VERSION ""

NS_ :

BS_:

BU_: CH DIPF DIPR ETH FC HVI HVS PARTY SDCV VEH VIRT

BO_ 938 HVP_alertMatrix1: 8 VEH
 SG_ HVP_w051_shuntThermistorMia : 50|1@1+ (1,0) [0|1] ""  gtw
 SG_ HVP_w050_fcCtrCloseFailed : 49|1@1+ (1,0) [0|1] ""  gtw
 SG_ HVP_w049_packCtrCloseFailed : 48|1@1+ (1,0) [0|1] ""  gtw
 SG_ HVP_w048_logUploadRequest : 47|1@1+ (1,0) [0|1] ""  gtw
 SG_ HVP_w047_passivePyroDeploy : 46|1@1+ (1,0) [0|1] ""  gtw
 SG_ HVP_w046_shuntOverTemperature : 45|1@1+ (1,0) [0|1] ""  gtw
 SG_ HVP_w045_dcLinkOverVoltage : 44|1@1+ (1,0) [0|1] ""  gtw
 SG_ HVP_w044_fcContactorForceOpen : 43|1@1+ (1,0) [0|1] ""  gtw
 SG_ HVP_w043_packContactorForceOpen : 42|1@1+ (1,0) [0|1] ""  gtw
 SG_ HVP_w042_fcCtrCloseBlocked : 41|1@1+ (1,0) [0|1] ""  gtw
 SG_ HVP_w041_packCtrCloseBlocked : 40|1@1+ (1,0) [0|1] ""  gtw
 SG_ HVP_w040_FcContactorFellOpen : 39|1@1+ (1,0) [0|1] ""  gtw
 SG_ HVP_w039_PackContactorFellOpen : 38|1@1+ (1,0) [0|1] ""  gtw
 SG_ HVP_w038_CpilFault : 37|1@1+ (1,0) [0|1] ""  gtw
 SG_ HVP_w037_pyroFuseFailedToBlow : 36|1@1+ (1,0) [0|1] ""  gtw
 SG_ HVP_w036_pyroFuseBlown : 35|1@1+ (1,0) [0|1] ""  gtw
 SG_ HVP_w035_packContHwFault : 34|1@1+ (1,0) [0|1] ""  gtw
 SG_ HVP_w034_robinOverVoltageFault : 33|1@1+ (1,0) [0|1] ""  gtw
 SG_ HVP_w033_fcContHwFault : 32|1@1+ (1,0) [0|1] ""  gtw
 SG_ HVP_w032_ShuntHwAndBmsMiaFault : 31|1@1+ (1,0) [0|1] ""  gtw
 SG_ HVP_w031_packNegCtrArcFault : 30|1@1+ (1,0) [0|1] ""  gtw
 SG_ HVP_w030_PackPosCtrArcFault : 29|1@1+ (1,0) [0|1] ""  gtw
 SG_ HVP_w029_EnsMiaFault : 28|1@1+ (1,0) [0|1] ""  gtw
 SG_ HVP_w028_PackVoltMismatchFault : 27|1@1+ (1,0) [0|1] ""  gtw
 SG_ HVP_w027_BmsHvsMiaFault : 26|1@1+ (1,0) [0|1] ""  gtw
 SG_ HVP_w026_HvilFault : 25|1@1+ (1,0) [0|1] ""  gtw
 SG_ HVP_w025_VerSupplyFault : 24|1@1+ (1,0) [0|1] ""  gtw
 SG_ HVP_w024_Supply12vFault : 23|1@1+ (1,0) [0|1] ""  gtw
 SG_ HVP_w022_hvsMiaFault : 21|1@1+ (1,0) [0|1] ""  gtw
 SG_ HVP_w021_PyroMiaFault : 20|1@1+ (1,0) [0|1] ""  gtw
 SG_ HVP_w020_ShuntHwMiaFault : 19|1@1+ (1,0) [0|1] ""  gtw
 SG_ HVP_w019_CpFault : 18|1@1+ (1,0) [0|1] ""  gtw
 SG_ HVP_w018_PcsFault : 17|1@1+ (1,0) [0|1] ""  gtw
 SG_ HVP_w017_BmsFault : 16|1@1+ (1,0) [0|1] ""  gtw
 SG_ HVP_w016_PcsMiaFault : 15|1@1+ (1,0) [0|1] ""  gtw
 SG_ HVP_w015_CpMiaFault : 14|1@1+ (1,0) [0|1] ""  gtw
 SG_ HVP_w014_BmsHviMiaFault : 13|1@1+ (1,0) [0|1] ""  gtw
 SG_ HVP_w013_BmbMismatchFault : 12|1@1+ (1,0) [0|1] ""  gtw
 SG_ HVP_w012_SecondaryBmbMiaFault : 11|1@1+ (1,0) [0|1] ""  gtw
 SG_ HVP_w011_PrimaryBmbMiaFault : 10|1@1+ (1,0) [0|1] ""  gtw
 SG_ HVP_w010_UnderVoltageFault : 9|1@1+ (1,0) [0|1] ""  gtw
 SG_ HVP_w009_OverVoltageFault : 8|1@1+ (1,0) [0|1] ""  gtw
 SG_ HVP_w008_OverTemperatureFault : 7|1@1+ (1,0) [0|1] ""  gtw
 SG_ HVP_w007_OverCurrentFault : 6|1@1+ (1,0) [0|1] ""  gtw
 SG_ HVP_w006_OverChargeCurrentFault : 5|1@1+ (1,0) [0|1] ""  gtw
 SG_ HVP_w005_OverDchgCurrentFault : 4|1@1+ (1,0) [0|1] ""  gtw
 SG_ HVP_w004_CrashEvent : 3|1@1+ (1,0) [0|1] ""  gtw
 SG_ HVP_w003_SwAssertion : 2|1@1+ (1,0) [0|1] ""  gtw
 SG_ HVP_w002_UnusedAlert2 : 1|1@1+ (1,0) [0|1] ""  gtw
 SG_ HVP_w001_WatchdogReset : 0|1@1+ (1,0) [0|1] ""  gtw

BO_ 768 BMS_info: 8 VEH
 SG_ BMS_componentId m10 : 48|16@1+ (1,0) [0|65535] ""  gtw
 SG_ BMS_subUsageId m11 : 48|16@1+ (1,0) [0|65535] ""  di
 SG_ BMS_usageId m11 : 32|16@1+ (1,0) [0|65535] ""  gtw
 SG_ BMS_hardwareId m10 : 32|16@1+ (1,0) [0|65535] ""  gtw
 SG_ BMS_bootCrc m20 : 32|32@1+ (1,0) [0|4294967295] ""  gtw
 SG_ BMS_appCrc m13 : 32|32@1+ (1,0) [0|4294967295] ""  gtw
 SG_ BMS_assemblyId m11 : 24|8@1+ (1,0) [0|255] ""  gtw
 SG_ BMS_buildConfigId m10 : 16|16@1+ (1,0) [0|65535] ""  gtw
 SG_ BMS_pcbaId m11 : 16|8@1+ (1,0) [0|255] ""  gtw
 SG_ BMS_buildType m10 : 8|3@1+ (1,0) [0|4] ""  gtw
 SG_ BMS_bootGitHash m18 : 8|56@1+ (1,0) [0|72057594037927935] ""  gtw
 SG_ BMS_platformType m13 : 8|8@1+ (1,0) [0|255] ""  gtw
 SG_ BMS_bootUdsProtoVersion m20 : 8|8@1+ (1,0) [0|255] ""  gtw
 SG_ BMS_appGitHash m17 : 8|56@1+ (1,0) [0|72057594037927935] ""  gtw
 SG_ BMS_infoIndex M : 0|8@1+ (1,0) [0|255] ""  gtw

BO_ 1251 VCRIGHT_seatStatus: 8 VEH
 SG_ VCRIGHT_lumbarDevMaxPumpPressB m4 : 55|1@1+ (1,0) [0|1] ""  gtw
 SG_ VCRIGHT_lumbarDevMaxPumpPressA m4 : 54|1@1+ (1,0) [0|1] ""  gtw
 SG_ VCRIGHT_lumbarGeneralErr m4 : 53|1@1+ (1,0) [0|1] ""  gtw
 SG_ VCRIGHT_frontSeatTrackLog m0 : 52|1@1+ (1,0) [0|1] ""  gtw
 SG_ VCRIGHT_frontSeatLiftLog m2 : 52|1@1+ (1,0) [0|1] ""  gtw
 SG_ VCRIGHT_lumbarMinPErr m4 : 52|1@1+ (1,0) [0|1] ""  gtw
 SG_ VCRIGHT_frontSeatTiltLog m3 : 52|1@1+ (1,0) [0|1] ""  gtw
 SG_ VCRIGHT_frontSeatBackLog m1 : 52|1@1+ (1,0) [0|1] ""  gtw
 SG_ VCRIGHT_lumbarMaxOperatingPErr m4 : 51|1@1+ (1,0) [0|1] ""  gtw
 SG_ VCRIGHT_frontSeatBackCalibrated m1 : 51|1@1+ (1,0) [0|1] ""  gtw
 SG_ VCRIGHT_frontSeatTiltCalibrated m3 : 51|1@1+ (1,0) [0|1] ""  gtw
 SG_ VCRIGHT_frontSeatLiftCalibrated m2 : 51|1@1+ (1,0) [0|1] ""  gtw
 SG_ VCRIGHT_frontSeatTrackCalibrated m0 : 51|1@1+ (1,0) [0|1] ""  gtw
 SG_ VCRIGHT_lumbarOvercurrentErr m4 : 50|1@1+ (1,0) [0|1] ""  gtw
 SG_ VCRIGHT_lumbarMaxPErr m4 : 49|1@1+ (1,0) [0|1] ""  gtw
 SG_ VCRIGHT_frontSeatTrackState m0 : 48|3@1+ (1,0) [0|5] ""  gtw
 SG_ VCRIGHT_frontSeatLiftState m2 : 48|3@1+ (1,0) [0|5] ""  gtw
 SG_ VCRIGHT_lumbarActiveTooLongErr m4 : 48|1@1+ (1,0) [0|1] ""  gtw
 SG_ VCRIGHT_frontSeatTiltState m3 : 48|3@1+ (1,0) [0|5] ""  gtw
 SG_ VCRIGHT_frontSeatBackState m1 : 48|3@1+ (1,0) [0|5] ""  gtw
 SG_ VCRIGHT_frontSeatTiltPosReal m5 : 40|12@1- (0.1,0) [-204.8|204.7] "deg"  gtw
 SG_ VCRIGHT_frontSeatTiltDuty m3 : 36|12@1- (0.1,0) [-204.8|204.7] "%"  gtw
 SG_ VCRIGHT_frontSeatBackDuty m1 : 36|12@1- (0.1,0) [-204.8|204.7] "%"  gtw
 SG_ VCRIGHT_frontSeatLiftDuty m2 : 36|12@1- (0.1,0) [-204.8|204.7] "%"  gtw
 SG_ VCRIGHT_frontSeatTrackDuty m0 : 36|12@1- (0.1,0) [-204.8|204.7] "%"  gtw
 SG_ VCRIGHT_lumbarBPressureHpa m4 : 32|16@1+ (1,0) [0|65535] ""  gtw
 SG_ VCRIGHT_frontSeatLiftPosReal m5 : 28|12@1- (1,0) [-2048|2047] "mm"  gtw
 SG_ VCRIGHT_frontSeatLiftCurrent m2 : 24|12@1- (0.01,0) [-20.48|20.47] "A"  gtw
 SG_ VCRIGHT_frontSeatTrackCurrent m0 : 24|12@1- (0.01,0) [-20.48|20.47] "A"  gtw
 SG_ VCRIGHT_frontSeatBackCurrent m1 : 24|12@1- (0.01,0) [-20.48|20.47] "A"  gtw
 SG_ VCRIGHT_frontSeatTiltCurrent m3 : 24|12@1- (0.01,0) [-20.48|20.47] "A"  gtw
 SG_ VCRIGHT_frontSeatBackPosReal m5 : 16|12@1- (0.1,0) [-204.8|204.7] "deg"  gtw
 SG_ VCRIGHT_lumbarAPressureHpa m4 : 16|16@1+ (1,0) [0|65535] ""  gtw
 SG_ VCRIGHT_frontSeatTiltPos m3 : 8|16@1- (1,0) [-32768|32767] ""  gtw
 SG_ VCRIGHT_lumbarBState m4 : 8|3@1+ (1,0) [0|5] ""  gtw
 SG_ VCRIGHT_frontSeatBackPos m1 : 8|16@1- (1,0) [-32768|32767] ""  gtw
 SG_ VCRIGHT_frontSeatTrackPos m0 : 8|16@1- (1,0) [-32768|32767] ""  gtw
 SG_ VCRIGHT_frontSeatLiftPos m2 : 8|16@1- (1,0) [-32768|32767] ""  gtw
 SG_ VCRIGHT_frontSeatTrackPosReal m5 : 3|12@1- (1,0) [-2048|2047] "mm"  gtw
 SG_ VCRIGHT_lumbarAState m4 : 3|3@1+ (1,0) [0|5] ""  gtw
 SG_ VCRIGHT_seatStatusIndex M : 0|3@1+ (1,0) [0|5] ""  X

BO_ 850 BMS_energyStatus: 8 VEH
 SG_ BMS_idealEnergyRemaining m0 : 48|16@1+ (0.02,0) [0|102.2] "KWh"  gtw
 SG_ BMS_nominalEnergyRemaining m0 : 32|16@1+ (0.02,0) [0|102.2] "KWh"  gtw
 SG_ BMS_expectedEnergyRemaining m1 : 32|16@1+ (0.02,0) [0|102.2] "KWh"  gtw
 SG_ BMS_energyBuffer m1 : 16|16@1+ (0.01,0) [0|25.4] "KWh"  gtw
 SG_ BMS_nominalFullPackEnergy m0 : 16|16@1+ (0.02,0) [0|102.2] "KWh"  gtw
 SG_ BMS_energyIndex M : 0|8@1+ (1,0) [0|2] ""  X

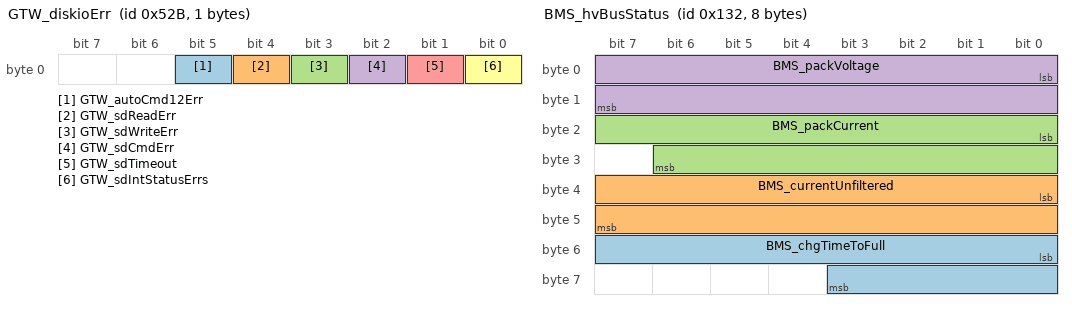
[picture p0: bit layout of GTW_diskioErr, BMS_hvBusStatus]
BO_ 1323 GTW_diskioErr: 1 VEH
 SG_ GTW_autoCmd12Err : 5|1@1+ (1,0) [0|1] ""  X
 SG_ GTW_sdReadErr : 4|1@1+ (1,0) [0|1] ""  X
 SG_ GTW_sdWriteErr : 3|1@1+ (1,0) [0|1] ""  X
 SG_ GTW_sdCmdErr : 2|1@1+ (1,0) [0|1] ""  X
 SG_ GTW_sdTimeout : 1|1@1+ (1,0) [0|1] ""  X
 SG_ GTW_sdIntStatusErrs : 0|1@1+ (1,0) [0|1] ""  X

BO_ 1328 VCSEC_alertLog: 8 VEH
 SG_ VCSEC_a041_CPULoadNVMMTask m41 : 56|8@1+ (1,0) [0|255] ""  gtw
 SG_ VCSEC_a022_TaskInitError4 m22 : 56|8@1+ (1,0) [0|255] ""  gtw
 SG_ VCSEC_a179_signingKeySlot m179 : 56|8@1+ (1,0) [0|255] ""  gtw
 SG_ VCSEC_a180_signingKeySlot m180 : 56|8@1+ (1,0) [0|255] ""  gtw
 SG_ VCSEC_a042_UsageNVMMTask m42 : 56|8@1+ (1,0) [0|255] ""  gtw
 SG_ VCSEC_a041_CPULoad1000msTask m41 : 48|8@1+ (1,0) [0|255] ""  gtw
 SG_ VCSEC_a042_UsageUDSTask m42 : 48|8@1+ (1,0) [0|255] ""  gtw
 SG_ VCSEC_a022_TaskInitError3 m22 : 48|8@1+ (1,0) [0|255] ""  gtw
 SG_ VCSEC_a000_alertDataW2 m0 : 48|16@1+ (1,0) [0|65535] ""  X
 SG_ VCSEC_a003_Data m3 : 48|16@1+ (1,0) [0|65535] ""  gtw
 SG_ VCSEC_a179_whitelistSlot m179 : 48|8@1+ (1,0) [0|255] ""  gtw
 SG_ VCSEC_a180_whitelistSlot m180 : 48|8@1+ (1,0) [0|255] ""  gtw
 SG_ VCSEC_a178_signingKeySlot m178 : 48|8@1+ (1,0) [0|255] ""  gtw
 SG_ VCSEC_a063_faulted m63 : 43|1@1+ (1,0) [0|1] ""  gtw
 SG_ VCSEC_a063_stuckActive m63 : 42|1@1+ (1,0) [0|1] ""  gtw
 SG_ VCSEC_a063_indeterminate m63 : 41|1@1+ (1,0) [0|1] ""  gtw
 SG_ VCSEC_a044_CallTrace1 m44 : 40|24@1+ (1,0) [0|16777215] ""  gtw
 SG_ VCSEC_a042_Usage1000msTask m42 : 40|8@1+ (1,0) [0|255] ""  gtw
 SG_ VCSEC_a063_disconnected m63 : 40|1@1+ (1,0) [0|1] ""  gtw
 SG_ VCSEC_a022_TaskInitError2 m22 : 40|8@1+ (1,0) [0|255] ""  gtw
 SG_ VCSEC_a059_current m59 : 40|12@1+ (0.05,0) [0|204.75] "A"  gtw
 SG_ VCSEC_a046_CallTrace1 m46 : 40|24@1+ (1,0) [0|16777215] ""  gtw
 SG_ VCSEC_a041_CPULoad100msTask m41 : 40|8@1+ (1,0) [0|255] ""  gtw
 SG_ VCSEC_a045_CallTrace1 m45 : 40|24@1+ (1,0) [0|16777215] ""  gtw
 SG_ VCSEC_a043_CallTrace1 m43 : 40|24@1+ (1,0) [0|16777215] ""  gtw
 SG_ VCSEC_a169_assertFailure m169 : 33|1@1+ (1,0) [0|1] ""  gtw
 SG_ VCSEC_a170_assertFailure m170 : 33|1@1+ (1,0) [0|1] ""  gtw
 SG_ VCSEC_a168_assertFailure m168 : 33|1@1+ (1,0) [0|1] ""  gtw
 SG_ VCSEC_a167_assertFailure m167 : 33|1@1+ (1,0) [0|1] ""  gtw
 SG_ VCSEC_a166_assertFailure m166 : 33|1@1+ (1,0) [0|1] ""  gtw
 SG_ VCSEC_a209_assertFailCount m209 : 32|8@1+ (1,0) [0|255] ""  gtw
 SG_ VCSEC_a168_advNotScheduled m168 : 32|1@1+ (1,0) [0|1] ""  gtw
 SG_ VCSEC_a041_CPULoad10msTask m41 : 32|8@1+ (1,0) [0|255] ""  gtw
 SG_ VCSEC_a167_advNotScheduled m167 : 32|1@1+ (1,0) [0|1] ""  gtw
 SG_ VCSEC_a206_assertFailCount m206 : 32|8@1+ (1,0) [0|255] ""  gtw
 SG_ VCSEC_a208_assertFailCount m208 : 32|8@1+ (1,0) [0|255] ""  gtw
 SG_ VCSEC_a169_advNotScheduled m169 : 32|1@1+ (1,0) [0|1] ""  gtw
 SG_ VCSEC_a170_advNotScheduled m170 : 32|1@1+ (1,0) [0|1] ""  gtw
 SG_ VCSEC_a003_LineNumber m3 : 32|16@1+ (1,0) [0|65535] ""  gtw
 SG_ VCSEC_a000_alertDataW1 m0 : 32|16@1+ (1,0) [0|65535] ""  X
 SG_ VCSEC_a063_ADCVoltage m63 : 32|8@1+ (0.025,0) [0|6.375] "V"  gtw
 SG_ VCSEC_a042_Usage100msTask m42 : 32|8@1+ (1,0) [0|255] ""  gtw
 SG_ VCSEC_a166_advNotScheduled m166 : 32|1@1+ (1,0) [0|1] ""  gtw
 SG_ VCSEC_a207_assertFailCount m207 : 32|8@1+ (1,0) [0|255] ""  gtw
 SG_ VCSEC_a022_TaskInitError1 m22 : 32|8@1+ (1,0) [0|255] ""  gtw
 SG_ VCSEC_a168_macIDChanged m168 : 31|1@1+ (1,0) [0|1] ""  gtw
 SG_ VCSEC_a166_macIDChanged m166 : 31|1@1+ (1,0) [0|1] ""  gtw
 SG_ VCSEC_a169_macIDChanged m169 : 31|1@1+ (1,0) [0|1] ""  gtw
 SG_ VCSEC_a170_macIDChanged m170 : 31|1@1+ (1,0) [0|1] ""  gtw
 SG_ VCSEC_a167_macIDChanged m167 : 31|1@1+ (1,0) [0|1] ""  gtw
 SG_ VCSEC_a168_radioNotOn m168 : 30|1@1+ (1,0) [0|1] ""  gtw
 SG_ VCSEC_a167_radioNotOn m167 : 30|1@1+ (1,0) [0|1] ""  gtw
 SG_ VCSEC_a166_radioNotOn m166 : 30|1@1+ (1,0) [0|1] ""  gtw
 SG_ VCSEC_a170_radioNotOn m170 : 30|1@1+ (1,0) [0|1] ""  gtw
 SG_ VCSEC_a169_radioNotOn m169 : 30|1@1+ (1,0) [0|1] ""  gtw
 SG_ VCSEC_a169_externalRequest m169 : 29|1@1+ (1,0) [0|1] ""  gtw
 SG_ VCSEC_a170_externalRequest m170 : 29|1@1+ (1,0) [0|1] ""  gtw
 SG_ VCSEC_a168_externalRequest m168 : 29|1@1+ (1,0) [0|1] ""  gtw
 SG_ VCSEC_a167_externalRequest m167 : 29|1@1+ (1,0) [0|1] ""  gtw
 SG_ VCSEC_a166_externalRequest m166 : 29|1@1+ (1,0) [0|1] ""  gtw
 SG_ VCSEC_a166_gattAtrbtMissing m166 : 28|1@1+ (1,0) [0|1] ""  gtw
 SG_ VCSEC_a059_resistanceEstimate m59 : 28|12@1+ (0.00244,0) [0|9.9918] "Ohms"  gtw
 SG_ VCSEC_a169_gattAtrbtMissing m169 : 28|1@1+ (1,0) [0|1] ""  gtw
 SG_ VCSEC_a170_gattAtrbtMissing m170 : 28|1@1+ (1,0) [0|1] ""  gtw
 SG_ VCSEC_a168_gattAtrbtMissing m168 : 28|1@1+ (1,0) [0|1] ""  gtw
 SG_ VCSEC_a167_gattAtrbtMissing m167 : 28|1@1+ (1,0) [0|1] ""  gtw
 SG_ VCSEC_a166_gattSrvcCmdTimeout m166 : 27|1@1+ (1,0) [0|1] ""  gtw
 SG_ VCSEC_a021_Task1000msMissed m21 : 27|1@1+ (1,0) [0|1] ""  gtw
 SG_ VCSEC_a170_gattSrvcCmdTimeout m170 : 27|1@1+ (1,0) [0|1] ""  gtw
 SG_ VCSEC_a169_gattSrvcCmdTimeout m169 : 27|1@1+ (1,0) [0|1] ""  gtw
 SG_ VCSEC_a116_VEH_logging1Hz m116 : 27|1@1+ (1,0) [0|1] ""  gtw
 SG_ VCSEC_a168_gattSrvcCmdTimeout m168 : 27|1@1+ (1,0) [0|1] ""  gtw
 SG_ VCSEC_a167_gattSrvcCmdTimeout m167 : 27|1@1+ (1,0) [0|1] ""  gtw
 SG_ VCSEC_a169_gapPeripCmdTimeout m169 : 26|1@1+ (1,0) [0|1] ""  gtw
 SG_ VCSEC_a170_gapPeripCmdTimeout m170 : 26|1@1+ (1,0) [0|1] ""  gtw
 SG_ VCSEC_a021_Task1000msStarved m21 : 26|1@1+ (1,0) [0|1] ""  gtw
 SG_ VCSEC_a167_gapPeripCmdTimeout m167 : 26|1@1+ (1,0) [0|1] ""  gtw
 SG_ VCSEC_a116_VEH_switchStatus m116 : 26|1@1+ (1,0) [0|1] ""  gtw
 SG_ VCSEC_a168_gapPeripCmdTimeout m168 : 26|1@1+ (1,0) [0|1] ""  gtw
 SG_ VCSEC_a166_gapPeripCmdTimeout m166 : 26|1@1+ (1,0) [0|1] ""  gtw
 SG_ VCSEC_a167_gapCommandTimeout m167 : 25|1@1+ (1,0) [0|1] ""  gtw
 SG_ VCSEC_a166_gapCommandTimeout m166 : 25|1@1+ (1,0) [0|1] ""  gtw
 SG_ VCSEC_a117_VEH_intrusionSensorSt m117 : 25|1@1+ (1,0) [0|1] ""  gtw
 SG_ VCSEC_a021_Task1000msLate m21 : 25|1@1+ (1,0) [0|1] ""  gtw
 SG_ VCSEC_a169_gapCommandTimeout m169 : 25|1@1+ (1,0) [0|1] ""  gtw
 SG_ VCSEC_a170_gapCommandTimeout m170 : 25|1@1+ (1,0) [0|1] ""  gtw
 SG_ VCSEC_a116_VEH_restraintStatus m116 : 25|1@1+ (1,0) [0|1] ""  gtw
 SG_ VCSEC_a168_gapCommandTimeout m168 : 25|1@1+ (1,0) [0|1] ""  gtw
 SG_ VCSEC_a120_VEH_speed m120 : 24|1@1+ (1,0) [0|1] ""  gtw
 SG_ VCSEC_a166_reasonMIA m166 : 24|1@1+ (1,0) [0|1] ""  gtw
 SG_ VCSEC_a022_TaskInitError0 m22 : 24|8@1+ (1,0) [0|255] ""  gtw
 SG_ VCSEC_a170_reasonMIA m170 : 24|1@1+ (1,0) [0|1] ""  gtw
 SG_ VCSEC_a169_reasonMIA m169 : 24|1@1+ (1,0) [0|1] ""  gtw
 SG_ VCSEC_a063_switchType m63 : 24|8@1+ (1,0) [0|255] ""  gtw
 SG_ VCSEC_a167_reasonMIA m167 : 24|1@1+ (1,0) [0|1] ""  gtw
 SG_ VCSEC_a042_Usage10msTask m42 : 24|8@1+ (1,0) [0|255] ""  gtw
 SG_ VCSEC_a021_Task100msMissed m21 : 24|1@1+ (1,0) [0|1] ""  gtw
 SG_ VCSEC_a209_assertSubcause m209 : 24|8@1+ (1,0) [0|255] ""  gtw
 SG_ VCSEC_a206_assertSubcause m206 : 24|8@1+ (1,0) [0|255] ""  gtw
 SG_ VCSEC_a113_VEH_powertrainControl m113 : 24|1@1+ (1,0) [0|1] ""  gtw
 SG_ VCSEC_a041_CPULoad1msTask m41 : 24|8@1+ (1,0) [0|255] ""  gtw
 SG_ VCSEC_a140_multipleTriesToAuth m140 : 24|1@1+ (1,0) [0|1] ""  gtw
 SG_ VCSEC_a181_fault m181 : 24|4@1+ (1,0) [0|10] ""  gtw
 SG_ VCSEC_a207_assertSubcause m207 : 24|8@1+ (1,0) [0|255] ""  gtw
 SG_ VCSEC_a177_signingKeySlot m177 : 24|8@1+ (1,0) [0|255] ""  gtw
 SG_ VCSEC_a197_errorInconfrmtn m197 : 24|8@1+ (1,0) [0|255] ""  gtw
 SG_ VCSEC_a168_reasonMIA m168 : 24|1@1+ (1,0) [0|1] ""  gtw
 SG_ VCSEC_a208_assertSubcause m208 : 24|8@1+ (1,0) [0|255] ""  gtw
 SG_ VCSEC_a116_VEH_seatHeatStatus m116 : 24|1@1+ (1,0) [0|1] ""  gtw
 SG_ VCSEC_a118_VEH_systemStatus m118 : 24|1@1+ (1,0) [0|1] ""  gtw
 SG_ VCSEC_a117_VEH_switchStatus m117 : 24|1@1+ (1,0) [0|1] ""  gtw
 SG_ VCSEC_a113_VEH_chassisControl m113 : 23|1@1+ (1,0) [0|1] ""  gtw
 SG_ VCSEC_a021_Task100msStarved m21 : 23|1@1+ (1,0) [0|1] ""  gtw
 SG_ VCSEC_a117_VEH_doorStatus m117 : 23|1@1+ (1,0) [0|1] ""  gtw
 SG_ VCSEC_a118_VEH_12VBattStatus m118 : 23|1@1+ (1,0) [0|1] ""  gtw
 SG_ VCSEC_a140_cardRmvdB4RecvingID m140 : 23|1@1+ (1,0) [0|1] ""  gtw
 SG_ VCSEC_a116_VEH_doorStatus m116 : 23|1@1+ (1,0) [0|1] ""  gtw
 SG_ VCSEC_a120_PARTY_speed m120 : 23|1@1+ (1,0) [0|1] ""  gtw
 SG_ VCSEC_a140_cardRmvdB4SndingReqID m140 : 22|1@1+ (1,0) [0|1] ""  gtw
 SG_ VCSEC_a116_VEH_thsStatus m116 : 22|1@1+ (1,0) [0|1] ""  gtw
 SG_ VCSEC_a117_VEH_seatStatus m117 : 22|1@1+ (1,0) [0|1] ""  gtw
 SG_ VCSEC_a113_VEH_ventCntlReq m113 : 22|1@1+ (1,0) [0|1] ""  gtw
 SG_ VCSEC_a021_Task100msLate m21 : 22|1@1+ (1,0) [0|1] ""  gtw
 SG_ VCSEC_a118_VEH_vehicleStatus m118 : 22|1@1+ (1,0) [0|1] ""  gtw
 SG_ VCSEC_a120_VEH_status m120 : 22|1@1+ (1,0) [0|1] ""  gtw
 SG_ VCSEC_a015_NVMMWriteFailed m15 : 21|1@1+ (1,0) [0|1] ""  gtw
 SG_ VCSEC_a021_Task10msMissed m21 : 21|1@1+ (1,0) [0|1] ""  gtw
 SG_ VCSEC_a197_confrmtnTimeout m197 : 21|1@1+ (1,0) [0|1] ""  gtw
 SG_ VCSEC_a117_VEH_lightStatus m117 : 21|1@1+ (1,0) [0|1] ""  gtw
 SG_ VCSEC_a113_VEH_solarData m113 : 21|1@1+ (1,0) [0|1] ""  gtw
 SG_ VCSEC_a140_cardRmvdB4SndingChaln m140 : 21|1@1+ (1,0) [0|1] ""  gtw
 SG_ VCSEC_a012_ExternalReset m12 : 21|1@1+ (1,0) [0|1] ""  gtw
 SG_ VCSEC_a118_VEH_LVPowerState m118 : 21|1@1+ (1,0) [0|1] ""  gtw
 SG_ VCSEC_a120_PARTY_locStatus m120 : 21|1@1+ (1,0) [0|1] ""  gtw
 SG_ VCSEC_a116_VEH_seatStatus m116 : 21|1@1+ (1,0) [0|1] ""  gtw
 SG_ VCSEC_a161_packetTooShort m161 : 20|1@1+ (1,0) [0|1] ""  gtw
 SG_ VCSEC_a012_DebugReset m12 : 20|1@1+ (1,0) [0|1] ""  gtw
 SG_ VCSEC_a120_VEH_torque m120 : 20|1@1+ (1,0) [0|1] ""  gtw
 SG_ VCSEC_a117_VEH_restraintStatus m117 : 20|1@1+ (1,0) [0|1] ""  gtw
 SG_ VCSEC_a021_Task10msStarved m21 : 20|1@1+ (1,0) [0|1] ""  gtw
 SG_ VCSEC_a144_endDiscoCmdStatus m144 : 20|1@1+ (1,0) [0|1] ""  gtw
 SG_ VCSEC_a107_VEH_bmbMinMax m107 : 20|1@1+ (1,0) [0|1] ""  gtw
 SG_ VCSEC_a142_endDiscoCmdStatus m142 : 20|1@1+ (1,0) [0|1] ""  gtw
 SG_ VCSEC_a118_VEH_okToUseHighPwr m118 : 20|1@1+ (1,0) [0|1] ""  gtw
 SG_ VCSEC_a159_packetTooShort m159 : 20|1@1+ (1,0) [0|1] ""  gtw
 SG_ VCSEC_a145_endDiscoCmdStatus m145 : 20|1@1+ (1,0) [0|1] ""  gtw
 SG_ VCSEC_a162_packetTooShort m162 : 20|1@1+ (1,0) [0|1] ""  gtw
 SG_ VCSEC_a015_NVMMMemOverflow m15 : 20|1@1+ (1,0) [0|1] ""  gtw
 SG_ VCSEC_a143_endDiscoCmdStatus m143 : 20|1@1+ (1,0) [0|1] ""  gtw
 SG_ VCSEC_a116_VEH_lightStatus m116 : 20|1@1+ (1,0) [0|1] ""  gtw
 SG_ VCSEC_a158_packetTooShort m158 : 20|1@1+ (1,0) [0|1] ""  gtw
 SG_ VCSEC_a113_VEH_vehicleControl2 m113 : 20|1@1+ (1,0) [0|1] ""  gtw
 SG_ VCSEC_a140_cardRmvdB4AuthComplet m140 : 20|1@1+ (1,0) [0|1] ""  gtw
 SG_ VCSEC_a197_connHandleMismatch m197 : 20|1@1+ (1,0) [0|1] ""  gtw
 SG_ VCSEC_a116_VEH_LVPowerState m116 : 19|1@1+ (1,0) [0|1] ""  gtw
 SG_ VCSEC_a161_packetTooLong m161 : 19|1@1+ (1,0) [0|1] ""  gtw
 SG_ VCSEC_a012_CheckstopReset m12 : 19|1@1+ (1,0) [0|1] ""  gtw
 SG_ VCSEC_a143_discoDoneEventError m143 : 19|1@1+ (1,0) [0|1] ""  gtw
 SG_ VCSEC_a114_PARTY_party3 m114 : 19|1@1+ (1,0) [0|1] ""  gtw
 SG_ VCSEC_a142_discoDoneEventError m142 : 19|1@1+ (1,0) [0|1] ""  gtw
 SG_ VCSEC_a104_PARTY_control m104 : 19|1@1+ (1,0) [0|1] ""  gtw
 SG_ VCSEC_a145_discoDoneEventError m145 : 19|1@1+ (1,0) [0|1] ""  gtw
 SG_ VCSEC_a021_Task10msLate m21 : 19|1@1+ (1,0) [0|1] ""  gtw
 SG_ VCSEC_a015_NVMMRecordUpgraded m15 : 19|1@1+ (1,0) [0|1] ""  gtw
 SG_ VCSEC_a108_PARTY_torque m108 : 19|1@1+ (1,0) [0|1] ""  gtw
 SG_ VCSEC_a118_VEH_status m118 : 19|1@1+ (1,0) [0|1] ""  gtw
 SG_ VCSEC_a113_VEH_vehicleControl m113 : 19|1@1+ (1,0) [0|1] ""  gtw
 SG_ VCSEC_a144_discoDoneEventError m144 : 19|1@1+ (1,0) [0|1] ""  gtw
 SG_ VCSEC_a109_PARTY_collision m109 : 19|1@1+ (1,0) [0|1] ""  gtw
 SG_ VCSEC_a158_packetTooLong m158 : 19|1@1+ (1,0) [0|1] ""  gtw
 SG_ VCSEC_a120_PARTY_torque m120 : 19|1@1+ (1,0) [0|1] ""  gtw
 SG_ VCSEC_a117_VEH_LVPowerState m117 : 19|1@1+ (1,0) [0|1] ""  gtw
 SG_ VCSEC_a162_packetTooLong m162 : 19|1@1+ (1,0) [0|1] ""  gtw
 SG_ VCSEC_a159_packetTooLong m159 : 19|1@1+ (1,0) [0|1] ""  gtw
 SG_ VCSEC_a140_authenticationTimeout m140 : 19|1@1+ (1,0) [0|1] ""  gtw
 SG_ VCSEC_a107_VEH_thermalStatus m107 : 19|1@1+ (1,0) [0|1] ""  gtw
 SG_ VCSEC_a116_VEH_hvacRequest m116 : 18|1@1+ (1,0) [0|1] ""  gtw
 SG_ VCSEC_a114_VEH_wheelSpeeds m114 : 18|1@1+ (1,0) [0|1] ""  gtw
 SG_ VCSEC_a143_discoCmdStatus m143 : 18|1@1+ (1,0) [0|1] ""  gtw
 SG_ VCSEC_a103_VEH_status m103 : 18|1@1+ (1,0) [0|1] ""  gtw
 SG_ VCSEC_a193_failedToSendWlist m193 : 18|1@1+ (1,0) [0|1] ""  gtw
 SG_ VCSEC_a012_SoftwareReset m12 : 18|1@1+ (1,0) [0|1] ""  gtw
 SG_ VCSEC_a110_VEH_time m110 : 18|1@1+ (1,0) [0|1] ""  gtw
 SG_ VCSEC_a145_discoCmdStatus m145 : 18|1@1+ (1,0) [0|1] ""  gtw
 SG_ VCSEC_a113_VEH_chargeRequest m113 : 18|1@1+ (1,0) [0|1] ""  gtw
 SG_ VCSEC_a021_Task1msMissed m21 : 18|1@1+ (1,0) [0|1] ""  gtw
 SG_ VCSEC_a158_unknownHCICode m158 : 18|1@1+ (1,0) [0|1] ""  gtw
 SG_ VCSEC_a192_failedToSendWlist m192 : 18|1@1+ (1,0) [0|1] ""  gtw
 SG_ VCSEC_a104_VEH_thermalStatus m104 : 18|1@1+ (1,0) [0|1] ""  gtw
 SG_ VCSEC_a194_failedToSendWlist m194 : 18|1@1+ (1,0) [0|1] ""  gtw
 SG_ VCSEC_a191_failedToSendWlist m191 : 18|1@1+ (1,0) [0|1] ""  gtw
 SG_ VCSEC_a162_unknownHCICode m162 : 18|1@1+ (1,0) [0|1] ""  gtw
 SG_ VCSEC_a015_NVMMVersionMismatch m15 : 18|1@1+ (1,0) [0|1] ""  gtw
 SG_ VCSEC_a109_PARTY_nearDeploy m109 : 18|1@1+ (1,0) [0|1] ""  gtw
 SG_ VCSEC_a159_unknownHCICode m159 : 18|1@1+ (1,0) [0|1] ""  gtw
 SG_ VCSEC_a161_unknownHCICode m161 : 18|1@1+ (1,0) [0|1] ""  gtw
 SG_ VCSEC_a118_VEH_sensors m118 : 18|1@1+ (1,0) [0|1] ""  gtw
 SG_ VCSEC_a119_VEH_rightStalk m119 : 18|1@1+ (1,0) [0|1] ""  gtw
 SG_ VCSEC_a106_VEH_thermalStatus m106 : 18|1@1+ (1,0) [0|1] ""  gtw
 SG_ VCSEC_a120_PARTY_systemStatus m120 : 18|1@1+ (1,0) [0|1] ""  gtw
 SG_ VCSEC_a142_discoCmdStatus m142 : 18|1@1+ (1,0) [0|1] ""  gtw
 SG_ VCSEC_a107_VEH_status m107 : 18|1@1+ (1,0) [0|1] ""  gtw
 SG_ VCSEC_a140_authenticationFailed m140 : 18|1@1+ (1,0) [0|1] ""  gtw
 SG_ VCSEC_a117_VEH_hvacBlowerFdb m117 : 18|1@1+ (1,0) [0|1] ""  gtw
 SG_ VCSEC_a102_VEH_sensorStatus m102 : 18|1@1+ (1,0) [0|1] ""  gtw
 SG_ VCSEC_a144_discoCmdStatus m144 : 18|1@1+ (1,0) [0|1] ""  gtw
 SG_ VCSEC_a108_VEH_torque m108 : 18|1@1+ (1,0) [0|1] ""  gtw
 SG_ VCSEC_a105_VEH_chNm m105 : 17|1@1+ (1,0) [0|1] ""  gtw
 SG_ VCSEC_a010_UnderVoltageTimeout m10 : 17|1@1+ (1,0) [0|1] ""  gtw
 SG_ VCSEC_a100_PARTY m100 : 17|1@1+ (1,0) [0|1] ""  gtw
 SG_ VCSEC_a119_VEH_leftStalk m119 : 17|1@1+ (1,0) [0|1] ""  gtw
 SG_ VCSEC_a161_incompleteHeader m161 : 17|1@1+ (1,0) [0|1] ""  gtw
 SG_ VCSEC_a114_PARTY_wheelSpeeds m114 : 17|1@1+ (1,0) [0|1] ""  gtw
 SG_ VCSEC_a113_VEH_hvacRequest m113 : 17|1@1+ (1,0) [0|1] ""  gtw
 SG_ VCSEC_a107_VEH_vehNm m107 : 17|1@1+ (1,0) [0|1] ""  gtw
 SG_ VCSEC_a102_VEH_feedbackStatus m102 : 17|1@1+ (1,0) [0|1] ""  gtw
 SG_ VCSEC_a021_Task1msStarved m21 : 17|1@1+ (1,0) [0|1] ""  gtw
 SG_ VCSEC_a194_WlistingDevice m194 : 17|1@1+ (1,0) [0|1] ""  gtw
 SG_ VCSEC_a013_ClearQueueFull m13 : 17|1@1+ (1,0) [0|1] ""  gtw
 SG_ VCSEC_a142_discoDoneEvent m142 : 17|1@1+ (1,0) [0|1] ""  gtw
 SG_ VCSEC_a098_VEH_temperature m98 : 17|1@1+ (1,0) [0|1] ""  gtw
 SG_ VCSEC_a115_VEH_authentication m115 : 17|1@1+ (1,0) [0|1] ""  gtw
 SG_ VCSEC_a002_PowerOnReset m2 : 17|1@1+ (1,0) [0|1] ""  gtw
 SG_ VCSEC_a191_WlistingDevice m191 : 17|1@1+ (1,0) [0|1] ""  gtw
 SG_ VCSEC_a109_PARTY_inertial2 m109 : 17|1@1+ (1,0) [0|1] ""  gtw
 SG_ VCSEC_a012_FlashError m12 : 17|1@1+ (1,0) [0|1] ""  gtw
 SG_ VCSEC_a110_VEH_carConfig m110 : 17|1@1+ (1,0) [0|1] ""  gtw
 SG_ VCSEC_a158_incompleteHeader m158 : 17|1@1+ (1,0) [0|1] ""  gtw
 SG_ VCSEC_a097_VEH_state m97 : 17|1@1+ (1,0) [0|1] ""  gtw
 SG_ VCSEC_a143_discoDoneEvent m143 : 17|1@1+ (1,0) [0|1] ""  gtw
 SG_ VCSEC_a144_discoDoneEvent m144 : 17|1@1+ (1,0) [0|1] ""  gtw
 SG_ VCSEC_a192_WlistingDevice m192 : 17|1@1+ (1,0) [0|1] ""  gtw
 SG_ VCSEC_a106_VEH_thermalControl m106 : 17|1@1+ (1,0) [0|1] ""  gtw
 SG_ VCSEC_a060_resetUnlocked m60 : 17|1@1+ (1,0) [0|1] ""  gtw
 SG_ VCSEC_a015_NVMMCRCMismatch m15 : 17|1@1+ (1,0) [0|1] ""  gtw
 SG_ VCSEC_a116_VEH_vehNm m116 : 17|1@1+ (1,0) [0|1] ""  gtw
 SG_ VCSEC_a118_VEH_lighting m118 : 17|1@1+ (1,0) [0|1] ""  gtw
 SG_ VCSEC_a112_VEH_status m112 : 17|1@1+ (1,0) [0|1] ""  gtw
 SG_ VCSEC_a108_VEH_thermalControl m108 : 17|1@1+ (1,0) [0|1] ""  gtw
 SG_ VCSEC_a111_VEH_status m111 : 17|1@1+ (1,0) [0|1] ""  gtw
 SG_ VCSEC_a159_incompleteHeader m159 : 17|1@1+ (1,0) [0|1] ""  gtw
 SG_ VCSEC_a162_incompleteHeader m162 : 17|1@1+ (1,0) [0|1] ""  gtw
 SG_ VCSEC_a117_VEH_vehNm m117 : 17|1@1+ (1,0) [0|1] ""  gtw
 SG_ VCSEC_a103_VEH_vehNm m103 : 17|1@1+ (1,0) [0|1] ""  gtw
 SG_ VCSEC_a120_VEH_systemStatus m120 : 17|1@1+ (1,0) [0|1] ""  gtw
 SG_ VCSEC_a145_discoDoneEvent m145 : 17|1@1+ (1,0) [0|1] ""  gtw
 SG_ VCSEC_a140_keyNotPairedToTheCar m140 : 17|1@1+ (1,0) [0|1] ""  gtw
 SG_ VCSEC_a193_WlistingDevice m193 : 17|1@1+ (1,0) [0|1] ""  gtw
 SG_ VCSEC_a104_VEH_bodyControls m104 : 17|1@1+ (1,0) [0|1] ""  gtw
 SG_ VCSEC_a117_PARTY_epbmStatus m117 : 16|1@1+ (1,0) [0|1] ""  gtw
 SG_ VCSEC_a178_publicKey m178 : 16|32@1+ (1,0) [0|4294967295] ""  gtw
 SG_ VCSEC_a097_VEH_HVStatus m97 : 16|1@1+ (1,0) [0|1] ""  gtw
 SG_ VCSEC_a194_clearWlist m194 : 16|1@1+ (1,0) [0|1] ""  gtw
 SG_ VCSEC_a103_VEH_hvsNm m103 : 16|1@1+ (1,0) [0|1] ""  gtw
 SG_ VCSEC_a209_assertCause m209 : 16|4@1+ (1,0) [0|15] ""  gtw
 SG_ VCSEC_a206_assertCause m206 : 16|4@1+ (1,0) [0|15] ""  gtw
 SG_ VCSEC_a166_resetCount m166 : 16|8@1+ (1,0) [0|255] ""  gtw
 SG_ VCSEC_a193_clearWlist m193 : 16|1@1+ (1,0) [0|1] ""  gtw
 SG_ VCSEC_a144_endDiscoverable m144 : 16|1@1+ (1,0) [0|1] ""  gtw
 SG_ VCSEC_a059_voltageDrop m59 : 16|12@1+ (0.005443676098,0) [0|22.29185] "V"  gtw
 SG_ VCSEC_a158_transportError m158 : 16|1@1+ (1,0) [0|1] ""  gtw
 SG_ VCSEC_a030_logId m30 : 16|4@1+ (1,0) [0|15] ""  gtw
 SG_ VCSEC_a100_VEH m100 : 16|1@1+ (1,0) [0|1] ""  gtw
 SG_ VCSEC_a197_connectionChannel m197 : 16|4@1+ (1,0) [0|15] ""  gtw
 SG_ VCSEC_a205_connectionChannel m205 : 16|4@1+ (1,0) [0|15] ""  gtw
 SG_ VCSEC_a115_VEH_vehNm m115 : 16|1@1+ (1,0) [0|1] ""  gtw
 SG_ VCSEC_a168_resetCount m168 : 16|8@1+ (1,0) [0|255] ""  gtw
 SG_ VCSEC_a108_VEH_temperature m108 : 16|1@1+ (1,0) [0|1] ""  gtw
 SG_ VCSEC_a208_assertCause m208 : 16|4@1+ (1,0) [0|15] ""  gtw
 SG_ VCSEC_a134_certificateFault m134 : 16|2@1+ (1,0) [0|2] ""  gtw
 SG_ VCSEC_a063_switchChannel m63 : 16|8@1+ (1,0) [0|255] ""  gtw
 SG_ VCSEC_a003_AssertID m3 : 16|16@1+ (1,0) [0|65535] ""  gtw
 SG_ VCSEC_a118_VEH_vehNm m118 : 16|1@1+ (1,0) [0|1] ""  gtw
 SG_ VCSEC_a105_VEH_states m105 : 16|1@1+ (1,0) [0|1] ""  gtw
 SG_ VCSEC_a177_newWhitelistSlot m177 : 16|8@1+ (1,0) [0|255] ""  gtw
 SG_ VCSEC_a179_permission m179 : 16|32@1+ (1,0) [0|4294967295] ""  gtw
 SG_ VCSEC_a181_channel m181 : 16|8@1+ (1,0) [0|255] ""  gtw
 SG_ VCSEC_a044_CallTrace0 m44 : 16|24@1+ (1,0) [0|16777215] ""  gtw
 SG_ VCSEC_a001_InternalWatchdog m1 : 16|1@1+ (1,0) [0|1] ""  gtw
 SG_ VCSEC_a101_VEH_state m101 : 16|1@1+ (1,0) [0|1] ""  gtw
 SG_ VCSEC_a192_clearWlist m192 : 16|1@1+ (1,0) [0|1] ""  gtw
 SG_ VCSEC_a182_cryptoTaskStackUsage m182 : 16|8@1+ (1,0) [0|255] ""  gtw
 SG_ VCSEC_a159_transportError m159 : 16|1@1+ (1,0) [0|1] ""  gtw
 SG_ VCSEC_a167_resetCount m167 : 16|8@1+ (1,0) [0|255] ""  gtw
 SG_ VCSEC_a133_alarmTriggerReason m133 : 16|4@1+ (1,0) [0|8] ""  gtw
 SG_ VCSEC_a162_transportError m162 : 16|1@1+ (1,0) [0|1] ""  gtw
 SG_ VCSEC_a161_transportError m161 : 16|1@1+ (1,0) [0|1] ""  gtw
 SG_ VCSEC_a021_Task1msLate m21 : 16|1@1+ (1,0) [0|1] ""  gtw
 SG_ VCSEC_a210_whiteListChannel m210 : 16|5@1+ (1,0) [0|31] ""  gtw
 SG_ VCSEC_a109_PARTY_status m109 : 16|1@1+ (1,0) [0|1] ""  gtw
 SG_ VCSEC_a113_VEH_ethNm m113 : 16|1@1+ (1,0) [0|1] ""  gtw
 SG_ VCSEC_a191_clearWlist m191 : 16|1@1+ (1,0) [0|1] ""  gtw
 SG_ VCSEC_a169_resetCount m169 : 16|8@1+ (1,0) [0|255] ""  gtw
 SG_ VCSEC_a143_endDiscoverable m143 : 16|1@1+ (1,0) [0|1] ""  gtw
 SG_ VCSEC_a170_resetCount m170 : 16|8@1+ (1,0) [0|255] ""  gtw
 SG_ VCSEC_a106_VEH_dcdcStatus m106 : 16|1@1+ (1,0) [0|1] ""  gtw
 SG_ VCSEC_a041_CPULoadTotal m41 : 16|8@1+ (1,0) [0|255] ""  gtw
 SG_ VCSEC_a120_PARTY_chassisCntl m120 : 16|1@1+ (1,0) [0|1] ""  gtw
 SG_ VCSEC_a140_keyDidNotIdentify m140 : 16|1@1+ (1,0) [0|1] ""  gtw
 SG_ VCSEC_a180_permission m180 : 16|32@1+ (1,0) [0|4294967295] ""  gtw
 SG_ VCSEC_a015_NVMMRecordNotFound m15 : 16|1@1+ (1,0) [0|1] ""  gtw
 SG_ VCSEC_a045_CallTrace0 m45 : 16|24@1+ (1,0) [0|16777215] ""  gtw
 SG_ VCSEC_a174_resetSource m174 : 16|4@1+ (1,0) [0|10] ""  gtw
 SG_ VCSEC_a119_VEH_steerAngle m119 : 16|1@1+ (1,0) [0|1] ""  gtw
 SG_ VCSEC_a046_CallTrace0 m46 : 16|24@1+ (1,0) [0|16777215] ""  gtw
 SG_ VCSEC_a142_endDiscoverable m142 : 16|1@1+ (1,0) [0|1] ""  gtw
 SG_ VCSEC_a114_PARTY_status m114 : 16|1@1+ (1,0) [0|1] ""  gtw
 SG_ VCSEC_a116_PARTY_epbmStatus m116 : 16|1@1+ (1,0) [0|1] ""  gtw
 SG_ VCSEC_a104_VEH_chNm m104 : 16|1@1+ (1,0) [0|1] ""  gtw
 SG_ VCSEC_a042_Usage1msTask m42 : 16|8@1+ (1,0) [0|255] ""  gtw
 SG_ VCSEC_a000_alertDataW0 m0 : 16|16@1+ (1,0) [0|65535] ""  X
 SG_ VCSEC_a098_VEH_thermalControl m98 : 16|1@1+ (1,0) [0|1] ""  gtw
 SG_ VCSEC_a107_VEH_hvsNm m107 : 16|1@1+ (1,0) [0|1] ""  gtw
 SG_ VCSEC_a043_CallTrace0 m43 : 16|24@1+ (1,0) [0|16777215] ""  gtw
 SG_ VCSEC_a022_TaskInitErrorCount m22 : 16|8@1+ (1,0) [0|255] ""  gtw
 SG_ VCSEC_a013_LogQueueFull m13 : 16|1@1+ (1,0) [0|1] ""  gtw
 SG_ VCSEC_a172_resetSource m172 : 16|4@1+ (1,0) [0|10] ""  gtw
 SG_ VCSEC_a060_lockoutDisabled m60 : 16|1@1+ (1,0) [0|1] ""  gtw
 SG_ VCSEC_a099_VEH_oocStatus m99 : 16|1@1+ (1,0) [0|1] ""  gtw
 SG_ VCSEC_a012_ClockError m12 : 16|1@1+ (1,0) [0|1] ""  gtw
 SG_ VCSEC_a175_resetSource m175 : 16|4@1+ (1,0) [0|10] ""  gtw
 SG_ VCSEC_a064_busBitField m64 : 16|8@1+ (1,0) [0|255] ""  gtw
 SG_ VCSEC_a110_VEH_carState m110 : 16|1@1+ (1,0) [0|1] ""  gtw
 SG_ VCSEC_a207_assertCause m207 : 16|4@1+ (1,0) [0|15] ""  gtw
 SG_ VCSEC_a102_VEH_faults m102 : 16|1@1+ (1,0) [0|1] ""  gtw
 SG_ VCSEC_a111_VEH_internalStatus m111 : 16|1@1+ (1,0) [0|1] ""  gtw
 SG_ VCSEC_a145_endDiscoverable m145 : 16|1@1+ (1,0) [0|1] ""  gtw
 SG_ VCSEC_a002_CPUUndervoltage m2 : 16|1@1+ (1,0) [0|1] ""  gtw
 SG_ VCSEC_a173_resetSource m173 : 16|4@1+ (1,0) [0|10] ""  gtw
 SG_ VCSEC_a010_UnderVoltageDetected m10 : 16|1@1+ (1,0) [0|1] ""  gtw
 SG_ VCSEC_a112_VEH_internalStatus m112 : 16|1@1+ (1,0) [0|1] ""  gtw
 SG_ VCSEC_alertType : 15|1@1+ (1,0) [0|1] ""  gtw
 SG_ VCSEC_alertID M : 0|8@1+ (1,0) [0|210] ""  gtw

BO_ 306 BMS_hvBusStatus: 8 VEH
 SG_ BMS_chgTimeToFull : 48|12@1+ (0.01666667,0) [0|68.25001365] "Hours"  gtw
 SG_ BMS_currentUnfiltered : 32|16@1- (0.05,-1000) [-2638.3|638.3] "A"  X
 SG_ BMS_packCurrent : 16|15@1- (0.1,-1000) [-2638.3|638.3] "A"  di
 SG_ BMS_packVoltage : 0|16@1+ (0.01,0) [0|655.35] "V"  di

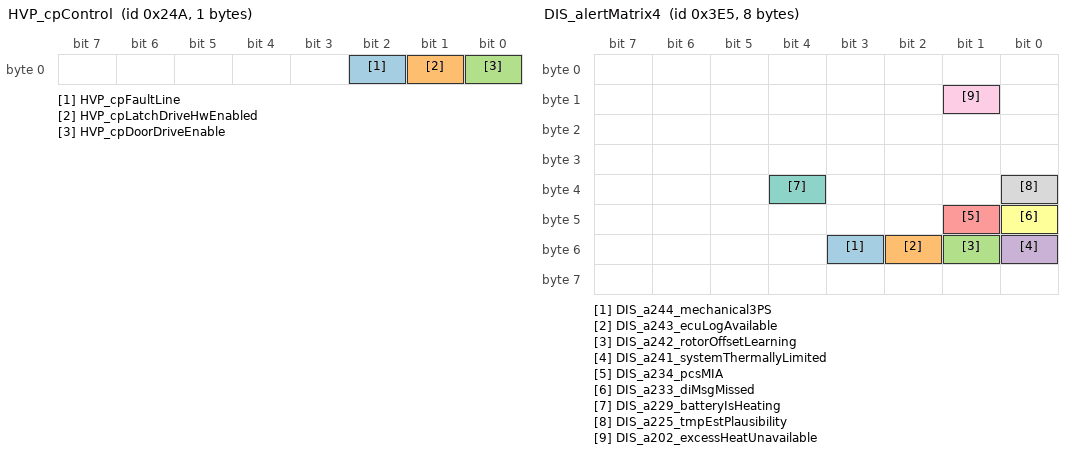
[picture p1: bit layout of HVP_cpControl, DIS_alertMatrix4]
BO_ 586 HVP_cpControl: 1 VEH
 SG_ HVP_cpFaultLine : 2|1@1+ (1,0) [0|1] ""  dbg
 SG_ HVP_cpLatchDriveHwEnabled : 1|1@1+ (1,0) [0|1] ""  gtw
 SG_ HVP_cpDoorDriveEnable : 0|1@1+ (1,0) [0|1] ""  gtw

BO_ 831 FC_alertMatrix2: 8 VEH
 SG_ FC_a065_userData : 0|1@1+ (1,0) [0|1] ""  gtw

BO_ 1355 SCM_alertMatrix2: 8 VEH
 SG_ SCM_a128_unused128 : 63|1@1+ (1,0) [0|1] ""  gtw
 SG_ SCM_a127_unused127 : 62|1@1+ (1,0) [0|1] ""  gtw
 SG_ SCM_a126_unused126 : 61|1@1+ (1,0) [0|1] ""  gtw
 SG_ SCM_a125_unused125 : 60|1@1+ (1,0) [0|1] ""  gtw
 SG_ SCM_a124_unused124 : 59|1@1+ (1,0) [0|1] ""  gtw
 SG_ SCM_a123_unused123 : 58|1@1+ (1,0) [0|1] ""  gtw
 SG_ SCM_a122_unused122 : 57|1@1+ (1,0) [0|1] ""  gtw
 SG_ SCM_a121_unused121 : 56|1@1+ (1,0) [0|1] ""  gtw
 SG_ SCM_a120_unused120 : 55|1@1+ (1,0) [0|1] ""  gtw
 SG_ SCM_a119_unused119 : 54|1@1+ (1,0) [0|1] ""  gtw
 SG_ SCM_a118_unused118 : 53|1@1+ (1,0) [0|1] ""  gtw
 SG_ SCM_a117_unused117 : 52|1@1+ (1,0) [0|1] ""  gtw
 SG_ SCM_a116_unused116 : 51|1@1+ (1,0) [0|1] ""  gtw
 SG_ SCM_a115_unused115 : 50|1@1+ (1,0) [0|1] ""  gtw
 SG_ SCM_a114_unused114 : 49|1@1+ (1,0) [0|1] ""  gtw
 SG_ SCM_a113_unused113 : 48|1@1+ (1,0) [0|1] ""  gtw
 SG_ SCM_a112_unused112 : 47|1@1+ (1,0) [0|1] ""  gtw
 SG_ SCM_a111_unused111 : 46|1@1+ (1,0) [0|1] ""  gtw
 SG_ SCM_a110_unused110 : 45|1@1+ (1,0) [0|1] ""  gtw
 SG_ SCM_a109_unused109 : 44|1@1+ (1,0) [0|1] ""  gtw
 SG_ SCM_a108_unused108 : 43|1@1+ (1,0) [0|1] ""  gtw
 SG_ SCM_a107_unused107 : 42|1@1+ (1,0) [0|1] ""  gtw
 SG_ SCM_a106_unused106 : 41|1@1+ (1,0) [0|1] ""  gtw
 SG_ SCM_a105_unused105 : 40|1@1+ (1,0) [0|1] ""  gtw
 SG_ SCM_a104_unused104 : 39|1@1+ (1,0) [0|1] ""  gtw
 SG_ SCM_a103_unused103 : 38|1@1+ (1,0) [0|1] ""  gtw
 SG_ SCM_a102_unused102 : 37|1@1+ (1,0) [0|1] ""  gtw
 SG_ SCM_a101_unused101 : 36|1@1+ (1,0) [0|1] ""  gtw
 SG_ SCM_a100_unused100 : 35|1@1+ (1,0) [0|1] ""  gtw
 SG_ SCM_a099_unused99 : 34|1@1+ (1,0) [0|1] ""  gtw
 SG_ SCM_a098_unused98 : 33|1@1+ (1,0) [0|1] ""  gtw
 SG_ SCM_a097_unused97 : 32|1@1+ (1,0) [0|1] ""  gtw
 SG_ SCM_a096_unused96 : 31|1@1+ (1,0) [0|1] ""  gtw
 SG_ SCM_a095_unused95 : 30|1@1+ (1,0) [0|1] ""  gtw
 SG_ SCM_a094_unused94 : 29|1@1+ (1,0) [0|1] ""  gtw
 SG_ SCM_a093_unused93 : 28|1@1+ (1,0) [0|1] ""  gtw
 SG_ SCM_a092_cabEnableDeasserted : 27|1@1+ (1,0) [0|1] ""  gtw
 SG_ SCM_a091_voltageRiseDetection : 26|1@1+ (1,0) [0|1] ""  gtw
 SG_ SCM_a090_negCordOT : 25|1@1+ (1,0) [0|1] ""  gtw
 SG_ SCM_a089_posCordOT : 24|1@1+ (1,0) [0|1] ""  gtw
 SG_ SCM_a088_negCordTempRationality : 23|1@1+ (1,0) [0|1] ""  gtw
 SG_ SCM_a087_posCordTempRationality : 22|1@1+ (1,0) [0|1] ""  gtw
 SG_ SCM_a086_lccResetDetected : 21|1@1+ (1,0) [0|1] ""  gtw
 SG_ SCM_a085_unused85 : 20|1@1+ (1,0) [0|1] ""  gtw
 SG_ SCM_a084_unused84 : 19|1@1+ (1,0) [0|1] ""  gtw
 SG_ SCM_a083_chargeCurrentLimited : 18|1@1+ (1,0) [0|1] ""  gtw
 SG_ SCM_a082_VbatUV : 17|1@1+ (1,0) [0|1] ""  gtw
 SG_ SCM_a081_rmsInputVoltageHigh : 16|1@1+ (1,0) [0|1] ""  gtw
 SG_ SCM_a080_lccFaulted : 15|1@1+ (1,0) [0|1] ""  gtw
 SG_ SCM_a079_unexpectedVbat : 14|1@1+ (1,0) [0|1] ""  gtw
 SG_ SCM_a078_voltageMatchTimeout : 13|1@1+ (1,0) [0|1] ""  gtw
 SG_ SCM_a077_unexpectedVbatBehavior : 12|1@1+ (1,0) [0|1] ""  gtw
 SG_ SCM_a076_bmsMIA : 11|1@1+ (1,0) [0|1] ""  gtw
 SG_ SCM_a075_leakageTestAbsDecayLow : 10|1@1+ (1,0) [0|1] ""  gtw
 SG_ SCM_a074_isoVDiffHi : 9|1@1+ (1,0) [0|1] ""  gtw
 SG_ SCM_a073_lccMIA : 8|1@1+ (1,0) [0|1] ""  gtw
 SG_ SCM_a072_gtwMIA : 7|1@1+ (1,0) [0|1] ""  gtw
 SG_ SCM_a071_chargerMIA : 6|1@1+ (1,0) [0|1] ""  gtw
 SG_ SCM_a070_vStageRationalityV2 : 5|1@1+ (1,0) [0|1] ""  gtw
 SG_ SCM_a069_vStageRationalityV1 : 4|1@1+ (1,0) [0|1] ""  gtw
 SG_ SCM_a068_vBatRationalityStage4 : 3|1@1+ (1,0) [0|1] ""  gtw
 SG_ SCM_a067_vBatRationalityStage3 : 2|1@1+ (1,0) [0|1] ""  gtw
 SG_ SCM_a066_vBatRationalityStage2 : 1|1@1+ (1,0) [0|1] ""  gtw
 SG_ SCM_a065_vBatRationalityStage1 : 0|1@1+ (1,0) [0|1] ""  gtw

BO_ 505 VCSEC_requests: 1 VEH
 SG_ VCSEC_driveAttemptedWithoutAuth : 2|1@1+ (1,0) [0|1] ""  gtw
 SG_ VCSEC_chargePortRequest : 0|2@1+ (1,0) [0|3] ""  bms

BO_ 997 DIS_alertMatrix4: 8 VEH
 SG_ DIS_a244_mechanical3PS : 51|1@1+ (1,0) [0|1] ""  gtw
 SG_ DIS_a243_ecuLogAvailable : 50|1@1+ (1,0) [0|1] ""  gtw
 SG_ DIS_a242_rotorOffsetLearning : 49|1@1+ (1,0) [0|1] ""  gtw
 SG_ DIS_a241_systemThermallyLimited : 48|1@1+ (1,0) [0|1] ""  gtw
 SG_ DIS_a234_pcsMIA : 41|1@1+ (1,0) [0|1] ""  gtw
 SG_ DIS_a233_diMsgMissed : 40|1@1+ (1,0) [0|1] ""  gtw
 SG_ DIS_a229_batteryIsHeating : 36|1@1+ (1,0) [0|1] ""  gtw
 SG_ DIS_a225_tmpEstPlausibility : 32|1@1+ (1,0) [0|1] ""  gtw
 SG_ DIS_a202_excessHeatUnavailable : 9|1@1+ (1,0) [0|1] ""  gtw

BO_ 984 UI_elevationStatus: 2 VEH
 SG_ UI_elevation : 0|16@1+ (1,0) [0|65535] "m"  vcleft

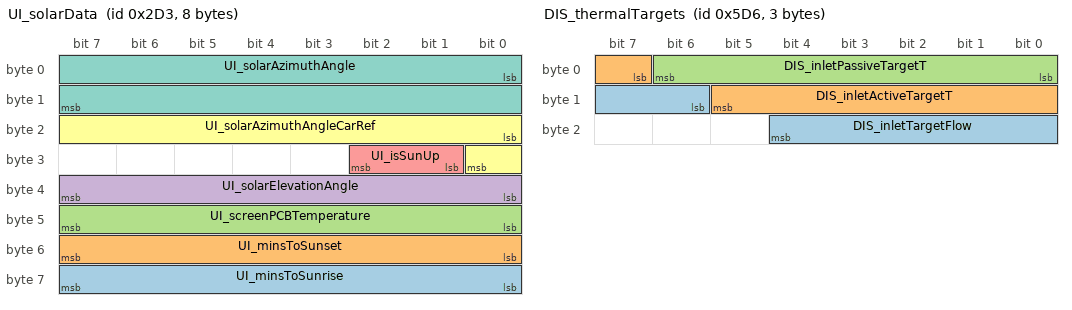
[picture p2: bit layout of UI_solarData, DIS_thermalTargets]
BO_ 723 UI_solarData: 8 VEH
 SG_ UI_minsToSunrise : 56|8@1+ (10,0) [0|2550] "min"  vcsec
 SG_ UI_minsToSunset : 48|8@1+ (10,0) [0|2550] "min"  vcsec
 SG_ UI_screenPCBTemperature : 40|8@1- (0.5,40.0) [-20|100] "degC"  vcright
 SG_ UI_solarElevationAngle : 32|8@1- (1,0) [-128|126] "degrees"  vcleft
 SG_ UI_isSunUp : 25|2@1+ (1,0) [0|3] ""  vcleft
 SG_ UI_solarAzimuthAngleCarRef : 16|9@1- (1,0) [-256|254] "degrees"  vcright
 SG_ UI_solarAzimuthAngle : 0|16@1- (1,0) [-32767|32767] "degrees"  vcright

BO_ 2004 PMS_debug: 8 VEH
 SG_ PMS_switchingActive m102 : 59|1@1+ (1,0) [0|1] ""  X
 SG_ PMS_torqueOutOfMap m102 : 58|1@1+ (1,0) [0|1] ""  dbg
 SG_ PMS_resolverDiMIA m105 : 57|1@1+ (1,0) [0|1] ""  X
 SG_ PMS_cpu10kHzMax m14 : 56|8@1+ (0.4,0) [0|102] "%"  dbg
 SG_ PMS_cpu100HzMin m13 : 56|8@1+ (0.4,0) [0|102] "%"  dbg
 SG_ PMS_statorT m101 : 56|8@1+ (1,-40) [-40|200] "degC"  dbg
 SG_ PMS_crsAlertState m102 : 56|2@1+ (1,0) [0|3] ""  dbg
 SG_ PMS_lmSatCoeff m100 : 56|8@1+ (0.00391,0) [0|0.99705] "1"  dbg
 SG_ PMS_resolverClaMIA m105 : 56|1@1+ (1,0) [0|1] ""  X
 SG_ PMS_resolverPhaseOutOfSpec m105 : 55|1@1+ (1,0) [0|1] ""  X
 SG_ PMS_resolverNoCarrier m105 : 54|1@1+ (1,0) [0|1] ""  X
 SG_ PMS_cpu20kHzMin m14 : 48|8@1+ (0.4,0) [0|102] "%"  dbg
 SG_ PMS_cpu1kHzAvg m13 : 48|8@1+ (0.4,0) [0|102] "%"  dbg
 SG_ PMS_resolverOffsetExt m105 : 48|6@1+ (0.053,0) [0|3.3] "V"  X
 SG_ PMS_torqueCommand m102 : 40|13@1- (0.25,0.0) [-750|750] "Nm"  dbg
 SG_ PMS_cpu20kHzMax m14 : 40|8@1+ (0.4,0) [0|102] "%"  dbg
 SG_ PMS_motorRPM m101 : 40|16@1- (1,0) [-32768|32767] "RPM"  dbg
 SG_ PMS_torqueReversalWindow m12 : 40|16@1- (0.05,0.0) [-1638.4|1638.35] "NmS"  dbg
 SG_ PMS_torqueRegenMargin m10 : 40|16@1- (0.0244,0.0) [-799.5392|799.5148] "Nm"  dbg
 SG_ PMS_iDQmagnitude m100 : 40|16@1- (0.0939,0) [-3076.9152|3076.8213] "A"  dbg
 SG_ PMS_torqueAccelAvg m11 : 40|16@1- (0.05,0.0) [-1638.4|1638.35] "Nm"  dbg
 SG_ PMS_resolverOffsetSin m105 : 40|6@1+ (0.053,0) [0|3.3] "V"  X
 SG_ PMS_cpu100HzMax m13 : 40|8@1+ (0.4,0) [0|102] "%"  dbg
 SG_ PMS_resolverOffsetCos m105 : 32|6@1+ (0.053,0) [0|3.3] "V"  X
 SG_ PMS_cpu10kHzAvg m13 : 32|8@1+ (0.4,0) [0|102] "%"  dbg
 SG_ PMS_cpu10HzMin m14 : 32|8@1+ (0.4,0) [0|102] "%"  dbg
 SG_ PMS_offsetIb m102 : 28|12@1- (0.1,0) [-204.8|204.7] "A"  dbg
 SG_ PMS_udsStackMax m22 : 24|16@1+ (1,0) [0|65535] "words"  dbg
 SG_ PMS_resolverExcitationGain m105 : 24|7@1+ (0.063,0) [0|5] "1"  X
 SG_ PMS_xcpStackMax m23 : 24|16@1+ (1,0) [0|65535] "words"  dbg
 SG_ PMS_torqueAccelWindow m11 : 24|16@1- (0.05,0.0) [-1638.4|1638.35] "NmS"  dbg
 SG_ PMS_idleStackMax m21 : 24|16@1+ (1,0) [0|65535] "words"  dbg
 SG_ PMS_lookupSlipFreqMax m101 : 24|16@1- (0.005,0.0) [-163.84|163.835] "Hz"  dbg
 SG_ PMS_torqueReversalMarginR m10 : 24|16@1- (0.0244,0.0) [-799.5392|799.5148] "Nm"  dbg
 SG_ PMS_cpu1kHzMin m13 : 24|8@1+ (0.4,0) [0|102] "%"  dbg
 SG_ PMS_sysStackMax m20 : 24|16@1+ (1,0) [0|65535] "words"  dbg
 SG_ PMS_torqueDecelAvg m12 : 24|16@1- (0.05,0.0) [-1638.4|1638.35] "Nm"  dbg
 SG_ PMS_Ib m100 : 24|16@1- (0.0939,0) [-3076.9152|3076.8213] "A"  dbg
 SG_ PMS_cpu10HzAvg m14 : 24|8@1+ (0.4,0) [0|102] "%"  dbg
 SG_ PMS_resolverSpeedError m104 : 16|16@1- (0.75,0.0) [-25000|25000] "RPM"  X
 SG_ PMS_cpu20kHzAvg m13 : 16|8@1+ (0.4,0) [0|102] "%"  dbg
 SG_ PMS_offsetIa m102 : 16|12@1- (0.1,0) [-204.8|204.7] "A"  dbg
 SG_ PMS_crsOff m103 : 16|16@1+ (1,0) [0|65535] ""  dbg
 SG_ PMS_resolverCommonGain m105 : 16|7@1+ (0.063,0) [0|8] "1"  X
 SG_ PMS_cpu10HzMax m14 : 16|8@1+ (0.4,0) [0|102] "%"  dbg
 SG_ PMS_p006_cruise m103 : 13|1@1+ (1,0) [0|1] ""  dbg
 SG_ PMS_p005_shift m103 : 12|1@1+ (1,0) [0|1] ""  dbg
 SG_ PMS_p004_regen m103 : 11|1@1+ (1,0) [0|1] ""  dbg
 SG_ PMS_p003_dir m103 : 10|1@1+ (1,0) [0|1] ""  dbg
 SG_ PMS_p002_speed m103 : 9|1@1+ (1,0) [0|1] ""  dbg
 SG_ PMS_torqueReversalMarginF m10 : 8|16@1- (0.0244,0.0) [-799.5392|799.5148] "Nm"  dbg
 SG_ PMS_Ia m100 : 8|16@1- (0.0939,0) [-3076.9152|3076.8213] "A"  dbg
 SG_ PMS_xcpStackSize m23 : 8|16@1+ (1,0) [0|65535] "words"  dbg
 SG_ PMS_resolverElecAngleError m104 : 8|8@1- (0.025,0.0) [-3.14159|3.14159] "rad"  X
 SG_ PMS_idleStackSize m21 : 8|16@1+ (1,0) [0|65535] "words"  dbg
 SG_ PMS_torqueDecelWindow m12 : 8|16@1- (0.05,0.0) [-1638.4|1638.35] "NmS"  dbg
 SG_ PMS_cpu1kHzMax m13 : 8|8@1+ (0.4,0) [0|102] "%"  dbg
 SG_ PMS_TPdriverCommandFR m11 : 8|16@1- (0.0244,0.0) [-799.5392|799.5148] "Nm"  dbg
 SG_ PMS_resolverPhaseAngle m105 : 8|8@1+ (0.00616,0) [0|1.5708] "rad"  X
 SG_ PMS_pedalPos m102 : 8|8@1+ (0.4,0) [0|102] "%"  dbg
 SG_ PMS_slipFrequency m101 : 8|16@1- (0.005,0.0) [-163.84|163.835] "Hz"  dbg
 SG_ PMS_sysStackSize m20 : 8|16@1+ (1,0) [0|65535] "words"  dbg
 SG_ PMS_udsStackSize m22 : 8|16@1+ (1,0) [0|65535] "words"  dbg
 SG_ PMS_cpu10kHzMin m15 : 8|8@1+ (0.4,0) [0|102] "%"  dbg
 SG_ PMS_p001_accel m103 : 8|1@1+ (1,0) [0|1] ""  dbg
 SG_ PMS_cpu100HzAvg m14 : 8|8@1+ (0.4,0) [0|102] "%"  dbg
 SG_ PMS_debugSelector M : 0|8@1+ (1,0) [10|105] ""  dbg

BO_ 1360 VCRIGHT_alertLog: 8 VEH
 SG_ VCRIGHT_a166_AUTO_DOWN_HELD m166 : 62|1@1+ (1,0) [0|1] ""  gtw
 SG_ VCRIGHT_a151_pinchV3InUse m151 : 61|1@1+ (1,0) [0|1] ""  gtw
 SG_ VCRIGHT_a150_pinchV3InUse m150 : 61|1@1+ (1,0) [0|1] ""  gtw
 SG_ VCRIGHT_a166_SOFT_STOP_OVERRIDE m166 : 61|1@1+ (1,0) [0|1] ""  gtw
 SG_ VCRIGHT_a166_CAL_CLEAR_ENC_LOSS m166 : 60|1@1+ (1,0) [0|1] ""  gtw
 SG_ VCRIGHT_a322_railVoltage m322 : 59|5@1+ (0.5,0) [0|16] "V"  gtw
 SG_ VCRIGHT_a323_railVoltage m323 : 59|5@1+ (0.5,0) [0|16] "V"  gtw
 SG_ VCRIGHT_a320_railVoltage m320 : 59|5@1+ (0.5,0) [0|16] "V"  gtw
 SG_ VCRIGHT_a321_railVoltage m321 : 59|5@1+ (0.5,0) [0|16] "V"  gtw
 SG_ VCRIGHT_a166_SHORT_DROP_FAILED m166 : 59|1@1+ (1,0) [0|1] ""  gtw
 SG_ VCRIGHT_a166_PINCH_TABLE_REJECTE m166 : 58|1@1+ (1,0) [0|1] ""  gtw
 SG_ VCRIGHT_a166_INT_SWITCH_IGNORED m166 : 57|1@1+ (1,0) [0|1] ""  gtw
 SG_ VCRIGHT_a041_CPULoadNVMMTask m41 : 56|8@1+ (1,0) [0|255] ""  gtw
 SG_ VCRIGHT_a042_UsageNVMMTask m42 : 56|8@1+ (1,0) [0|255] ""  gtw
 SG_ VCRIGHT_a022_TaskInitError4 m22 : 56|8@1+ (1,0) [0|255] ""  gtw
 SG_ VCRIGHT_a166_REAR_SWITCH_IGNORED m166 : 56|1@1+ (1,0) [0|1] ""  gtw
 SG_ VCRIGHT_a200_phantomTicks m200 : 53|11@1- (1,0) [-1024|1023] "ticks"  gtw
 SG_ VCRIGHT_a266_seatMotorState m266 : 52|3@1+ (1,0) [0|5] ""  gtw
 SG_ VCRIGHT_a181_latchClawStatus m181 : 52|1@1+ (1,0) [0|1] ""  gtw
 SG_ VCRIGHT_a238_lumbarBState m238 : 52|3@1+ (1,0) [0|5] ""  gtw
 SG_ VCRIGHT_a180_latchClawStatus m180 : 52|1@1+ (1,0) [0|1] ""  gtw
 SG_ VCRIGHT_a265_seatMotorState m265 : 52|3@1+ (1,0) [0|5] ""  gtw
 SG_ VCRIGHT_a237_lumbarBState m237 : 52|3@1+ (1,0) [0|5] ""  gtw
 SG_ VCRIGHT_a263_seatMotorState m263 : 52|3@1+ (1,0) [0|5] ""  gtw
 SG_ VCRIGHT_a269_seatMotorState m269 : 52|3@1+ (1,0) [0|5] ""  gtw
 SG_ VCRIGHT_a270_seatMotorState m270 : 52|3@1+ (1,0) [0|5] ""  gtw
 SG_ VCRIGHT_a236_lumbarBState m236 : 52|3@1+ (1,0) [0|5] ""  gtw
 SG_ VCRIGHT_a264_seatMotorState m264 : 52|3@1+ (1,0) [0|5] ""  gtw
 SG_ VCRIGHT_a267_seatMotorState m267 : 52|3@1+ (1,0) [0|5] ""  gtw
 SG_ VCRIGHT_a218_motorDutyCycle m218 : 52|10@1+ (0.1,0) [0|100] "A"  gtw
 SG_ VCRIGHT_a268_seatMotorState m268 : 52|3@1+ (1,0) [0|5] ""  gtw
 SG_ VCRIGHT_a151_powerDeriv2Accum m151 : 51|10@1+ (1000,0) [0|1023000] "ticks"  gtw
 SG_ VCRIGHT_a166_pinchV2PctAboveExp m166 : 51|5@1+ (1,0) [0|31] ""  gtw
 SG_ VCRIGHT_a150_powerDeriv2Accum m150 : 51|10@1+ (1000,0) [0|1023000] "ticks"  gtw
 SG_ VCRIGHT_a220_seatSwitchForward m220 : 50|2@1+ (1,0) [0|3] ""  gtw
 SG_ VCRIGHT_a322_powerDerivAccum m322 : 50|9@1+ (100,0) [0|51100] "-"  gtw
 SG_ VCRIGHT_a223_seatSwitchForward m223 : 50|2@1+ (1,0) [0|3] ""  gtw
 SG_ VCRIGHT_a230_seatSwitchForward m230 : 50|2@1+ (1,0) [0|3] ""  gtw
 SG_ VCRIGHT_a229_seatSwitchForward m229 : 50|2@1+ (1,0) [0|3] ""  gtw
 SG_ VCRIGHT_a222_seatSwitchForward m222 : 50|2@1+ (1,0) [0|3] ""  gtw
 SG_ VCRIGHT_a231_seatSwitchForward m231 : 50|2@1+ (1,0) [0|3] ""  gtw
 SG_ VCRIGHT_a228_seatSwitchForward m228 : 50|2@1+ (1,0) [0|3] ""  gtw
 SG_ VCRIGHT_a323_powerDeriv2Accum m323 : 50|9@1+ (2000,0) [0|1022000] "-"  gtw
 SG_ VCRIGHT_a320_powerDerivAccum m320 : 50|9@1+ (100,0) [0|51100] "-"  gtw
 SG_ VCRIGHT_a221_seatSwitchForward m221 : 50|2@1+ (1,0) [0|3] ""  gtw
 SG_ VCRIGHT_a321_powerDeriv2Accum m321 : 50|9@1+ (2000,0) [0|1022000] "-"  gtw
 SG_ VCRIGHT_a237_lumbarAState m237 : 49|3@1+ (1,0) [0|5] ""  gtw
 SG_ VCRIGHT_a238_lumbarAState m238 : 49|3@1+ (1,0) [0|5] ""  gtw
 SG_ VCRIGHT_a236_lumbarAState m236 : 49|3@1+ (1,0) [0|5] ""  gtw
 SG_ VCRIGHT_a220_seatSwitchBack m220 : 48|2@1+ (1,0) [0|3] ""  gtw
 SG_ VCRIGHT_a168_pinchV3InUse m168 : 48|1@1+ (1,0) [0|1] ""  gtw
 SG_ VCRIGHT_a237_lumbarDiagStatus m237 : 48|1@1+ (1,0) [0|1] ""  gtw
 SG_ VCRIGHT_a216_byte3 m216 : 48|8@1+ (1,0) [0|255] ""  gtw
 SG_ VCRIGHT_a221_seatSwitchBack m221 : 48|2@1+ (1,0) [0|3] ""  gtw
 SG_ VCRIGHT_a000_alertDataW2 m0 : 48|16@1+ (1,0) [0|65535] ""  X
 SG_ VCRIGHT_a238_lumbarDiagStatus m238 : 48|1@1+ (1,0) [0|1] ""  gtw
 SG_ VCRIGHT_a222_seatSwitchBack m222 : 48|2@1+ (1,0) [0|3] ""  gtw
 SG_ VCRIGHT_a167_pinchV3InUse m167 : 48|1@1+ (1,0) [0|1] ""  gtw
 SG_ VCRIGHT_a236_lumbarDiagStatus m236 : 48|1@1+ (1,0) [0|1] ""  gtw
 SG_ VCRIGHT_a231_seatSwitchBack m231 : 48|2@1+ (1,0) [0|3] ""  gtw
 SG_ VCRIGHT_a228_seatSwitchBack m228 : 48|2@1+ (1,0) [0|3] ""  gtw
 SG_ VCRIGHT_a164_calibratedVoltage m164 : 48|6@1+ (0.25,0) [0|16] "V"  gtw
 SG_ VCRIGHT_a041_CPULoad1000msTask m41 : 48|8@1+ (1,0) [0|255] ""  gtw
 SG_ VCRIGHT_a180_latchStatus m180 : 48|4@1+ (1,0) [0|8] ""  gtw
 SG_ VCRIGHT_a042_UsageUDSTask m42 : 48|8@1+ (1,0) [0|255] ""  gtw
 SG_ VCRIGHT_a022_TaskInitError3 m22 : 48|8@1+ (1,0) [0|255] ""  gtw
 SG_ VCRIGHT_a223_seatSwitchBack m223 : 48|2@1+ (1,0) [0|3] ""  gtw
 SG_ VCRIGHT_a181_latchStatus m181 : 48|4@1+ (1,0) [0|8] ""  gtw
 SG_ VCRIGHT_a229_seatSwitchBack m229 : 48|2@1+ (1,0) [0|3] ""  gtw
 SG_ VCRIGHT_a003_Data m3 : 48|16@1+ (1,0) [0|65535] ""  gtw
 SG_ VCRIGHT_a230_seatSwitchBack m230 : 48|2@1+ (1,0) [0|3] ""  gtw
 SG_ VCRIGHT_a200_motorPosition m200 : 46|7@1+ (20,0) [0|2540] "ticks"  gtw
 SG_ VCRIGHT_a251_seatSwitchForward m251 : 45|2@1+ (1,0) [0|3] ""  gtw
 SG_ VCRIGHT_a234_seatSwitchForward m234 : 45|2@1+ (1,0) [0|3] ""  gtw
 SG_ VCRIGHT_a252_seatSwitchForward m252 : 45|2@1+ (1,0) [0|3] ""  gtw
 SG_ VCRIGHT_a232_seatSwitchForward m232 : 45|2@1+ (1,0) [0|3] ""  gtw
 SG_ VCRIGHT_a254_seatSwitchForward m254 : 45|2@1+ (1,0) [0|3] ""  gtw
 SG_ VCRIGHT_a235_seatSwitchForward m235 : 45|2@1+ (1,0) [0|3] ""  gtw
 SG_ VCRIGHT_a253_seatSwitchForward m253 : 45|2@1+ (1,0) [0|3] ""  gtw
 SG_ VCRIGHT_a200_encoder8vEn m200 : 45|1@1+ (1,0) [0|1] ""  gtw
 SG_ VCRIGHT_a233_seatSwitchForward m233 : 45|2@1+ (1,0) [0|3] ""  gtw
 SG_ VCRIGHT_a222_seatMotorState m222 : 44|3@1+ (1,0) [0|5] ""  gtw
 SG_ VCRIGHT_a231_seatMotorState m231 : 44|3@1+ (1,0) [0|5] ""  gtw
 SG_ VCRIGHT_a228_seatMotorState m228 : 44|3@1+ (1,0) [0|5] ""  gtw
 SG_ VCRIGHT_a221_seatMotorState m221 : 44|3@1+ (1,0) [0|5] ""  gtw
 SG_ VCRIGHT_a220_seatMotorState m220 : 44|3@1+ (1,0) [0|5] ""  gtw
 SG_ VCRIGHT_a223_seatMotorState m223 : 44|3@1+ (1,0) [0|5] ""  gtw
 SG_ VCRIGHT_a229_seatMotorState m229 : 44|3@1+ (1,0) [0|5] ""  gtw
 SG_ VCRIGHT_a230_seatMotorState m230 : 44|3@1+ (1,0) [0|5] ""  gtw
 SG_ VCRIGHT_a252_seatSwitchBack m252 : 43|2@1+ (1,0) [0|3] ""  gtw
 SG_ VCRIGHT_a234_seatSwitchBack m234 : 43|2@1+ (1,0) [0|3] ""  gtw
 SG_ VCRIGHT_a251_seatSwitchBack m251 : 43|2@1+ (1,0) [0|3] ""  gtw
 SG_ VCRIGHT_a254_seatSwitchBack m254 : 43|2@1+ (1,0) [0|3] ""  gtw
 SG_ VCRIGHT_a232_seatSwitchBack m232 : 43|2@1+ (1,0) [0|3] ""  gtw
 SG_ VCRIGHT_a063_faulted m63 : 43|1@1+ (1,0) [0|1] ""  gtw
 SG_ VCRIGHT_a166_sealPos m166 : 43|8@1+ (1,0) [0|255] ""  gtw
 SG_ VCRIGHT_a253_seatSwitchBack m253 : 43|2@1+ (1,0) [0|3] ""  gtw
 SG_ VCRIGHT_a235_seatSwitchBack m235 : 43|2@1+ (1,0) [0|3] ""  gtw
 SG_ VCRIGHT_a233_seatSwitchBack m233 : 43|2@1+ (1,0) [0|3] ""  gtw
 SG_ VCRIGHT_a218_motorCurrent m218 : 42|10@1- (0.04,0.0) [-20|20] "A"  gtw
 SG_ VCRIGHT_a063_stuckActive m63 : 42|1@1+ (1,0) [0|1] ""  gtw
 SG_ VCRIGHT_a320_peakTimeMs m320 : 41|9@1+ (2,0) [0|1022] "ms"  gtw
 SG_ VCRIGHT_a262_RightIGBTOpen m262 : 41|1@1+ (1,0) [0|1] ""  gtw
 SG_ VCRIGHT_a323_peakTimeMs m323 : 41|9@1+ (2,0) [0|1022] "ms"  gtw
 SG_ VCRIGHT_a063_indeterminate m63 : 41|1@1+ (1,0) [0|1] ""  gtw
 SG_ VCRIGHT_a151_powerDerivAccum m151 : 41|10@1+ (100,0) [0|102300] "ticks"  gtw
 SG_ VCRIGHT_a322_peakTimeMs m322 : 41|9@1+ (2,0) [0|1022] "ms"  gtw
 SG_ VCRIGHT_a321_peakTimeMs m321 : 41|9@1+ (2,0) [0|1022] "ms"  gtw
 SG_ VCRIGHT_a150_powerDerivAccum m150 : 41|10@1+ (100,0) [0|102300] "ticks"  gtw
 SG_ VCRIGHT_a059_current m59 : 40|12@1+ (0.05,0) [0|204.75] "A"  gtw
 SG_ VCRIGHT_a043_CallTrace1 m43 : 40|24@1+ (1,0) [0|16777215] ""  gtw
 SG_ VCRIGHT_a207_unitStatusEPBM m207 : 40|5@1+ (1,0) [0|21] ""  gtw
 SG_ VCRIGHT_a216_byte2 m216 : 40|8@1+ (1,0) [0|255] ""  gtw
 SG_ VCRIGHT_a180_releasePWM m180 : 40|8@1+ (1,0) [0|255] "%"  gtw
 SG_ VCRIGHT_a268_seatMotorPosReal m268 : 40|12@1- (1,0) [-2048|2047] "mm"  gtw
 SG_ VCRIGHT_a044_CallTrace1 m44 : 40|24@1+ (1,0) [0|16777215] ""  gtw
 SG_ VCRIGHT_a265_seatMotorPosReal m265 : 40|12@1- (1,0) [-2048|2047] "mm"  gtw
 SG_ VCRIGHT_a254_seatMotorState m254 : 40|3@1+ (1,0) [0|5] ""  gtw
 SG_ VCRIGHT_a232_seatMotorState m232 : 40|3@1+ (1,0) [0|5] ""  gtw
 SG_ VCRIGHT_a266_seatMotorPosReal m266 : 40|12@1- (1,0) [-2048|2047] "mm"  gtw
 SG_ VCRIGHT_a042_Usage1000msTask m42 : 40|8@1+ (1,0) [0|255] ""  gtw
 SG_ VCRIGHT_a164_downMovementTimeMs m164 : 40|7@1+ (50,0) [0|6350] "ms"  gtw
 SG_ VCRIGHT_a263_seatMotorPosReal m263 : 40|12@1- (1,0) [-2048|2047] "mm"  gtw
 SG_ VCRIGHT_a251_seatMotorState m251 : 40|3@1+ (1,0) [0|5] ""  gtw
 SG_ VCRIGHT_a262_LeftIGBTOpen m262 : 40|1@1+ (1,0) [0|1] ""  gtw
 SG_ VCRIGHT_a269_seatMotorPosReal m269 : 40|12@1- (1,0) [-2048|2047] "mm"  gtw
 SG_ VCRIGHT_a270_seatMotorPosReal m270 : 40|12@1- (1,0) [-2048|2047] "mm"  gtw
 SG_ VCRIGHT_a239_seatHeatTmpTarget m239 : 40|8@1- (0.5,0) [0|60] "degC"  gtw
 SG_ VCRIGHT_a181_releasePWM m181 : 40|8@1+ (1,0) [0|255] "%"  gtw
 SG_ VCRIGHT_a045_CallTrace1 m45 : 40|24@1+ (1,0) [0|16777215] ""  gtw
 SG_ VCRIGHT_a046_CallTrace1 m46 : 40|24@1+ (1,0) [0|16777215] ""  gtw
 SG_ VCRIGHT_a022_TaskInitError2 m22 : 40|8@1+ (1,0) [0|255] ""  gtw
 SG_ VCRIGHT_a267_seatMotorPosReal m267 : 40|12@1- (1,0) [-2048|2047] "mm"  gtw
 SG_ VCRIGHT_a233_seatMotorState m233 : 40|3@1+ (1,0) [0|5] ""  gtw
 SG_ VCRIGHT_a248_seatHeatTmpTarget m248 : 40|8@1- (0.5,0) [0|60] "degC"  gtw
 SG_ VCRIGHT_a208_unitStatusEPBM m208 : 40|5@1+ (1,0) [0|21] ""  gtw
 SG_ VCRIGHT_a234_seatMotorState m234 : 40|3@1+ (1,0) [0|5] ""  gtw
 SG_ VCRIGHT_a252_seatMotorState m252 : 40|3@1+ (1,0) [0|5] ""  gtw
 SG_ VCRIGHT_a255_PCBTemp m255 : 40|8@1- (1,80) [-40|200] "degC"  gtw
 SG_ VCRIGHT_a041_CPULoad100msTask m41 : 40|8@1+ (1,0) [0|255] ""  gtw
 SG_ VCRIGHT_a165_lowerEndStopPositio m165 : 40|8@1+ (10,0) [0|2550] "ticks"  gtw
 SG_ VCRIGHT_a242_seatHeatTmpTarget m242 : 40|8@1- (0.5,0) [0|60] "degC"  gtw
 SG_ VCRIGHT_a206_unitStatusEPBM m206 : 40|5@1+ (1,0) [0|21] ""  gtw
 SG_ VCRIGHT_a063_disconnected m63 : 40|1@1+ (1,0) [0|1] ""  gtw
 SG_ VCRIGHT_a217_byte7 m217 : 40|8@1+ (1,0) [0|255] ""  gtw
 SG_ VCRIGHT_a264_seatMotorPosReal m264 : 40|12@1- (1,0) [-2048|2047] "mm"  gtw
 SG_ VCRIGHT_a253_seatMotorState m253 : 40|3@1+ (1,0) [0|5] ""  gtw
 SG_ VCRIGHT_a209_unitStatusEPBM m209 : 40|5@1+ (1,0) [0|21] ""  gtw
 SG_ VCRIGHT_a235_seatMotorState m235 : 40|3@1+ (1,0) [0|5] ""  gtw
 SG_ VCRIGHT_a210_unitStatusEPBM m210 : 40|5@1+ (1,0) [0|21] ""  gtw
 SG_ VCRIGHT_a245_seatHeatTmpTarget m245 : 40|8@1- (0.5,0) [0|60] "degC"  gtw
 SG_ VCRIGHT_a200_encoderVoltage m200 : 39|6@1+ (0.15,0) [0|9] "V"  gtw
 SG_ VCRIGHT_a262_IGBTDriverPermanent m262 : 39|1@1+ (1,0) [0|1] ""  gtw
 SG_ VCRIGHT_a213_current m213 : 38|10@1+ (0.2,0) [0|204.6] "A"  gtw
 SG_ VCRIGHT_a214_current m214 : 38|10@1+ (0.2,0) [0|204.6] "A"  gtw
 SG_ VCRIGHT_a212_current m212 : 38|10@1+ (0.2,0) [0|204.6] "A"  gtw
 SG_ VCRIGHT_a168_powerDeriv2Accum m168 : 38|10@1+ (1000,0) [0|1023000] "ticks"  gtw
 SG_ VCRIGHT_a204_current m204 : 38|10@1+ (0.2,0) [0|204.6] "A"  gtw
 SG_ VCRIGHT_a202_current m202 : 38|10@1+ (0.2,0) [0|204.6] "A"  gtw
 SG_ VCRIGHT_a205_current m205 : 38|10@1+ (0.2,0) [0|204.6] "A"  gtw
 SG_ VCRIGHT_a262_IGBTDriverTemporary m262 : 38|1@1+ (1,0) [0|1] ""  gtw
 SG_ VCRIGHT_a211_current m211 : 38|10@1+ (0.2,0) [0|204.6] "A"  gtw
 SG_ VCRIGHT_a203_current m203 : 38|10@1+ (0.2,0) [0|204.6] "A"  gtw
 SG_ VCRIGHT_a167_powerDeriv2Accum m167 : 38|10@1+ (1000,0) [0|1023000] "ticks"  gtw
 SG_ VCRIGHT_a262_RightIGBTShort m262 : 37|1@1+ (1,0) [0|1] ""  gtw
 SG_ VCRIGHT_a262_LeftIGBTShort m262 : 36|1@1+ (1,0) [0|1] ""  gtw
 SG_ VCRIGHT_a150_pinchVoltage m150 : 35|6@1+ (0.25,0) [0|16] "V"  gtw
 SG_ VCRIGHT_a262_TempPCB m262 : 35|1@1+ (1,0) [0|1] ""  gtw
 SG_ VCRIGHT_a151_pinchVoltage m151 : 35|6@1+ (0.25,0) [0|16] "V"  gtw
 SG_ VCRIGHT_a323_movementTimeMs m323 : 34|7@1+ (50,0) [0|6350] "ms"  gtw
 SG_ VCRIGHT_a262_RightTempIGBT m262 : 34|1@1+ (1,0) [0|1] ""  gtw
 SG_ VCRIGHT_a225_seatSwitchForward m225 : 34|2@1+ (1,0) [0|3] ""  gtw
 SG_ VCRIGHT_a224_seatSwitchForward m224 : 34|2@1+ (1,0) [0|3] ""  gtw
 SG_ VCRIGHT_a322_movementTimeMs m322 : 34|7@1+ (50,0) [0|6350] "ms"  gtw
 SG_ VCRIGHT_a321_movementTimeMs m321 : 34|7@1+ (50,0) [0|6350] "ms"  gtw
 SG_ VCRIGHT_a227_seatSwitchForward m227 : 34|2@1+ (1,0) [0|3] ""  gtw
 SG_ VCRIGHT_a226_seatSwitchForward m226 : 34|2@1+ (1,0) [0|3] ""  gtw
 SG_ VCRIGHT_a320_movementTimeMs m320 : 34|7@1+ (50,0) [0|6350] "ms"  gtw
 SG_ VCRIGHT_a262_TempOCP m262 : 33|1@1+ (1,0) [0|1] ""  gtw
 SG_ VCRIGHT_a227_seatSwitchBack m227 : 32|2@1+ (1,0) [0|3] ""  gtw
 SG_ VCRIGHT_a202_desyncCount m202 : 32|6@1+ (1,0) [0|63] ""  gtw
 SG_ VCRIGHT_a238_lumbarBPressureHpa m238 : 32|16@1+ (1,0) [0|65535] ""  gtw
 SG_ VCRIGHT_a255_OCPTemp m255 : 32|8@1- (1,80) [-40|200] "degC"  gtw
 SG_ VCRIGHT_a214_desyncCount m214 : 32|6@1+ (1,0) [0|63] ""  gtw
 SG_ VCRIGHT_a286_encoderVoltage m286 : 32|6@1+ (0.15,0) [0|9] "V"  gtw
 SG_ VCRIGHT_a211_desyncCount m211 : 32|6@1+ (1,0) [0|63] ""  gtw
 SG_ VCRIGHT_a221_seatMotorPosReal m221 : 32|12@1- (1,0) [-2048|2047] "mm"  gtw
 SG_ VCRIGHT_a203_desyncCount m203 : 32|6@1+ (1,0) [0|63] ""  gtw
 SG_ VCRIGHT_a236_lumbarBPressureHpa m236 : 32|16@1+ (1,0) [0|65535] ""  gtw
 SG_ VCRIGHT_a241_seatHeatTmpTarget m241 : 32|8@1- (0.5,0) [0|60] "degC"  gtw
 SG_ VCRIGHT_a222_seatMotorPosReal m222 : 32|12@1- (1,0) [-2048|2047] "mm"  gtw
 SG_ VCRIGHT_a168_pinchVoltage m168 : 32|6@1+ (0.25,0) [0|16] "V"  gtw
 SG_ VCRIGHT_a166_powerSealPos m166 : 32|11@1+ (1,0) [0|2047] ""  gtw
 SG_ VCRIGHT_a262_LeftTempIGBT m262 : 32|1@1+ (1,0) [0|1] ""  gtw
 SG_ VCRIGHT_a206_unitStatusEPB m206 : 32|5@1+ (1,0) [0|21] ""  gtw
 SG_ VCRIGHT_a042_Usage100msTask m42 : 32|8@1+ (1,0) [0|255] ""  gtw
 SG_ VCRIGHT_a063_ADCVoltage m63 : 32|8@1+ (0.025,0) [0|6.375] "V"  gtw
 SG_ VCRIGHT_a151_windowPinchReason m151 : 32|3@1+ (1,0) [0|4] ""  gtw
 SG_ VCRIGHT_a164_upMovementTimeMs m164 : 32|7@1+ (50,0) [0|6350] "ms"  gtw
 SG_ VCRIGHT_a167_pinchVoltage m167 : 32|6@1+ (0.25,0) [0|16] "V"  gtw
 SG_ VCRIGHT_a228_seatMotorPosReal m228 : 32|12@1- (1,0) [-2048|2047] "mm"  gtw
 SG_ VCRIGHT_a022_TaskInitError1 m22 : 32|8@1+ (1,0) [0|255] ""  gtw
 SG_ VCRIGHT_a219_dropoutCount m219 : 32|12@1+ (1,0) [0|4095] ""  gtw
 SG_ VCRIGHT_a231_seatMotorPosReal m231 : 32|12@1- (1,0) [-2048|2047] "mm"  gtw
 SG_ VCRIGHT_a224_seatSwitchBack m224 : 32|2@1+ (1,0) [0|3] ""  gtw
 SG_ VCRIGHT_a287_encoderVoltage m287 : 32|6@1+ (0.15,0) [0|9] "V"  gtw
 SG_ VCRIGHT_a204_desyncCount m204 : 32|6@1+ (1,0) [0|63] ""  gtw
 SG_ VCRIGHT_a165_sealZoneStartPos m165 : 32|8@1+ (1,0) [0|255] ""  gtw
 SG_ VCRIGHT_a207_unitStatusEPB m207 : 32|5@1+ (1,0) [0|21] ""  gtw
 SG_ VCRIGHT_a150_windowPinchReason m150 : 32|3@1+ (1,0) [0|4] ""  gtw
 SG_ VCRIGHT_a213_desyncCount m213 : 32|6@1+ (1,0) [0|63] ""  gtw
 SG_ VCRIGHT_a223_seatMotorPosReal m223 : 32|12@1- (1,0) [-2048|2047] "mm"  gtw
 SG_ VCRIGHT_a237_lumbarBPressureHpa m237 : 32|16@1+ (1,0) [0|65535] ""  gtw
 SG_ VCRIGHT_a184_trunkCurrent m184 : 32|8@1+ (0.05,0) [0|12.75] "A"  gtw
 SG_ VCRIGHT_a205_desyncCount m205 : 32|6@1+ (1,0) [0|63] ""  gtw
 SG_ VCRIGHT_a259_temperature m259 : 32|8@1+ (0.5,-40) [-40|80] "degC"  gtw
 SG_ VCRIGHT_a247_seatHeatTmpTarget m247 : 32|8@1- (0.5,0) [0|60] "degC"  gtw
 SG_ VCRIGHT_a230_seatMotorPosReal m230 : 32|12@1- (1,0) [-2048|2047] "mm"  gtw
 SG_ VCRIGHT_a276_mirrorTiltYPosition m276 : 32|8@1+ (0.02,0) [0|5] "V"  gtw
 SG_ VCRIGHT_a225_seatSwitchBack m225 : 32|2@1+ (1,0) [0|3] ""  gtw
 SG_ VCRIGHT_a229_seatMotorPosReal m229 : 32|12@1- (1,0) [-2048|2047] "mm"  gtw
 SG_ VCRIGHT_a181_extHandlePulled m181 : 32|1@1+ (1,0) [0|1] ""  gtw
 SG_ VCRIGHT_a041_CPULoad10msTask m41 : 32|8@1+ (1,0) [0|255] ""  gtw
 SG_ VCRIGHT_a208_unitStatusEPB m208 : 32|5@1+ (1,0) [0|21] ""  gtw
 SG_ VCRIGHT_a226_seatSwitchBack m226 : 32|2@1+ (1,0) [0|3] ""  gtw
 SG_ VCRIGHT_a250_seatHeatTmpTarget m250 : 32|8@1- (0.5,0) [0|60] "degC"  gtw
 SG_ VCRIGHT_a212_desyncCount m212 : 32|6@1+ (1,0) [0|63] ""  gtw
 SG_ VCRIGHT_a244_seatHeatTmpTarget m244 : 32|8@1- (0.5,0) [0|60] "degC"  gtw
 SG_ VCRIGHT_a218_voltage m218 : 32|10@1+ (0.02,0) [0|19] "V"  gtw
 SG_ VCRIGHT_a216_byte1 m216 : 32|8@1+ (1,0) [0|255] ""  gtw
 SG_ VCRIGHT_a210_unitStatusEPB m210 : 32|5@1+ (1,0) [0|21] ""  gtw
 SG_ VCRIGHT_a209_unitStatusEPB m209 : 32|5@1+ (1,0) [0|21] ""  gtw
 SG_ VCRIGHT_a180_extHandlePulled m180 : 32|1@1+ (1,0) [0|1] ""  gtw
 SG_ VCRIGHT_a003_LineNumber m3 : 32|16@1+ (1,0) [0|65535] ""  gtw
 SG_ VCRIGHT_a220_seatMotorPosReal m220 : 32|12@1- (1,0) [-2048|2047] "mm"  gtw
 SG_ VCRIGHT_a260_temperature m260 : 32|8@1+ (0.5,-40) [-40|80] "degC"  gtw
 SG_ VCRIGHT_a000_alertDataW1 m0 : 32|16@1+ (1,0) [0|65535] ""  X
 SG_ VCRIGHT_a217_byte6 m217 : 32|8@1+ (1,0) [0|255] ""  gtw
 SG_ VCRIGHT_a166_STATE_TIMEOUT m166 : 31|1@1+ (1,0) [0|1] ""  gtw
 SG_ VCRIGHT_a262_RightCurrentHVSenso m262 : 31|1@1+ (1,0) [0|1] ""  gtw
 SG_ VCRIGHT_a262_LeftCurrentHVSensor m262 : 30|1@1+ (1,0) [0|1] ""  gtw
 SG_ VCRIGHT_a166_PINCH_DEBUG m166 : 30|1@1+ (1,0) [0|1] ""  gtw
 SG_ VCRIGHT_a225_seatMotorState m225 : 29|3@1+ (1,0) [0|5] ""  gtw
 SG_ VCRIGHT_a262_HighVoltageSensor m262 : 29|1@1+ (1,0) [0|1] ""  gtw
 SG_ VCRIGHT_a224_seatMotorState m224 : 29|3@1+ (1,0) [0|5] ""  gtw
 SG_ VCRIGHT_a227_seatMotorState m227 : 29|3@1+ (1,0) [0|5] ""  gtw
 SG_ VCRIGHT_a166_PINCH_V1 m166 : 29|1@1+ (1,0) [0|1] ""  gtw
 SG_ VCRIGHT_a226_seatMotorState m226 : 29|3@1+ (1,0) [0|5] ""  gtw
 SG_ VCRIGHT_a207_wenchPendingAllowed m207 : 28|1@1+ (1,0) [0|1] ""  gtw
 SG_ VCRIGHT_a249_seatHeatTmp m249 : 28|12@1- (0.05,0) [-40|80] "degC"  gtw
 SG_ VCRIGHT_a264_seatMotorDCurrent m264 : 28|12@1- (0.01,0) [-20.48|20.47] "A"  gtw
 SG_ VCRIGHT_a232_seatMotorPosReal m232 : 28|12@1- (1,0) [-2048|2047] "mm"  gtw
 SG_ VCRIGHT_a254_seatMotorPosReal m254 : 28|12@1- (1,0) [-2048|2047] "mm"  gtw
 SG_ VCRIGHT_a211_wenchPendingAllowed m211 : 28|1@1+ (1,0) [0|1] ""  gtw
 SG_ VCRIGHT_a246_seatHeatTmp m246 : 28|12@1- (0.05,0) [-40|80] "degC"  gtw
 SG_ VCRIGHT_a239_seatHeatTmp m239 : 28|12@1- (0.05,0) [-40|80] "degC"  gtw
 SG_ VCRIGHT_a208_wenchPendingAllowed m208 : 28|1@1+ (1,0) [0|1] ""  gtw
 SG_ VCRIGHT_a235_seatMotorPosReal m235 : 28|12@1- (1,0) [-2048|2047] "mm"  gtw
 SG_ VCRIGHT_a253_seatMotorPosReal m253 : 28|12@1- (1,0) [-2048|2047] "mm"  gtw
 SG_ VCRIGHT_a290_railVoltage m290 : 28|12@1- (0.01,0) [-20.48|20.47] "V"  gtw
 SG_ VCRIGHT_a243_seatHeatTmp m243 : 28|12@1- (0.05,0) [-40|80] "degC"  gtw
 SG_ VCRIGHT_a214_wenchPendingAllowed m214 : 28|1@1+ (1,0) [0|1] ""  gtw
 SG_ VCRIGHT_a265_seatMotorDCurrent m265 : 28|12@1- (0.01,0) [-20.48|20.47] "A"  gtw
 SG_ VCRIGHT_a166_ENCODER_STALL m166 : 28|1@1+ (1,0) [0|1] ""  gtw
 SG_ VCRIGHT_a206_wenchPendingAllowed m206 : 28|1@1+ (1,0) [0|1] ""  gtw
 SG_ VCRIGHT_a248_seatHeatTmp m248 : 28|12@1- (0.05,0) [-40|80] "degC"  gtw
 SG_ VCRIGHT_a268_seatMotorDCurrent m268 : 28|12@1- (0.01,0) [-20.48|20.47] "A"  gtw
 SG_ VCRIGHT_a212_wenchPendingAllowed m212 : 28|1@1+ (1,0) [0|1] ""  gtw
 SG_ VCRIGHT_a292_railV m292 : 28|12@1- (0.01,0) [-20.48|20.47] "V"  gtw
 SG_ VCRIGHT_a245_seatHeatTmp m245 : 28|12@1- (0.05,0) [-40|80] "degC"  gtw
 SG_ VCRIGHT_a262_LowVoltageSensor m262 : 28|1@1+ (1,0) [0|1] ""  gtw
 SG_ VCRIGHT_a291_railVoltage m291 : 28|12@1+ (0.01,0) [0|40.95] "V"  gtw
 SG_ VCRIGHT_a242_seatHeatTmp m242 : 28|12@1- (0.05,0) [-40|80] "degC"  gtw
 SG_ VCRIGHT_a252_seatMotorPosReal m252 : 28|12@1- (1,0) [-2048|2047] "mm"  gtw
 SG_ VCRIGHT_a234_seatMotorPosReal m234 : 28|12@1- (1,0) [-2048|2047] "mm"  gtw
 SG_ VCRIGHT_a251_seatMotorPosReal m251 : 28|12@1- (1,0) [-2048|2047] "mm"  gtw
 SG_ VCRIGHT_a213_wenchPendingAllowed m213 : 28|1@1+ (1,0) [0|1] ""  gtw
 SG_ VCRIGHT_a270_seatMotorDCurrent m270 : 28|12@1- (0.01,0) [-20.48|20.47] "A"  gtw
 SG_ VCRIGHT_a269_seatMotorDCurrent m269 : 28|12@1- (0.01,0) [-20.48|20.47] "A"  gtw
 SG_ VCRIGHT_a293_railV m293 : 28|12@1- (0.01,0) [-20.48|20.47] "V"  gtw
 SG_ VCRIGHT_a263_seatMotorDCurrent m263 : 28|12@1- (0.01,0) [-20.48|20.47] "A"  gtw
 SG_ VCRIGHT_a205_wenchPendingAllowed m205 : 28|1@1+ (1,0) [0|1] ""  gtw
 SG_ VCRIGHT_a266_seatMotorDCurrent m266 : 28|12@1- (0.01,0) [-20.48|20.47] "A"  gtw
 SG_ VCRIGHT_a240_seatHeatTmp m240 : 28|12@1- (0.05,0) [-40|80] "degC"  gtw
 SG_ VCRIGHT_a233_seatMotorPosReal m233 : 28|12@1- (1,0) [-2048|2047] "mm"  gtw
 SG_ VCRIGHT_a059_resistanceEstimate m59 : 28|12@1+ (0.00244,0) [0|9.9918] "Ohms"  gtw
 SG_ VCRIGHT_a203_wenchPendingAllowed m203 : 28|1@1+ (1,0) [0|1] ""  gtw
 SG_ VCRIGHT_a204_wenchPendingAllowed m204 : 28|1@1+ (1,0) [0|1] ""  gtw
 SG_ VCRIGHT_a267_seatMotorDCurrent m267 : 28|12@1- (0.01,0) [-20.48|20.47] "A"  gtw
 SG_ VCRIGHT_a210_wenchPendingAllowed m210 : 28|1@1+ (1,0) [0|1] ""  gtw
 SG_ VCRIGHT_a209_wenchPendingAllowed m209 : 28|1@1+ (1,0) [0|1] ""  gtw
 SG_ VCRIGHT_a202_wenchPendingAllowed m202 : 28|1@1+ (1,0) [0|1] ""  gtw
 SG_ VCRIGHT_a211_parkPendingAllowed m211 : 27|1@1+ (1,0) [0|1] ""  gtw
 SG_ VCRIGHT_a208_parkPendingAllowed m208 : 27|1@1+ (1,0) [0|1] ""  gtw
 SG_ VCRIGHT_a202_parkPendingAllowed m202 : 27|1@1+ (1,0) [0|1] ""  gtw
 SG_ VCRIGHT_a204_parkPendingAllowed m204 : 27|1@1+ (1,0) [0|1] ""  gtw
 SG_ VCRIGHT_a212_parkPendingAllowed m212 : 27|1@1+ (1,0) [0|1] ""  gtw
 SG_ VCRIGHT_a166_UNDERCURRENT m166 : 27|1@1+ (1,0) [0|1] ""  gtw
 SG_ VCRIGHT_a214_parkPendingAllowed m214 : 27|1@1+ (1,0) [0|1] ""  gtw
 SG_ VCRIGHT_a116_VEH_logging1Hz m116 : 27|1@1+ (1,0) [0|1] ""  gtw
 SG_ VCRIGHT_a207_parkPendingAllowed m207 : 27|1@1+ (1,0) [0|1] ""  gtw
 SG_ VCRIGHT_a213_parkPendingAllowed m213 : 27|1@1+ (1,0) [0|1] ""  gtw
 SG_ VCRIGHT_a209_parkPendingAllowed m209 : 27|1@1+ (1,0) [0|1] ""  gtw
 SG_ VCRIGHT_a021_Task1000msMissed m21 : 27|1@1+ (1,0) [0|1] ""  gtw
 SG_ VCRIGHT_a210_parkPendingAllowed m210 : 27|1@1+ (1,0) [0|1] ""  gtw
 SG_ VCRIGHT_a262_CANTimeout m262 : 27|1@1+ (1,0) [0|1] ""  gtw
 SG_ VCRIGHT_a203_parkPendingAllowed m203 : 27|1@1+ (1,0) [0|1] ""  gtw
 SG_ VCRIGHT_a206_parkPendingAllowed m206 : 27|1@1+ (1,0) [0|1] ""  gtw
 SG_ VCRIGHT_a205_parkPendingAllowed m205 : 27|1@1+ (1,0) [0|1] ""  gtw
 SG_ VCRIGHT_a206_releaseAllowed m206 : 26|1@1+ (1,0) [0|1] ""  gtw
 SG_ VCRIGHT_a213_releaseAllowed m213 : 26|1@1+ (1,0) [0|1] ""  gtw
 SG_ VCRIGHT_a205_releaseAllowed m205 : 26|1@1+ (1,0) [0|1] ""  gtw
 SG_ VCRIGHT_a323_positionDelta m323 : 26|8@1+ (2,0) [0|510] "ticks"  gtw
 SG_ VCRIGHT_a166_POWER_AT_SEAL m166 : 26|1@1+ (1,0) [0|1] ""  gtw
 SG_ VCRIGHT_a203_releaseAllowed m203 : 26|1@1+ (1,0) [0|1] ""  gtw
 SG_ VCRIGHT_a210_releaseAllowed m210 : 26|1@1+ (1,0) [0|1] ""  gtw
 SG_ VCRIGHT_a322_positionDelta m322 : 26|8@1+ (2,0) [0|510] "ticks"  gtw
 SG_ VCRIGHT_a021_Task1000msStarved m21 : 26|1@1+ (1,0) [0|1] ""  gtw
 SG_ VCRIGHT_a209_releaseAllowed m209 : 26|1@1+ (1,0) [0|1] ""  gtw
 SG_ VCRIGHT_a262_RightThermalShutIGB m262 : 26|1@1+ (1,0) [0|1] ""  gtw
 SG_ VCRIGHT_a204_releaseAllowed m204 : 26|1@1+ (1,0) [0|1] ""  gtw
 SG_ VCRIGHT_a116_VEH_switchStatus m116 : 26|1@1+ (1,0) [0|1] ""  gtw
 SG_ VCRIGHT_a207_releaseAllowed m207 : 26|1@1+ (1,0) [0|1] ""  gtw
 SG_ VCRIGHT_a321_positionDelta m321 : 26|8@1+ (2,0) [0|510] "ticks"  gtw
 SG_ VCRIGHT_a202_releaseAllowed m202 : 26|1@1+ (1,0) [0|1] ""  gtw
 SG_ VCRIGHT_a214_releaseAllowed m214 : 26|1@1+ (1,0) [0|1] ""  gtw
 SG_ VCRIGHT_a208_releaseAllowed m208 : 26|1@1+ (1,0) [0|1] ""  gtw
 SG_ VCRIGHT_a211_releaseAllowed m211 : 26|1@1+ (1,0) [0|1] ""  gtw
 SG_ VCRIGHT_a212_releaseAllowed m212 : 26|1@1+ (1,0) [0|1] ""  gtw
 SG_ VCRIGHT_a320_positionDelta m320 : 26|8@1+ (2,0) [0|510] "ticks"  gtw
 SG_ VCRIGHT_a166_JUST_CALIBRATED m166 : 25|1@1+ (1,0) [0|1] ""  gtw
 SG_ VCRIGHT_a287_voltage m287 : 25|7@1+ (0.15,0) [0|19] "V"  gtw
 SG_ VCRIGHT_a213_dynApplyAllowed m213 : 25|1@1+ (1,0) [0|1] ""  gtw
 SG_ VCRIGHT_a212_dynApplyAllowed m212 : 25|1@1+ (1,0) [0|1] ""  gtw
 SG_ VCRIGHT_a286_voltage m286 : 25|7@1+ (0.15,0) [0|19] "V"  gtw
 SG_ VCRIGHT_a117_VEH_intrusionSensor m117 : 25|1@1+ (1,0) [0|1] ""  gtw
 SG_ VCRIGHT_a206_dynApplyAllowed m206 : 25|1@1+ (1,0) [0|1] ""  gtw
 SG_ VCRIGHT_a214_dynApplyAllowed m214 : 25|1@1+ (1,0) [0|1] ""  gtw
 SG_ VCRIGHT_a208_dynApplyAllowed m208 : 25|1@1+ (1,0) [0|1] ""  gtw
 SG_ VCRIGHT_a021_Task1000msLate m21 : 25|1@1+ (1,0) [0|1] ""  gtw
 SG_ VCRIGHT_a211_dynApplyAllowed m211 : 25|1@1+ (1,0) [0|1] ""  gtw
 SG_ VCRIGHT_a207_dynApplyAllowed m207 : 25|1@1+ (1,0) [0|1] ""  gtw
 SG_ VCRIGHT_a202_dynApplyAllowed m202 : 25|1@1+ (1,0) [0|1] ""  gtw
 SG_ VCRIGHT_a262_LeftThermalShutIGBT m262 : 25|1@1+ (1,0) [0|1] ""  gtw
 SG_ VCRIGHT_a210_dynApplyAllowed m210 : 25|1@1+ (1,0) [0|1] ""  gtw
 SG_ VCRIGHT_a209_dynApplyAllowed m209 : 25|1@1+ (1,0) [0|1] ""  gtw
 SG_ VCRIGHT_a204_dynApplyAllowed m204 : 25|1@1+ (1,0) [0|1] ""  gtw
 SG_ VCRIGHT_a203_dynApplyAllowed m203 : 25|1@1+ (1,0) [0|1] ""  gtw
 SG_ VCRIGHT_a116_VEH_restraintStatus m116 : 25|1@1+ (1,0) [0|1] ""  gtw
 SG_ VCRIGHT_a205_dynApplyAllowed m205 : 25|1@1+ (1,0) [0|1] ""  gtw
 SG_ VCRIGHT_a116_VEH_seatHeatStatus m116 : 24|1@1+ (1,0) [0|1] ""  gtw
 SG_ VCRIGHT_a188_temperature m188 : 24|8@1+ (0.5,-40) [-40|80] "degC"  gtw
 SG_ VCRIGHT_a118_VEH_systemStatus m118 : 24|1@1+ (1,0) [0|1] ""  gtw
 SG_ VCRIGHT_a166_CAL_CLEAR_PARTIAL m166 : 24|1@1+ (1,0) [0|1] ""  gtw
 SG_ VCRIGHT_a117_VEH_switchStatus m117 : 24|1@1+ (1,0) [0|1] ""  gtw
 SG_ VCRIGHT_a187_temperature m187 : 24|8@1+ (0.5,-40) [-40|80] "degC"  gtw
 SG_ VCRIGHT_a208_parkingAllowed m208 : 24|1@1+ (1,0) [0|1] ""  gtw
 SG_ VCRIGHT_a273_temperature m273 : 24|8@1+ (0.5,-40) [-40|80] "degC"  gtw
 SG_ VCRIGHT_a211_parkingAllowed m211 : 24|1@1+ (1,0) [0|1] ""  gtw
 SG_ VCRIGHT_a063_switchType m63 : 24|8@1+ (1,0) [0|255] ""  gtw
 SG_ VCRIGHT_a205_parkingAllowed m205 : 24|1@1+ (1,0) [0|1] ""  gtw
 SG_ VCRIGHT_a022_TaskInitError0 m22 : 24|8@1+ (1,0) [0|255] ""  gtw
 SG_ VCRIGHT_a113_VEH_powertrainContr m113 : 24|1@1+ (1,0) [0|1] ""  gtw
 SG_ VCRIGHT_a168_movementTimeMs m168 : 24|7@1+ (50,0) [0|6350] "ms"  gtw
 SG_ VCRIGHT_a150_movementTimeMs m150 : 24|7@1+ (50,0) [0|6350] "ms"  gtw
 SG_ VCRIGHT_a189_temperature m189 : 24|8@1+ (0.5,-40) [-40|80] "degC"  gtw
 SG_ VCRIGHT_a021_Task100msMissed m21 : 24|1@1+ (1,0) [0|1] ""  gtw
 SG_ VCRIGHT_a206_parkingAllowed m206 : 24|1@1+ (1,0) [0|1] ""  gtw
 SG_ VCRIGHT_a259_voltage m259 : 24|7@1+ (0.15,0) [0|19] "V"  gtw
 SG_ VCRIGHT_a042_Usage10msTask m42 : 24|8@1+ (1,0) [0|255] ""  gtw
 SG_ VCRIGHT_a203_parkingAllowed m203 : 24|1@1+ (1,0) [0|1] ""  gtw
 SG_ VCRIGHT_a184_temperature m184 : 24|8@1+ (0.5,-40) [-40|80] "degC"  gtw
 SG_ VCRIGHT_a262_ThermalShutPCB m262 : 24|1@1+ (1,0) [0|1] ""  gtw
 SG_ VCRIGHT_a210_parkingAllowed m210 : 24|1@1+ (1,0) [0|1] ""  gtw
 SG_ VCRIGHT_a217_byte5 m217 : 24|8@1+ (1,0) [0|255] ""  gtw
 SG_ VCRIGHT_a209_parkingAllowed m209 : 24|1@1+ (1,0) [0|1] ""  gtw
 SG_ VCRIGHT_a180_extHandlePWM m180 : 24|8@1+ (1,0) [0|255] "%"  gtw
 SG_ VCRIGHT_a256_rightCurrent m256 : 24|8@1+ (0.2,0) [0|50] "A"  gtw
 SG_ VCRIGHT_a167_movementTimeMs m167 : 24|7@1+ (50,0) [0|6350] "ms"  gtw
 SG_ VCRIGHT_a213_parkingAllowed m213 : 24|1@1+ (1,0) [0|1] ""  gtw
 SG_ VCRIGHT_a201_motorChannels m201 : 24|16@1+ (1,0) [0|65535] ""  gtw
 SG_ VCRIGHT_a120_VEH_speed m120 : 24|1@1+ (1,0) [0|1] ""  gtw
 SG_ VCRIGHT_a151_movementTimeMs m151 : 24|7@1+ (50,0) [0|6350] "ms"  gtw
 SG_ VCRIGHT_a283_temperature m283 : 24|8@1+ (0.5,-40) [-40|80] "degC"  gtw
 SG_ VCRIGHT_a207_parkingAllowed m207 : 24|1@1+ (1,0) [0|1] ""  gtw
 SG_ VCRIGHT_a274_temperature m274 : 24|8@1+ (0.5,-40) [-40|80] "degC"  gtw
 SG_ VCRIGHT_a165_maxClosingPower m165 : 24|8@1+ (1,0) [0|255] "W"  gtw
 SG_ VCRIGHT_a041_CPULoad1msTask m41 : 24|8@1+ (1,0) [0|255] ""  gtw
 SG_ VCRIGHT_a214_parkingAllowed m214 : 24|1@1+ (1,0) [0|1] ""  gtw
 SG_ VCRIGHT_a216_byte0 m216 : 24|8@1+ (1,0) [0|255] ""  gtw
 SG_ VCRIGHT_a164_stopReason m164 : 24|3@1+ (1,0) [0|6] ""  gtw
 SG_ VCRIGHT_a282_temperature m282 : 24|8@1+ (0.5,-40) [-40|80] "degC"  gtw
 SG_ VCRIGHT_a181_extHandlePWM m181 : 24|8@1+ (1,0) [0|255] "%"  gtw
 SG_ VCRIGHT_a287_windowDirectionUp m287 : 24|1@1+ (1,0) [0|1] ""  gtw
 SG_ VCRIGHT_a212_parkingAllowed m212 : 24|1@1+ (1,0) [0|1] ""  gtw
 SG_ VCRIGHT_a170_currentPeakPosition m170 : 24|8@1+ (10,0) [0|2550] "ticks"  gtw
 SG_ VCRIGHT_a169_currentPeakPosition m169 : 24|8@1+ (10,0) [0|2550] "ticks"  gtw
 SG_ VCRIGHT_a260_voltage m260 : 24|7@1+ (0.15,0) [0|19] "V"  gtw
 SG_ VCRIGHT_a255_rightIGBTTemp m255 : 24|8@1- (1,80) [-40|200] "degC"  gtw
 SG_ VCRIGHT_a276_mirrorTiltXPosition m276 : 24|8@1+ (0.02,0) [0|5] "V"  gtw
 SG_ VCRIGHT_a204_parkingAllowed m204 : 24|1@1+ (1,0) [0|1] ""  gtw
 SG_ VCRIGHT_a183_stopReason m183 : 24|4@1+ (1,0) [0|8] ""  gtw
 SG_ VCRIGHT_a310_foldingDirection m310 : 24|1@1+ (1,0) [0|1] ""  gtw
 SG_ VCRIGHT_a186_temperature m186 : 24|8@1+ (0.5,-40) [-40|80] "degC"  gtw
 SG_ VCRIGHT_a202_parkingAllowed m202 : 24|1@1+ (1,0) [0|1] ""  gtw
 SG_ VCRIGHT_a286_windowDirectionUp m286 : 24|1@1+ (1,0) [0|1] ""  gtw
 SG_ VCRIGHT_a214_winchReleaseAllowed m214 : 23|1@1+ (1,0) [0|1] ""  gtw
 SG_ VCRIGHT_a021_Task100msStarved m21 : 23|1@1+ (1,0) [0|1] ""  gtw
 SG_ VCRIGHT_a202_winchReleaseAllowed m202 : 23|1@1+ (1,0) [0|1] ""  gtw
 SG_ VCRIGHT_a207_winchReleaseAllowed m207 : 23|1@1+ (1,0) [0|1] ""  gtw
 SG_ VCRIGHT_a200_motorChannels m200 : 23|16@1+ (1,0) [0|65535] ""  gtw
 SG_ VCRIGHT_a118_VEH_12VBattStatus m118 : 23|1@1+ (1,0) [0|1] ""  gtw
 SG_ VCRIGHT_a206_winchReleaseAllowed m206 : 23|1@1+ (1,0) [0|1] ""  gtw
 SG_ VCRIGHT_a212_winchReleaseAllowed m212 : 23|1@1+ (1,0) [0|1] ""  gtw
 SG_ VCRIGHT_a116_VEH_doorStatus m116 : 23|1@1+ (1,0) [0|1] ""  gtw
 SG_ VCRIGHT_a205_winchReleaseAllowed m205 : 23|1@1+ (1,0) [0|1] ""  gtw
 SG_ VCRIGHT_a120_PARTY_speed m120 : 23|1@1+ (1,0) [0|1] ""  gtw
 SG_ VCRIGHT_a166_CAL_CLEAR_POS m166 : 23|1@1+ (1,0) [0|1] ""  gtw
 SG_ VCRIGHT_a213_winchReleaseAllowed m213 : 23|1@1+ (1,0) [0|1] ""  gtw
 SG_ VCRIGHT_a262_RightShutOutlet m262 : 23|1@1+ (1,0) [0|1] ""  gtw
 SG_ VCRIGHT_a204_winchReleaseAllowed m204 : 23|1@1+ (1,0) [0|1] ""  gtw
 SG_ VCRIGHT_a209_winchReleaseAllowed m209 : 23|1@1+ (1,0) [0|1] ""  gtw
 SG_ VCRIGHT_a117_VEH_doorStatus m117 : 23|1@1+ (1,0) [0|1] ""  gtw
 SG_ VCRIGHT_a210_winchReleaseAllowed m210 : 23|1@1+ (1,0) [0|1] ""  gtw
 SG_ VCRIGHT_a203_winchReleaseAllowed m203 : 23|1@1+ (1,0) [0|1] ""  gtw
 SG_ VCRIGHT_a208_winchReleaseAllowed m208 : 23|1@1+ (1,0) [0|1] ""  gtw
 SG_ VCRIGHT_a113_VEH_chassisControl m113 : 23|1@1+ (1,0) [0|1] ""  gtw
 SG_ VCRIGHT_a211_winchReleaseAllowed m211 : 23|1@1+ (1,0) [0|1] ""  gtw
 SG_ VCRIGHT_a021_Task100msLate m21 : 22|1@1+ (1,0) [0|1] ""  gtw
 SG_ VCRIGHT_a113_VEH_ventCntlReq m113 : 22|1@1+ (1,0) [0|1] ""  gtw
 SG_ VCRIGHT_a212_winchAllowed m212 : 22|1@1+ (1,0) [0|1] ""  gtw
 SG_ VCRIGHT_a276_mirrorDip m276 : 22|1@1+ (1,0) [0|1] ""  gtw
 SG_ VCRIGHT_a206_winchAllowed m206 : 22|1@1+ (1,0) [0|1] ""  gtw
 SG_ VCRIGHT_a205_winchAllowed m205 : 22|1@1+ (1,0) [0|1] ""  gtw
 SG_ VCRIGHT_a262_LeftShutOutlet m262 : 22|1@1+ (1,0) [0|1] ""  gtw
 SG_ VCRIGHT_a116_VEH_thsStatus m116 : 22|1@1+ (1,0) [0|1] ""  gtw
 SG_ VCRIGHT_a120_VEH_status m120 : 22|1@1+ (1,0) [0|1] ""  gtw
 SG_ VCRIGHT_a213_winchAllowed m213 : 22|1@1+ (1,0) [0|1] ""  gtw
 SG_ VCRIGHT_a209_winchAllowed m209 : 22|1@1+ (1,0) [0|1] ""  gtw
 SG_ VCRIGHT_a210_winchAllowed m210 : 22|1@1+ (1,0) [0|1] ""  gtw
 SG_ VCRIGHT_a204_winchAllowed m204 : 22|1@1+ (1,0) [0|1] ""  gtw
 SG_ VCRIGHT_a203_winchAllowed m203 : 22|1@1+ (1,0) [0|1] ""  gtw
 SG_ VCRIGHT_a214_winchAllowed m214 : 22|1@1+ (1,0) [0|1] ""  gtw
 SG_ VCRIGHT_a166_CAL_CLEAR_SWITCH m166 : 22|1@1+ (1,0) [0|1] ""  gtw
 SG_ VCRIGHT_a117_VEH_seatStatus m117 : 22|1@1+ (1,0) [0|1] ""  gtw
 SG_ VCRIGHT_a211_winchAllowed m211 : 22|1@1+ (1,0) [0|1] ""  gtw
 SG_ VCRIGHT_a208_winchAllowed m208 : 22|1@1+ (1,0) [0|1] ""  gtw
 SG_ VCRIGHT_a207_winchAllowed m207 : 22|1@1+ (1,0) [0|1] ""  gtw
 SG_ VCRIGHT_a202_winchAllowed m202 : 22|1@1+ (1,0) [0|1] ""  gtw
 SG_ VCRIGHT_a118_VEH_vehicleStatus m118 : 22|1@1+ (1,0) [0|1] ""  gtw
 SG_ VCRIGHT_a116_VEH_seatStatus m116 : 21|1@1+ (1,0) [0|1] ""  gtw
 SG_ VCRIGHT_a213_serviceAllowed m213 : 21|1@1+ (1,0) [0|1] ""  gtw
 SG_ VCRIGHT_a214_serviceAllowed m214 : 21|1@1+ (1,0) [0|1] ""  gtw
 SG_ VCRIGHT_a203_serviceAllowed m203 : 21|1@1+ (1,0) [0|1] ""  gtw
 SG_ VCRIGHT_a206_serviceAllowed m206 : 21|1@1+ (1,0) [0|1] ""  gtw
 SG_ VCRIGHT_a118_VEH_LVPowerState m118 : 21|1@1+ (1,0) [0|1] ""  gtw
 SG_ VCRIGHT_a209_serviceAllowed m209 : 21|1@1+ (1,0) [0|1] ""  gtw
 SG_ VCRIGHT_a210_serviceAllowed m210 : 21|1@1+ (1,0) [0|1] ""  gtw
 SG_ VCRIGHT_a166_THERMAL_BLOCKED m166 : 21|1@1+ (1,0) [0|1] ""  gtw
 SG_ VCRIGHT_a202_serviceAllowed m202 : 21|1@1+ (1,0) [0|1] ""  gtw
 SG_ VCRIGHT_a015_NVMMWriteFailed m15 : 21|1@1+ (1,0) [0|1] ""  gtw
 SG_ VCRIGHT_a205_serviceAllowed m205 : 21|1@1+ (1,0) [0|1] ""  gtw
 SG_ VCRIGHT_a208_serviceAllowed m208 : 21|1@1+ (1,0) [0|1] ""  gtw
 SG_ VCRIGHT_a211_serviceAllowed m211 : 21|1@1+ (1,0) [0|1] ""  gtw
 SG_ VCRIGHT_a113_VEH_solarData m113 : 21|1@1+ (1,0) [0|1] ""  gtw
 SG_ VCRIGHT_a212_serviceAllowed m212 : 21|1@1+ (1,0) [0|1] ""  gtw
 SG_ VCRIGHT_a021_Task10msMissed m21 : 21|1@1+ (1,0) [0|1] ""  gtw
 SG_ VCRIGHT_a262_RightOverCurrent m262 : 21|1@1+ (1,0) [0|1] ""  gtw
 SG_ VCRIGHT_a117_VEH_lightStatus m117 : 21|1@1+ (1,0) [0|1] ""  gtw
 SG_ VCRIGHT_a120_PARTY_locStatus m120 : 21|1@1+ (1,0) [0|1] ""  gtw
 SG_ VCRIGHT_a204_serviceAllowed m204 : 21|1@1+ (1,0) [0|1] ""  gtw
 SG_ VCRIGHT_a012_ExternalReset m12 : 21|1@1+ (1,0) [0|1] ""  gtw
 SG_ VCRIGHT_a207_serviceAllowed m207 : 21|1@1+ (1,0) [0|1] ""  gtw
 SG_ VCRIGHT_a207_startAllowed m207 : 20|1@1+ (1,0) [0|1] ""  gtw
 SG_ VCRIGHT_a015_NVMMMemOverflow m15 : 20|1@1+ (1,0) [0|1] ""  gtw
 SG_ VCRIGHT_a113_VEH_vehicleControl2 m113 : 20|1@1+ (1,0) [0|1] ""  gtw
 SG_ VCRIGHT_a262_LeftOverCurrent m262 : 20|1@1+ (1,0) [0|1] ""  gtw
 SG_ VCRIGHT_a120_VEH_torque m120 : 20|1@1+ (1,0) [0|1] ""  gtw
 SG_ VCRIGHT_a214_startAllowed m214 : 20|1@1+ (1,0) [0|1] ""  gtw
 SG_ VCRIGHT_a012_DebugReset m12 : 20|1@1+ (1,0) [0|1] ""  gtw
 SG_ VCRIGHT_a212_startAllowed m212 : 20|1@1+ (1,0) [0|1] ""  gtw
 SG_ VCRIGHT_a107_VEH_bmbMinMax m107 : 20|1@1+ (1,0) [0|1] ""  gtw
 SG_ VCRIGHT_a204_startAllowed m204 : 20|1@1+ (1,0) [0|1] ""  gtw
 SG_ VCRIGHT_a202_startAllowed m202 : 20|1@1+ (1,0) [0|1] ""  gtw
 SG_ VCRIGHT_a166_THERMAL m166 : 20|1@1+ (1,0) [0|1] ""  gtw
 SG_ VCRIGHT_a021_Task10msStarved m21 : 20|1@1+ (1,0) [0|1] ""  gtw
 SG_ VCRIGHT_a211_startAllowed m211 : 20|1@1+ (1,0) [0|1] ""  gtw
 SG_ VCRIGHT_a208_startAllowed m208 : 20|1@1+ (1,0) [0|1] ""  gtw
 SG_ VCRIGHT_a205_startAllowed m205 : 20|1@1+ (1,0) [0|1] ""  gtw
 SG_ VCRIGHT_a117_VEH_restraintStatus m117 : 20|1@1+ (1,0) [0|1] ""  gtw
 SG_ VCRIGHT_a206_startAllowed m206 : 20|1@1+ (1,0) [0|1] ""  gtw
 SG_ VCRIGHT_a203_startAllowed m203 : 20|1@1+ (1,0) [0|1] ""  gtw
 SG_ VCRIGHT_a210_startAllowed m210 : 20|1@1+ (1,0) [0|1] ""  gtw
 SG_ VCRIGHT_a209_startAllowed m209 : 20|1@1+ (1,0) [0|1] ""  gtw
 SG_ VCRIGHT_a118_VEH_okToUseHighPwr m118 : 20|1@1+ (1,0) [0|1] ""  gtw
 SG_ VCRIGHT_a116_VEH_lightStatus m116 : 20|1@1+ (1,0) [0|1] ""  gtw
 SG_ VCRIGHT_a213_startAllowed m213 : 20|1@1+ (1,0) [0|1] ""  gtw
 SG_ VCRIGHT_a148_snsRateChangeDown m148 : 19|1@1+ (1,0) [0|1] ""  gtw
 SG_ VCRIGHT_a207_parkAllowed m207 : 19|1@1+ (1,0) [0|1] ""  gtw
 SG_ VCRIGHT_a208_parkAllowed m208 : 19|1@1+ (1,0) [0|1] ""  gtw
 SG_ VCRIGHT_a211_parkAllowed m211 : 19|1@1+ (1,0) [0|1] ""  gtw
 SG_ VCRIGHT_a147_snsRateChangeDown m147 : 19|1@1+ (1,0) [0|1] ""  gtw
 SG_ VCRIGHT_a109_PARTY_collision m109 : 19|1@1+ (1,0) [0|1] ""  gtw
 SG_ VCRIGHT_a183_lastState m183 : 19|3@1+ (1,0) [0|6] ""  gtw
 SG_ VCRIGHT_a214_parkAllowed m214 : 19|1@1+ (1,0) [0|1] ""  gtw
 SG_ VCRIGHT_a206_parkAllowed m206 : 19|1@1+ (1,0) [0|1] ""  gtw
 SG_ VCRIGHT_a149_snsRateChangeDown m149 : 19|1@1+ (1,0) [0|1] ""  gtw
 SG_ VCRIGHT_a144_snsRateChangeDown m144 : 19|1@1+ (1,0) [0|1] ""  gtw
 SG_ VCRIGHT_a117_VEH_LVPowerState m117 : 19|1@1+ (1,0) [0|1] ""  gtw
 SG_ VCRIGHT_a212_parkAllowed m212 : 19|1@1+ (1,0) [0|1] ""  gtw
 SG_ VCRIGHT_a262_HVHigh m262 : 19|1@1+ (1,0) [0|1] ""  gtw
 SG_ VCRIGHT_a166_PINCH_OVERRIDE m166 : 19|1@1+ (1,0) [0|1] ""  gtw
 SG_ VCRIGHT_a104_PARTY_control m104 : 19|1@1+ (1,0) [0|1] ""  gtw
 SG_ VCRIGHT_a216_monitor_MIA m216 : 19|1@1+ (1,0) [0|1] ""  gtw
 SG_ VCRIGHT_a113_VEH_vehicleControl m113 : 19|1@1+ (1,0) [0|1] ""  gtw
 SG_ VCRIGHT_a118_VEH_status m118 : 19|1@1+ (1,0) [0|1] ""  gtw
 SG_ VCRIGHT_a213_parkAllowed m213 : 19|1@1+ (1,0) [0|1] ""  gtw
 SG_ VCRIGHT_a145_snsRateChangeDown m145 : 19|1@1+ (1,0) [0|1] ""  gtw
 SG_ VCRIGHT_a108_PARTY_torque m108 : 19|1@1+ (1,0) [0|1] ""  gtw
 SG_ VCRIGHT_a021_Task10msLate m21 : 19|1@1+ (1,0) [0|1] ""  gtw
 SG_ VCRIGHT_a015_NVMMRecordUpgraded m15 : 19|1@1+ (1,0) [0|1] ""  gtw
 SG_ VCRIGHT_a107_VEH_thermalStatus m107 : 19|1@1+ (1,0) [0|1] ""  gtw
 SG_ VCRIGHT_a276_mirrorState m276 : 19|3@1+ (1,0) [0|4] ""  gtw
 SG_ VCRIGHT_a120_PARTY_torque m120 : 19|1@1+ (1,0) [0|1] ""  gtw
 SG_ VCRIGHT_a205_parkAllowed m205 : 19|1@1+ (1,0) [0|1] ""  gtw
 SG_ VCRIGHT_a271_solarInfSensorSNA m271 : 19|1@1+ (1,0) [0|1] ""  gtw
 SG_ VCRIGHT_a203_parkAllowed m203 : 19|1@1+ (1,0) [0|1] ""  gtw
 SG_ VCRIGHT_a204_parkAllowed m204 : 19|1@1+ (1,0) [0|1] ""  gtw
 SG_ VCRIGHT_a164_lastState m164 : 19|3@1+ (1,0) [0|5] ""  gtw
 SG_ VCRIGHT_a209_parkAllowed m209 : 19|1@1+ (1,0) [0|1] ""  gtw
 SG_ VCRIGHT_a146_snsRateChangeDown m146 : 19|1@1+ (1,0) [0|1] ""  gtw
 SG_ VCRIGHT_a210_parkAllowed m210 : 19|1@1+ (1,0) [0|1] ""  gtw
 SG_ VCRIGHT_a114_PARTY_party3 m114 : 19|1@1+ (1,0) [0|1] ""  gtw
 SG_ VCRIGHT_a202_parkAllowed m202 : 19|1@1+ (1,0) [0|1] ""  gtw
 SG_ VCRIGHT_a116_VEH_LVPowerState m116 : 19|1@1+ (1,0) [0|1] ""  gtw
 SG_ VCRIGHT_a012_CheckstopReset m12 : 19|1@1+ (1,0) [0|1] ""  gtw
 SG_ VCRIGHT_a108_VEH_torque m108 : 18|1@1+ (1,0) [0|1] ""  gtw
 SG_ VCRIGHT_a213_dynamicAllowed m213 : 18|1@1+ (1,0) [0|1] ""  gtw
 SG_ VCRIGHT_a102_VEH_sensorStatus m102 : 18|1@1+ (1,0) [0|1] ""  gtw
 SG_ VCRIGHT_a198_lockoutState m198 : 18|1@1+ (1,0) [0|1] ""  gtw
 SG_ VCRIGHT_a152_pinchTableBuilt m152 : 18|1@1+ (1,0) [0|1] ""  gtw
 SG_ VCRIGHT_a103_VEH_status m103 : 18|1@1+ (1,0) [0|1] ""  gtw
 SG_ VCRIGHT_a015_NVMMVersionMismatch m15 : 18|1@1+ (1,0) [0|1] ""  gtw
 SG_ VCRIGHT_a214_dynamicAllowed m214 : 18|1@1+ (1,0) [0|1] ""  gtw
 SG_ VCRIGHT_a145_snsRateChangeUp m145 : 18|1@1+ (1,0) [0|1] ""  gtw
 SG_ VCRIGHT_a021_Task1msMissed m21 : 18|1@1+ (1,0) [0|1] ""  gtw
 SG_ VCRIGHT_a113_VEH_chargeRequest m113 : 18|1@1+ (1,0) [0|1] ""  gtw
 SG_ VCRIGHT_a203_dynamicAllowed m203 : 18|1@1+ (1,0) [0|1] ""  gtw
 SG_ VCRIGHT_a262_HVLow m262 : 18|1@1+ (1,0) [0|1] ""  gtw
 SG_ VCRIGHT_a196_lockoutState m196 : 18|1@1+ (1,0) [0|1] ""  gtw
 SG_ VCRIGHT_a119_VEH_rightStalk m119 : 18|1@1+ (1,0) [0|1] ""  gtw
 SG_ VCRIGHT_a206_dynamicAllowed m206 : 18|1@1+ (1,0) [0|1] ""  gtw
 SG_ VCRIGHT_a012_SoftwareReset m12 : 18|1@1+ (1,0) [0|1] ""  gtw
 SG_ VCRIGHT_a144_snsRateChangeUp m144 : 18|1@1+ (1,0) [0|1] ""  gtw
 SG_ VCRIGHT_a107_VEH_status m107 : 18|1@1+ (1,0) [0|1] ""  gtw
 SG_ VCRIGHT_a104_VEH_thermalStatus m104 : 18|1@1+ (1,0) [0|1] ""  gtw
 SG_ VCRIGHT_a210_dynamicAllowed m210 : 18|1@1+ (1,0) [0|1] ""  gtw
 SG_ VCRIGHT_a209_dynamicAllowed m209 : 18|1@1+ (1,0) [0|1] ""  gtw
 SG_ VCRIGHT_a120_PARTY_systemStatus m120 : 18|1@1+ (1,0) [0|1] ""  gtw
 SG_ VCRIGHT_a199_lockoutState m199 : 18|1@1+ (1,0) [0|1] ""  gtw
 SG_ VCRIGHT_a149_snsRateChangeUp m149 : 18|1@1+ (1,0) [0|1] ""  gtw
 SG_ VCRIGHT_a183_doorRear m183 : 18|1@1+ (1,0) [0|1] ""  gtw
 SG_ VCRIGHT_a216_CRC_error m216 : 18|1@1+ (1,0) [0|1] ""  gtw
 SG_ VCRIGHT_a166_PINCH_V2C m166 : 18|1@1+ (1,0) [0|1] ""  gtw
 SG_ VCRIGHT_a197_lockoutState m197 : 18|1@1+ (1,0) [0|1] ""  gtw
 SG_ VCRIGHT_a202_dynamicAllowed m202 : 18|1@1+ (1,0) [0|1] ""  gtw
 SG_ VCRIGHT_a147_snsRateChangeUp m147 : 18|1@1+ (1,0) [0|1] ""  gtw
 SG_ VCRIGHT_a148_snsRateChangeUp m148 : 18|1@1+ (1,0) [0|1] ""  gtw
 SG_ VCRIGHT_a165_windowRear m165 : 18|1@1+ (1,0) [0|1] ""  gtw
 SG_ VCRIGHT_a109_PARTY_nearDeploy m109 : 18|1@1+ (1,0) [0|1] ""  gtw
 SG_ VCRIGHT_a205_dynamicAllowed m205 : 18|1@1+ (1,0) [0|1] ""  gtw
 SG_ VCRIGHT_a208_dynamicAllowed m208 : 18|1@1+ (1,0) [0|1] ""  gtw
 SG_ VCRIGHT_a114_VEH_wheelSpeeds m114 : 18|1@1+ (1,0) [0|1] ""  gtw
 SG_ VCRIGHT_a116_VEH_hvacRequest m116 : 18|1@1+ (1,0) [0|1] ""  gtw
 SG_ VCRIGHT_a211_dynamicAllowed m211 : 18|1@1+ (1,0) [0|1] ""  gtw
 SG_ VCRIGHT_a146_snsRateChangeUp m146 : 18|1@1+ (1,0) [0|1] ""  gtw
 SG_ VCRIGHT_a106_VEH_thermalStatus m106 : 18|1@1+ (1,0) [0|1] ""  gtw
 SG_ VCRIGHT_a212_dynamicAllowed m212 : 18|1@1+ (1,0) [0|1] ""  gtw
 SG_ VCRIGHT_a118_VEH_sensors m118 : 18|1@1+ (1,0) [0|1] ""  gtw
 SG_ VCRIGHT_a110_VEH_time m110 : 18|1@1+ (1,0) [0|1] ""  gtw
 SG_ VCRIGHT_a271_solarVisSensorSNA m271 : 18|1@1+ (1,0) [0|1] ""  gtw
 SG_ VCRIGHT_a272_actualState m272 : 18|2@1+ (1,0) [0|3] ""  gtw
 SG_ VCRIGHT_a117_VEH_hvacBlowerFdb m117 : 18|1@1+ (1,0) [0|1] ""  gtw
 SG_ VCRIGHT_a204_dynamicAllowed m204 : 18|1@1+ (1,0) [0|1] ""  gtw
 SG_ VCRIGHT_a164_windowRear m164 : 18|1@1+ (1,0) [0|1] ""  gtw
 SG_ VCRIGHT_a153_pinchTableBuilt m153 : 18|1@1+ (1,0) [0|1] ""  gtw
 SG_ VCRIGHT_a207_dynamicAllowed m207 : 18|1@1+ (1,0) [0|1] ""  gtw
 SG_ VCRIGHT_a183_doorFront m183 : 17|1@1+ (1,0) [0|1] ""  gtw
 SG_ VCRIGHT_a224_seatMotorCurrent m224 : 17|12@1- (0.01,0) [-20.48|20.47] "A"  gtw
 SG_ VCRIGHT_a097_VEH_state m97 : 17|1@1+ (1,0) [0|1] ""  gtw
 SG_ VCRIGHT_a104_VEH_bodyControls m104 : 17|1@1+ (1,0) [0|1] ""  gtw
 SG_ VCRIGHT_a146_snsDisconnect m146 : 17|1@1+ (1,0) [0|1] ""  gtw
 SG_ VCRIGHT_a212_openAllowed m212 : 17|1@1+ (1,0) [0|1] ""  gtw
 SG_ VCRIGHT_a142_hvacLowerModeDither m142 : 17|1@1+ (1,0) [0|1] ""  gtw
 SG_ VCRIGHT_a204_openAllowed m204 : 17|1@1+ (1,0) [0|1] ""  gtw
 SG_ VCRIGHT_a116_VEH_vehNm m116 : 17|1@1+ (1,0) [0|1] ""  gtw
 SG_ VCRIGHT_a021_Task1msStarved m21 : 17|1@1+ (1,0) [0|1] ""  gtw
 SG_ VCRIGHT_a136_hvacIntakeDither m136 : 17|1@1+ (1,0) [0|1] ""  gtw
 SG_ VCRIGHT_a262_LVHigh m262 : 17|1@1+ (1,0) [0|1] ""  gtw
 SG_ VCRIGHT_a223_seatMotorCurrent m223 : 17|12@1- (0.01,0) [-20.48|20.47] "A"  gtw
 SG_ VCRIGHT_a102_VEH_feedbackStatus m102 : 17|1@1+ (1,0) [0|1] ""  gtw
 SG_ VCRIGHT_a149_snsDisconnect m149 : 17|1@1+ (1,0) [0|1] ""  gtw
 SG_ VCRIGHT_a060_resetUnlocked m60 : 17|1@1+ (1,0) [0|1] ""  gtw
 SG_ VCRIGHT_a015_NVMMCRCMismatch m15 : 17|1@1+ (1,0) [0|1] ""  gtw
 SG_ VCRIGHT_a141_hvacUpperModeDither m141 : 17|1@1+ (1,0) [0|1] ""  gtw
 SG_ VCRIGHT_a278_PTCMIA m278 : 17|1@1+ (1,0) [0|1] ""  gtw
 SG_ VCRIGHT_a196_NVRAMState m196 : 17|1@1+ (1,0) [0|1] ""  gtw
 SG_ VCRIGHT_a165_windowFront m165 : 17|1@1+ (1,0) [0|1] ""  gtw
 SG_ VCRIGHT_a152_endStopTrusted m152 : 17|1@1+ (1,0) [0|1] ""  gtw
 SG_ VCRIGHT_a147_snsDisconnect m147 : 17|1@1+ (1,0) [0|1] ""  gtw
 SG_ VCRIGHT_a213_openAllowed m213 : 17|1@1+ (1,0) [0|1] ""  gtw
 SG_ VCRIGHT_a228_seatMotorCurrent m228 : 17|12@1- (0.01,0) [-20.48|20.47] "A"  gtw
 SG_ VCRIGHT_a207_openAllowed m207 : 17|1@1+ (1,0) [0|1] ""  gtw
 SG_ VCRIGHT_a231_seatMotorCurrent m231 : 17|12@1- (0.01,0) [-20.48|20.47] "A"  gtw
 SG_ VCRIGHT_a098_VEH_temperature m98 : 17|1@1+ (1,0) [0|1] ""  gtw
 SG_ VCRIGHT_a139_hvacLHVaneDither m139 : 17|1@1+ (1,0) [0|1] ""  gtw
 SG_ VCRIGHT_a166_windowRear m166 : 17|1@1+ (1,0) [0|1] ""  gtw
 SG_ VCRIGHT_a108_VEH_thermalControl m108 : 17|1@1+ (1,0) [0|1] ""  gtw
 SG_ VCRIGHT_a111_VEH_status m111 : 17|1@1+ (1,0) [0|1] ""  gtw
 SG_ VCRIGHT_a110_VEH_carConfig m110 : 17|1@1+ (1,0) [0|1] ""  gtw
 SG_ VCRIGHT_a120_VEH_systemStatus m120 : 17|1@1+ (1,0) [0|1] ""  gtw
 SG_ VCRIGHT_a227_seatMotorCurrent m227 : 17|12@1- (0.01,0) [-20.48|20.47] "A"  gtw
 SG_ VCRIGHT_a164_windowFront m164 : 17|1@1+ (1,0) [0|1] ""  gtw
 SG_ VCRIGHT_a214_openAllowed m214 : 17|1@1+ (1,0) [0|1] ""  gtw
 SG_ VCRIGHT_a109_PARTY_inertial2 m109 : 17|1@1+ (1,0) [0|1] ""  gtw
 SG_ VCRIGHT_a222_seatMotorCurrent m222 : 17|12@1- (0.01,0) [-20.48|20.47] "A"  gtw
 SG_ VCRIGHT_a206_openAllowed m206 : 17|1@1+ (1,0) [0|1] ""  gtw
 SG_ VCRIGHT_a199_NVRAMState m199 : 17|1@1+ (1,0) [0|1] ""  gtw
 SG_ VCRIGHT_a010_UnderVoltageTimeout m10 : 17|1@1+ (1,0) [0|1] ""  gtw
 SG_ VCRIGHT_a221_seatMotorCurrent m221 : 17|12@1- (0.01,0) [-20.48|20.47] "A"  gtw
 SG_ VCRIGHT_a203_openAllowed m203 : 17|1@1+ (1,0) [0|1] ""  gtw
 SG_ VCRIGHT_a216_spiFault m216 : 17|1@1+ (1,0) [0|1] ""  gtw
 SG_ VCRIGHT_a153_endStopTrusted m153 : 17|1@1+ (1,0) [0|1] ""  gtw
 SG_ VCRIGHT_a271_temperatureSensorSN m271 : 17|1@1+ (1,0) [0|1] ""  gtw
 SG_ VCRIGHT_a118_VEH_lighting m118 : 17|1@1+ (1,0) [0|1] ""  gtw
 SG_ VCRIGHT_a107_VEH_vehNm m107 : 17|1@1+ (1,0) [0|1] ""  gtw
 SG_ VCRIGHT_a114_PARTY_wheelSpeeds m114 : 17|1@1+ (1,0) [0|1] ""  gtw
 SG_ VCRIGHT_a113_VEH_hvacRequest m113 : 17|1@1+ (1,0) [0|1] ""  gtw
 SG_ VCRIGHT_a112_VEH_status m112 : 17|1@1+ (1,0) [0|1] ""  gtw
 SG_ VCRIGHT_a210_openAllowed m210 : 17|1@1+ (1,0) [0|1] ""  gtw
 SG_ VCRIGHT_a226_seatMotorCurrent m226 : 17|12@1- (0.01,0) [-20.48|20.47] "A"  gtw
 SG_ VCRIGHT_a100_PARTY m100 : 17|1@1+ (1,0) [0|1] ""  gtw
 SG_ VCRIGHT_a106_VEH_thermalControl m106 : 17|1@1+ (1,0) [0|1] ""  gtw
 SG_ VCRIGHT_a144_snsDisconnect m144 : 17|1@1+ (1,0) [0|1] ""  gtw
 SG_ VCRIGHT_a209_openAllowed m209 : 17|1@1+ (1,0) [0|1] ""  gtw
 SG_ VCRIGHT_a119_VEH_leftStalk m119 : 17|1@1+ (1,0) [0|1] ""  gtw
 SG_ VCRIGHT_a225_seatMotorCurrent m225 : 17|12@1- (0.01,0) [-20.48|20.47] "A"  gtw
 SG_ VCRIGHT_a202_openAllowed m202 : 17|1@1+ (1,0) [0|1] ""  gtw
 SG_ VCRIGHT_a137_hvacLHBleedDither m137 : 17|1@1+ (1,0) [0|1] ""  gtw
 SG_ VCRIGHT_a220_seatMotorCurrent m220 : 17|12@1- (0.01,0) [-20.48|20.47] "A"  gtw
 SG_ VCRIGHT_a002_PowerOnReset m2 : 17|1@1+ (1,0) [0|1] ""  gtw
 SG_ VCRIGHT_a013_ClearQueueFull m13 : 17|1@1+ (1,0) [0|1] ""  gtw
 SG_ VCRIGHT_a140_hvacRHVaneDither m140 : 17|1@1+ (1,0) [0|1] ""  gtw
 SG_ VCRIGHT_a115_VEH_authentication m115 : 17|1@1+ (1,0) [0|1] ""  gtw
 SG_ VCRIGHT_a198_NVRAMState m198 : 17|1@1+ (1,0) [0|1] ""  gtw
 SG_ VCRIGHT_a208_openAllowed m208 : 17|1@1+ (1,0) [0|1] ""  gtw
 SG_ VCRIGHT_a211_openAllowed m211 : 17|1@1+ (1,0) [0|1] ""  gtw
 SG_ VCRIGHT_a103_VEH_vehNm m103 : 17|1@1+ (1,0) [0|1] ""  gtw
 SG_ VCRIGHT_a145_snsDisconnect m145 : 17|1@1+ (1,0) [0|1] ""  gtw
 SG_ VCRIGHT_a197_NVRAMState m197 : 17|1@1+ (1,0) [0|1] ""  gtw
 SG_ VCRIGHT_a117_VEH_vehNm m117 : 17|1@1+ (1,0) [0|1] ""  gtw
 SG_ VCRIGHT_a205_openAllowed m205 : 17|1@1+ (1,0) [0|1] ""  gtw
 SG_ VCRIGHT_a148_snsDisconnect m148 : 17|1@1+ (1,0) [0|1] ""  gtw
 SG_ VCRIGHT_a012_FlashError m12 : 17|1@1+ (1,0) [0|1] ""  gtw
 SG_ VCRIGHT_a138_hvacRHBleedDither m138 : 17|1@1+ (1,0) [0|1] ""  gtw
 SG_ VCRIGHT_a229_seatMotorCurrent m229 : 17|12@1- (0.01,0) [-20.48|20.47] "A"  gtw
 SG_ VCRIGHT_a105_VEH_chNm m105 : 17|1@1+ (1,0) [0|1] ""  gtw
 SG_ VCRIGHT_a230_seatMotorCurrent m230 : 17|12@1- (0.01,0) [-20.48|20.47] "A"  gtw
 SG_ VCRIGHT_a142_hvacLowerModeStall m142 : 16|1@1+ (1,0) [0|1] ""  gtw
 SG_ VCRIGHT_a112_VEH_internalStatus m112 : 16|1@1+ (1,0) [0|1] ""  gtw
 SG_ VCRIGHT_a324_mirrorHeatCurrent m324 : 16|10@1+ (0.01,0) [0|10] "A"  gtw
 SG_ VCRIGHT_a010_UnderVoltageDetecte m10 : 16|1@1+ (1,0) [0|1] ""  gtw
 SG_ VCRIGHT_a021_Task1msLate m21 : 16|1@1+ (1,0) [0|1] ""  gtw
 SG_ VCRIGHT_a249_seatHeatCurrent m249 : 16|12@1+ (0.01,0) [0|40.95] "A"  gtw
 SG_ VCRIGHT_a250_seatHeatTmp m250 : 16|12@1- (0.05,0) [-40|80] "degC"  gtw
 SG_ VCRIGHT_a164_testPassed m164 : 16|1@1+ (1,0) [0|1] ""  gtw
 SG_ VCRIGHT_a207_unknownAllowed m207 : 16|1@1+ (1,0) [0|1] ""  gtw
 SG_ VCRIGHT_a152_zeroed m152 : 16|1@1+ (1,0) [0|1] ""  gtw
 SG_ VCRIGHT_a167_windowPosition m167 : 16|8@1+ (10,0) [0|2550] "ticks"  gtw
 SG_ VCRIGHT_a147_snsShortCircuit m147 : 16|1@1+ (1,0) [0|1] ""  gtw
 SG_ VCRIGHT_a113_VEH_ethNm m113 : 16|1@1+ (1,0) [0|1] ""  gtw
 SG_ VCRIGHT_a255_leftIGBTTemp m255 : 16|8@1- (1,80) [-40|200] "degC"  gtw
 SG_ VCRIGHT_a221_seatMotorCalibrated m221 : 16|1@1+ (1,0) [0|1] ""  gtw
 SG_ VCRIGHT_a148_snsShortCircuit m148 : 16|1@1+ (1,0) [0|1] ""  gtw
 SG_ VCRIGHT_a293_buckleSensorVoltage m293 : 16|12@1- (0.01,0) [-20.48|20.47] "V"  gtw
 SG_ VCRIGHT_a267_seatMotorCurrent m267 : 16|12@1- (0.01,0) [-20.48|20.47] "A"  gtw
 SG_ VCRIGHT_a282_voltage m282 : 16|7@1+ (0.15,0) [0|19] "V"  gtw
 SG_ VCRIGHT_a239_seatHeatCurrent m239 : 16|12@1+ (0.01,0) [0|40.95] "A"  gtw
 SG_ VCRIGHT_a246_seatHeatCurrent m246 : 16|12@1+ (0.01,0) [0|40.95] "A"  gtw
 SG_ VCRIGHT_a184_voltage m184 : 16|7@1+ (0.15,0) [0|19] "V"  gtw
 SG_ VCRIGHT_a120_PARTY_chassisCntl m120 : 16|1@1+ (1,0) [0|1] ""  gtw
 SG_ VCRIGHT_a271_humiditySensorSNA m271 : 16|1@1+ (1,0) [0|1] ""  gtw
 SG_ VCRIGHT_a243_seatHeatCurrent m243 : 16|12@1+ (0.01,0) [0|40.95] "A"  gtw
 SG_ VCRIGHT_a310_mirrorFoldTime m310 : 16|8@1+ (10,0) [0|2550] "ms"  gtw
 SG_ VCRIGHT_a286_windowSpeed m286 : 16|8@1- (100,0) [-12800|12700] "ticksPerSecond"  gtw
 SG_ VCRIGHT_a224_seatMotorCalibrated m224 : 16|1@1+ (1,0) [0|1] ""  gtw
 SG_ VCRIGHT_a214_unknownAllowed m214 : 16|1@1+ (1,0) [0|1] ""  gtw
 SG_ VCRIGHT_a251_seatMotorCurrent m251 : 16|12@1- (0.01,0) [-20.48|20.47] "A"  gtw
 SG_ VCRIGHT_a141_hvacUpperModeStall m141 : 16|1@1+ (1,0) [0|1] ""  gtw
 SG_ VCRIGHT_a236_lumbarAPressureHpa m236 : 16|16@1+ (1,0) [0|65535] ""  gtw
 SG_ VCRIGHT_a157_windowThermalMode m157 : 16|2@1+ (1,0) [0|3] ""  gtw
 SG_ VCRIGHT_a248_seatHeatCurrent m248 : 16|12@1+ (0.01,0) [0|40.95] "A"  gtw
 SG_ VCRIGHT_a043_CallTrace0 m43 : 16|24@1+ (1,0) [0|16777215] ""  gtw
 SG_ VCRIGHT_a277_voltageInmV m277 : 16|16@1+ (1,0) [0|65535] ""  gtw
 SG_ VCRIGHT_a269_seatMotorCurrent m269 : 16|12@1- (0.01,0) [-20.48|20.47] "A"  gtw
 SG_ VCRIGHT_a252_seatMotorCurrent m252 : 16|12@1- (0.01,0) [-20.48|20.47] "A"  gtw
 SG_ VCRIGHT_a270_seatMotorCurrent m270 : 16|12@1- (0.01,0) [-20.48|20.47] "A"  gtw
 SG_ VCRIGHT_a013_LogQueueFull m13 : 16|1@1+ (1,0) [0|1] ""  gtw
 SG_ VCRIGHT_a118_VEH_vehNm m118 : 16|1@1+ (1,0) [0|1] ""  gtw
 SG_ VCRIGHT_a183_testPassed m183 : 16|1@1+ (1,0) [0|1] ""  gtw
 SG_ VCRIGHT_a146_snsShortCircuit m146 : 16|1@1+ (1,0) [0|1] ""  gtw
 SG_ VCRIGHT_a063_switchChannel m63 : 16|8@1+ (1,0) [0|255] ""  gtw
 SG_ VCRIGHT_a194_cntctrPwrCurrent m194 : 16|10@1+ (0.1,0) [0|102.3] "A"  gtw
 SG_ VCRIGHT_a022_TaskInitErrorCount m22 : 16|8@1+ (1,0) [0|255] ""  gtw
 SG_ VCRIGHT_a234_seatMotorCurrent m234 : 16|12@1- (0.01,0) [-20.48|20.47] "A"  gtw
 SG_ VCRIGHT_a216_noData m216 : 16|1@1+ (1,0) [0|1] ""  gtw
 SG_ VCRIGHT_a219_motorChannels m219 : 16|16@1+ (1,0) [0|65535] ""  gtw
 SG_ VCRIGHT_a170_currentPeakCurrent m170 : 16|6@1+ (0.1,0) [0|6.3] "A"  gtw
 SG_ VCRIGHT_a257_MIAStatus m257 : 16|1@1+ (1,0) [0|1] ""  gtw
 SG_ VCRIGHT_a114_PARTY_status m114 : 16|1@1+ (1,0) [0|1] ""  gtw
 SG_ VCRIGHT_a199_outputState m199 : 16|1@1+ (1,0) [0|1] ""  gtw
 SG_ VCRIGHT_a245_seatHeatCurrent m245 : 16|12@1+ (0.01,0) [0|40.95] "A"  gtw
 SG_ VCRIGHT_a139_hvacLHVaneStall m139 : 16|1@1+ (1,0) [0|1] ""  gtw
 SG_ VCRIGHT_a098_VEH_thermalControl m98 : 16|1@1+ (1,0) [0|1] ""  gtw
 SG_ VCRIGHT_a116_PARTY_epbmStatus m116 : 16|1@1+ (1,0) [0|1] ""  gtw
 SG_ VCRIGHT_a212_unknownAllowed m212 : 16|1@1+ (1,0) [0|1] ""  gtw
 SG_ VCRIGHT_a305_handleADCmV m305 : 16|8@1+ (5,0) [0|1000] "mV"  gtw
 SG_ VCRIGHT_a115_VEH_vehNm m115 : 16|1@1+ (1,0) [0|1] ""  gtw
 SG_ VCRIGHT_a046_CallTrace0 m46 : 16|24@1+ (1,0) [0|16777215] ""  gtw
 SG_ VCRIGHT_a260_disarmDelay m260 : 16|7@1+ (10,0) [0|1270] "ms"  gtw
 SG_ VCRIGHT_a195_hvcCurrent m195 : 16|10@1+ (0.1,0) [0|102.3] "A"  gtw
 SG_ VCRIGHT_a222_seatMotorCalibrated m222 : 16|1@1+ (1,0) [0|1] ""  gtw
 SG_ VCRIGHT_a042_Usage1msTask m42 : 16|8@1+ (1,0) [0|255] ""  gtw
 SG_ VCRIGHT_a108_VEH_temperature m108 : 16|1@1+ (1,0) [0|1] ""  gtw
 SG_ VCRIGHT_a104_VEH_chNm m104 : 16|1@1+ (1,0) [0|1] ""  gtw
 SG_ VCRIGHT_a150_windowPosition m150 : 16|8@1+ (10,0) [0|2550] "ticks"  gtw
 SG_ VCRIGHT_a169_currentPeakCurrent m169 : 16|6@1+ (0.1,0) [0|6.3] "A"  gtw
 SG_ VCRIGHT_a119_VEH_steerAngle m119 : 16|1@1+ (1,0) [0|1] ""  gtw
 SG_ VCRIGHT_a242_seatHeatCurrent m242 : 16|12@1+ (0.01,0) [0|40.95] "A"  gtw
 SG_ VCRIGHT_a225_seatMotorCalibrated m225 : 16|1@1+ (1,0) [0|1] ""  gtw
 SG_ VCRIGHT_a287_windowSpeed m287 : 16|8@1- (100,0) [-12800|12700] "ticksPerSecond"  gtw
 SG_ VCRIGHT_a102_VEH_faults m102 : 16|1@1+ (1,0) [0|1] ""  gtw
 SG_ VCRIGHT_a204_unknownAllowed m204 : 16|1@1+ (1,0) [0|1] ""  gtw
 SG_ VCRIGHT_a272_expectedState m272 : 16|2@1+ (1,0) [0|3] ""  gtw
 SG_ VCRIGHT_a263_seatMotorCurrent m263 : 16|12@1- (0.01,0) [-20.48|20.47] "A"  gtw
 SG_ VCRIGHT_a111_VEH_internalStatus m111 : 16|1@1+ (1,0) [0|1] ""  gtw
 SG_ VCRIGHT_a156_windowThermalMode m156 : 16|2@1+ (1,0) [0|3] ""  gtw
 SG_ VCRIGHT_a188_voltage m188 : 16|7@1+ (0.15,0) [0|19] "V"  gtw
 SG_ VCRIGHT_a110_VEH_carState m110 : 16|1@1+ (1,0) [0|1] ""  gtw
 SG_ VCRIGHT_a193_amplifierCurrent m193 : 16|10@1+ (0.1,0) [0|102.3] "A"  gtw
 SG_ VCRIGHT_a276_mirrorDebugType m276 : 16|3@1+ (1,0) [0|6] ""  gtw
 SG_ VCRIGHT_a231_seatMotorCalibrated m231 : 16|1@1+ (1,0) [0|1] ""  gtw
 SG_ VCRIGHT_a266_seatMotorCurrent m266 : 16|12@1- (0.01,0) [-20.48|20.47] "A"  gtw
 SG_ VCRIGHT_a323_positionStart m323 : 16|10@1+ (2,0) [0|2046] "ticks"  gtw
 SG_ VCRIGHT_a012_ClockError m12 : 16|1@1+ (1,0) [0|1] ""  gtw
 SG_ VCRIGHT_a228_seatMotorCalibrated m228 : 16|1@1+ (1,0) [0|1] ""  gtw
 SG_ VCRIGHT_a101_VEH_state m101 : 16|1@1+ (1,0) [0|1] ""  gtw
 SG_ VCRIGHT_a218_motorChannels m218 : 16|16@1+ (1,0) [0|65535] ""  gtw
 SG_ VCRIGHT_a265_seatMotorCurrent m265 : 16|12@1- (0.01,0) [-20.48|20.47] "A"  gtw
 SG_ VCRIGHT_a307_disconnectedTime m307 : 16|10@1+ (1,0) [0|1000] "ms"  gtw
 SG_ VCRIGHT_a202_unknownAllowed m202 : 16|1@1+ (1,0) [0|1] ""  gtw
 SG_ VCRIGHT_a291_buckleSensorVoltage m291 : 16|12@1+ (0.01,0) [0|40.95] "V"  gtw
 SG_ VCRIGHT_a198_outputState m198 : 16|1@1+ (1,0) [0|1] ""  gtw
 SG_ VCRIGHT_a138_hvacRHBleedStall m138 : 16|1@1+ (1,0) [0|1] ""  gtw
 SG_ VCRIGHT_a103_VEH_hvsNm m103 : 16|1@1+ (1,0) [0|1] ""  gtw
 SG_ VCRIGHT_a244_seatHeatTmp m244 : 16|12@1- (0.05,0) [-40|80] "degC"  gtw
 SG_ VCRIGHT_a223_seatMotorCalibrated m223 : 16|1@1+ (1,0) [0|1] ""  gtw
 SG_ VCRIGHT_a304_handleADCmV m304 : 16|8@1+ (5,0) [0|1000] "mV"  gtw
 SG_ VCRIGHT_a268_seatMotorCurrent m268 : 16|12@1- (0.01,0) [-20.48|20.47] "A"  gtw
 SG_ VCRIGHT_a155_windowThermalMode m155 : 16|2@1+ (1,0) [0|3] ""  gtw
 SG_ VCRIGHT_a186_voltage m186 : 16|7@1+ (0.15,0) [0|19] "V"  gtw
 SG_ VCRIGHT_a253_seatMotorCurrent m253 : 16|12@1- (0.01,0) [-20.48|20.47] "A"  gtw
 SG_ VCRIGHT_a109_PARTY_status m109 : 16|1@1+ (1,0) [0|1] ""  gtw
 SG_ VCRIGHT_a235_seatMotorCurrent m235 : 16|12@1- (0.01,0) [-20.48|20.47] "A"  gtw
 SG_ VCRIGHT_a226_seatMotorCalibrated m226 : 16|1@1+ (1,0) [0|1] ""  gtw
 SG_ VCRIGHT_a241_seatHeatTmp m241 : 16|12@1- (0.05,0) [-40|80] "degC"  gtw
 SG_ VCRIGHT_a185_summonFaultReason m185 : 16|5@1+ (1,0) [0|28] ""  gtw
 SG_ VCRIGHT_a230_seatMotorCalibrated m230 : 16|1@1+ (1,0) [0|1] ""  gtw
 SG_ VCRIGHT_a211_unknownAllowed m211 : 16|1@1+ (1,0) [0|1] ""  gtw
 SG_ VCRIGHT_a030_logId m30 : 16|4@1+ (1,0) [0|15] ""  gtw
 SG_ VCRIGHT_a180_intButtonPressed m180 : 16|1@1+ (1,0) [0|1] ""  gtw
 SG_ VCRIGHT_a045_CallTrace0 m45 : 16|24@1+ (1,0) [0|16777215] ""  gtw
 SG_ VCRIGHT_a229_seatMotorCalibrated m229 : 16|1@1+ (1,0) [0|1] ""  gtw
 SG_ VCRIGHT_a208_unknownAllowed m208 : 16|1@1+ (1,0) [0|1] ""  gtw
 SG_ VCRIGHT_a168_windowPosition m168 : 16|8@1+ (10,0) [0|2550] "ticks"  gtw
 SG_ VCRIGHT_a217_byte4 m217 : 16|8@1+ (1,0) [0|255] ""  gtw
 SG_ VCRIGHT_a254_seatMotorCurrent m254 : 16|12@1- (0.01,0) [-20.48|20.47] "A"  gtw
 SG_ VCRIGHT_a100_VEH m100 : 16|1@1+ (1,0) [0|1] ""  gtw
 SG_ VCRIGHT_a136_hvacIntakeStall m136 : 16|1@1+ (1,0) [0|1] ""  gtw
 SG_ VCRIGHT_a322_positionStart m322 : 16|10@1+ (2,0) [0|2046] "ticks"  gtw
 SG_ VCRIGHT_a015_NVMMRecordNotFound m15 : 16|1@1+ (1,0) [0|1] ""  gtw
 SG_ VCRIGHT_a232_seatMotorCurrent m232 : 16|12@1- (0.01,0) [-20.48|20.47] "A"  gtw
 SG_ VCRIGHT_a189_voltage m189 : 16|7@1+ (0.15,0) [0|19] "V"  gtw
 SG_ VCRIGHT_a278_HVLow m278 : 16|1@1+ (1,0) [0|1] ""  gtw
 SG_ VCRIGHT_a059_voltageDrop m59 : 16|12@1+ (0.005443676098,0) [0|22.29185] "V"  gtw
 SG_ VCRIGHT_a106_VEH_dcdcStatus m106 : 16|1@1+ (1,0) [0|1] ""  gtw
 SG_ VCRIGHT_a145_snsShortCircuit m145 : 16|1@1+ (1,0) [0|1] ""  gtw
 SG_ VCRIGHT_a205_unknownAllowed m205 : 16|1@1+ (1,0) [0|1] ""  gtw
 SG_ VCRIGHT_a041_CPULoadTotal m41 : 16|8@1+ (1,0) [0|255] ""  gtw
 SG_ VCRIGHT_a197_outputState m197 : 16|1@1+ (1,0) [0|1] ""  gtw
 SG_ VCRIGHT_a190_eFuseTripCount m190 : 16|8@1+ (1,0) [0|255] ""  gtw
 SG_ VCRIGHT_a166_windowFront m166 : 16|1@1+ (1,0) [0|1] ""  gtw
 SG_ VCRIGHT_a206_unknownAllowed m206 : 16|1@1+ (1,0) [0|1] ""  gtw
 SG_ VCRIGHT_a154_windowThermalMode m154 : 16|2@1+ (1,0) [0|3] ""  gtw
 SG_ VCRIGHT_a003_AssertID m3 : 16|16@1+ (1,0) [0|65535] ""  gtw
 SG_ VCRIGHT_a165_testPassed m165 : 16|1@1+ (1,0) [0|1] ""  gtw
 SG_ VCRIGHT_a105_VEH_states m105 : 16|1@1+ (1,0) [0|1] ""  gtw
 SG_ VCRIGHT_a290_occupancySensorV m290 : 16|12@1- (0.01,0) [-20.48|20.47] "V"  gtw
 SG_ VCRIGHT_a187_voltage m187 : 16|7@1+ (0.15,0) [0|19] "V"  gtw
 SG_ VCRIGHT_a240_seatHeatCurrent m240 : 16|12@1+ (0.01,0) [0|40.95] "A"  gtw
 SG_ VCRIGHT_a107_VEH_hvsNm m107 : 16|1@1+ (1,0) [0|1] ""  gtw
 SG_ VCRIGHT_a227_seatMotorCalibrated m227 : 16|1@1+ (1,0) [0|1] ""  gtw
 SG_ VCRIGHT_a153_zeroed m153 : 16|1@1+ (1,0) [0|1] ""  gtw
 SG_ VCRIGHT_a258_bootIdFreq m258 : 16|8@1+ (0.02,0) [0|5.1] "Hz"  gtw
 SG_ VCRIGHT_a203_unknownAllowed m203 : 16|1@1+ (1,0) [0|1] ""  gtw
 SG_ VCRIGHT_a140_hvacRHVaneStall m140 : 16|1@1+ (1,0) [0|1] ""  gtw
 SG_ VCRIGHT_a274_handlePWM m274 : 16|7@1+ (1,0) [0|100] "%"  gtw
 SG_ VCRIGHT_a306_disconnectedTime m306 : 16|10@1+ (1,0) [0|1000] "ms"  gtw
 SG_ VCRIGHT_a137_hvacLHBleedStall m137 : 16|1@1+ (1,0) [0|1] ""  gtw
 SG_ VCRIGHT_a000_alertDataW0 m0 : 16|16@1+ (1,0) [0|65535] ""  X
 SG_ VCRIGHT_a238_lumbarAPressureHpa m238 : 16|16@1+ (1,0) [0|65535] ""  gtw
 SG_ VCRIGHT_a264_seatMotorCurrent m264 : 16|12@1- (0.01,0) [-20.48|20.47] "A"  gtw
 SG_ VCRIGHT_a201_voltage m201 : 16|7@1+ (0.15,0) [0|19] "V"  gtw
 SG_ VCRIGHT_a321_positionStart m321 : 16|10@1+ (2,0) [0|2046] "ticks"  gtw
 SG_ VCRIGHT_a273_handlePWM m273 : 16|7@1+ (1,0) [0|100] "%"  gtw
 SG_ VCRIGHT_a002_CPUUndervoltage m2 : 16|1@1+ (1,0) [0|1] ""  gtw
 SG_ VCRIGHT_a237_lumbarAPressureHpa m237 : 16|16@1+ (1,0) [0|65535] ""  gtw
 SG_ VCRIGHT_a144_snsShortCircuit m144 : 16|1@1+ (1,0) [0|1] ""  gtw
 SG_ VCRIGHT_a196_outputState m196 : 16|1@1+ (1,0) [0|1] ""  gtw
 SG_ VCRIGHT_a044_CallTrace0 m44 : 16|24@1+ (1,0) [0|16777215] ""  gtw
 SG_ VCRIGHT_a247_seatHeatTmp m247 : 16|12@1- (0.05,0) [-40|80] "degC"  gtw
 SG_ VCRIGHT_a215_desyncCount m215 : 16|8@1+ (1,0) [0|255] ""  gtw
 SG_ VCRIGHT_a283_voltage m283 : 16|7@1+ (0.15,0) [0|19] "V"  gtw
 SG_ VCRIGHT_a292_buckleSensorVoltage m292 : 16|12@1- (0.01,0) [-20.48|20.47] "V"  gtw
 SG_ VCRIGHT_a064_busBitField m64 : 16|8@1+ (1,0) [0|255] ""  gtw
 SG_ VCRIGHT_a256_leftCurrent m256 : 16|8@1+ (0.2,0) [0|50] "A"  gtw
 SG_ VCRIGHT_a149_snsShortCircuit m149 : 16|1@1+ (1,0) [0|1] ""  gtw
 SG_ VCRIGHT_a220_seatMotorCalibrated m220 : 16|1@1+ (1,0) [0|1] ""  gtw
 SG_ VCRIGHT_a259_disarmDelay m259 : 16|7@1+ (10,0) [0|1270] "ms"  gtw
 SG_ VCRIGHT_a181_intButtonPressed m181 : 16|1@1+ (1,0) [0|1] ""  gtw
 SG_ VCRIGHT_a233_seatMotorCurrent m233 : 16|12@1- (0.01,0) [-20.48|20.47] "A"  gtw
 SG_ VCRIGHT_a210_unknownAllowed m210 : 16|1@1+ (1,0) [0|1] ""  gtw
 SG_ VCRIGHT_a209_unknownAllowed m209 : 16|1@1+ (1,0) [0|1] ""  gtw
 SG_ VCRIGHT_a001_InternalWatchdog m1 : 16|1@1+ (1,0) [0|1] ""  gtw
 SG_ VCRIGHT_a099_VEH_oocStatus m99 : 16|1@1+ (1,0) [0|1] ""  gtw
 SG_ VCRIGHT_a060_lockoutDisabled m60 : 16|1@1+ (1,0) [0|1] ""  gtw
 SG_ VCRIGHT_a262_LVLow m262 : 16|1@1+ (1,0) [0|1] ""  gtw
 SG_ VCRIGHT_a117_PARTY_epbmStatus m117 : 16|1@1+ (1,0) [0|1] ""  gtw
 SG_ VCRIGHT_a213_unknownAllowed m213 : 16|1@1+ (1,0) [0|1] ""  gtw
 SG_ VCRIGHT_a320_positionStart m320 : 16|10@1+ (2,0) [0|2046] "ticks"  gtw
 SG_ VCRIGHT_a097_VEH_HVStatus m97 : 16|1@1+ (1,0) [0|1] ""  gtw
 SG_ VCRIGHT_a151_windowPosition m151 : 16|8@1+ (10,0) [0|2550] "ticks"  gtw
 SG_ VCRIGHT_a200_voltage m200 : 16|7@1+ (0.15,0) [0|19] "V"  gtw
 SG_ VCRIGHT_alertType : 15|1@1+ (1,0) [0|1] ""  gtw
 SG_ VCRIGHT_alertID M : 0|9@1+ (1,0) [0|324] ""  gtw

BO_ 2002 BMS_debugInfo_1Hz: 8 VEH
 SG_ BMS_energyVariableChgRequested m2 : 62|1@1+ (1,0) [0|1] ""  X
 SG_ BMS_energyInitialPackTemp m3 : 56|8@1- (1,40) [-40|120] "C"  X
 SG_ BMS_dbgStackUse_UDS m4 : 54|10@1+ (1,0) [0|1023] ""  X
 SG_ BMS_brickBleed51 m0 : 53|1@1+ (1,0) [0|1] ""  X
 SG_ BMS_brickBleed50 m0 : 52|1@1+ (1,0) [0|1] ""  X
 SG_ BMS_energyStopTarget m2 : 52|10@1+ (0.1,0) [0|102.2] "KWh"  dbg
 SG_ BMS_brickBleed49 m0 : 51|1@1+ (1,0) [0|1] ""  X
 SG_ BMS_brickBleed48 m0 : 50|1@1+ (1,0) [0|1] ""  X
 SG_ BMS_brickBleed47 m0 : 49|1@1+ (1,0) [0|1] ""  X
 SG_ BMS_brickBleed46 m0 : 48|1@1+ (1,0) [0|1] ""  X
 SG_ BMS_brickBleed45 m0 : 47|1@1+ (1,0) [0|1] ""  X
 SG_ BMS_brickBleed96 m1 : 47|1@1+ (1,0) [0|1] ""  X
 SG_ BMS_brickBleed44 m0 : 46|1@1+ (1,0) [0|1] ""  X
 SG_ BMS_brickBleed95 m1 : 46|1@1+ (1,0) [0|1] ""  X
 SG_ BMS_brickBleed43 m0 : 45|1@1+ (1,0) [0|1] ""  X
 SG_ BMS_brickBleed94 m1 : 45|1@1+ (1,0) [0|1] ""  X
 SG_ BMS_dbgStackUse_1KHz m4 : 44|10@1+ (1,0) [0|1023] ""  X
 SG_ BMS_brickBleed42 m0 : 44|1@1+ (1,0) [0|1] ""  X
 SG_ BMS_brickBleed93 m1 : 44|1@1+ (1,0) [0|1] ""  X
 SG_ BMS_brickBleed92 m1 : 43|1@1+ (1,0) [0|1] ""  X
 SG_ BMS_brickBleed41 m0 : 43|1@1+ (1,0) [0|1] ""  X
 SG_ BMS_brickBleed91 m1 : 42|1@1+ (1,0) [0|1] ""  X
 SG_ BMS_energyChgTargetPackSoc m2 : 42|10@1+ (1,0) [0|1023] "%"  X
 SG_ BMS_brickBleed40 m0 : 42|1@1+ (1,0) [0|1] ""  X
 SG_ BMS_brickBleed90 m1 : 41|1@1+ (1,0) [0|1] ""  X
 SG_ BMS_brickBleed39 m0 : 41|1@1+ (1,0) [0|1] ""  X
 SG_ BMS_brickBleed89 m1 : 40|1@1+ (1,0) [0|1] ""  X
 SG_ BMS_energyLatchedAveCac m3 : 40|12@1+ (0.1,0) [0|409.5] "Ah"  X
 SG_ BMS_brickBleed38 m0 : 40|1@1+ (1,0) [0|1] ""  X
 SG_ BMS_brickBleed88 m1 : 39|1@1+ (1,0) [0|1] ""  X
 SG_ BMS_brickBleed37 m0 : 39|1@1+ (1,0) [0|1] ""  X
 SG_ BMS_brickBleed36 m0 : 38|1@1+ (1,0) [0|1] ""  X
 SG_ BMS_brickBleed87 m1 : 38|1@1+ (1,0) [0|1] ""  X
 SG_ BMS_brickBleed86 m1 : 37|1@1+ (1,0) [0|1] ""  X
 SG_ BMS_brickBleed35 m0 : 37|1@1+ (1,0) [0|1] ""  X
 SG_ BMS_brickBleed85 m1 : 36|1@1+ (1,0) [0|1] ""  X
 SG_ BMS_brickBleed34 m0 : 36|1@1+ (1,0) [0|1] ""  X
 SG_ BMS_dchAhLimitingBrickIndex m2 : 35|7@1+ (1,0) [0|127] ""  X
 SG_ BMS_brickBleed84 m1 : 35|1@1+ (1,0) [0|1] ""  X
 SG_ BMS_brickBleed33 m0 : 35|1@1+ (1,0) [0|1] ""  X
 SG_ BMS_brickBleed83 m1 : 34|1@1+ (1,0) [0|1] ""  X
 SG_ BMS_brickBleed32 m0 : 34|1@1+ (1,0) [0|1] ""  X
 SG_ BMS_dbgStackUse_100Hz m4 : 34|10@1+ (1,0) [0|1023] ""  X
 SG_ BMS_brickBleed82 m1 : 33|1@1+ (1,0) [0|1] ""  X
 SG_ BMS_brickBleed31 m0 : 33|1@1+ (1,0) [0|1] ""  X
 SG_ BMS_brickBleed30 m0 : 32|1@1+ (1,0) [0|1] ""  X
 SG_ BMS_brickBleed81 m1 : 32|1@1+ (1,0) [0|1] ""  X
 SG_ BMS_brickBleed29 m0 : 31|1@1+ (1,0) [0|1] ""  X
 SG_ BMS_brickBleed80 m1 : 31|1@1+ (1,0) [0|1] ""  X
 SG_ BMS_brickBleed28 m0 : 30|1@1+ (1,0) [0|1] ""  X
 SG_ BMS_brickBleed79 m1 : 30|1@1+ (1,0) [0|1] ""  X
 SG_ BMS_brickBleed78 m1 : 29|1@1+ (1,0) [0|1] ""  X
 SG_ BMS_brickBleed27 m0 : 29|1@1+ (1,0) [0|1] ""  X
 SG_ BMS_energyLatchedMinCac m3 : 28|12@1+ (0.1,0) [0|409.5] "Ah"  X
 SG_ BMS_chgAhLimitingBrickIndex m2 : 28|7@1+ (1,0) [0|127] ""  X
 SG_ BMS_brickBleed77 m1 : 28|1@1+ (1,0) [0|1] ""  X
 SG_ BMS_brickBleed26 m0 : 28|1@1+ (1,0) [0|1] ""  X
 SG_ BMS_brickBleed25 m0 : 27|1@1+ (1,0) [0|1] ""  X
 SG_ BMS_brickBleed76 m1 : 27|1@1+ (1,0) [0|1] ""  X
 SG_ BMS_brickBleed75 m1 : 26|1@1+ (1,0) [0|1] ""  X
 SG_ BMS_brickBleed24 m0 : 26|1@1+ (1,0) [0|1] ""  X
 SG_ BMS_brickBleed23 m0 : 25|1@1+ (1,0) [0|1] ""  X
 SG_ BMS_brickBleed74 m1 : 25|1@1+ (1,0) [0|1] ""  X
 SG_ BMS_dbgStackUse_10Hz m4 : 24|10@1+ (1,0) [0|1023] ""  X
 SG_ BMS_brickBleed22 m0 : 24|1@1+ (1,0) [0|1] ""  X
 SG_ BMS_brickBleed73 m1 : 24|1@1+ (1,0) [0|1] ""  X
 SG_ BMS_brickBleed72 m1 : 23|1@1+ (1,0) [0|1] ""  X
 SG_ BMS_brickBleed21 m0 : 23|1@1+ (1,0) [0|1] ""  X
 SG_ BMS_brickBleed71 m1 : 22|1@1+ (1,0) [0|1] ""  X
 SG_ BMS_brickBleed20 m0 : 22|1@1+ (1,0) [0|1] ""  X
 SG_ BMS_brickBleed19 m0 : 21|1@1+ (1,0) [0|1] ""  X
 SG_ BMS_brickBleed70 m1 : 21|1@1+ (1,0) [0|1] ""  X
 SG_ BMS_brickBleed18 m0 : 20|1@1+ (1,0) [0|1] ""  X
 SG_ BMS_brickBleed69 m1 : 20|1@1+ (1,0) [0|1] ""  X
 SG_ BMS_brickBleed68 m1 : 19|1@1+ (1,0) [0|1] ""  X
 SG_ BMS_brickBleed17 m0 : 19|1@1+ (1,0) [0|1] ""  X
 SG_ BMS_brickBleed67 m1 : 18|1@1+ (1,0) [0|1] ""  X
 SG_ BMS_brickBleed16 m0 : 18|1@1+ (1,0) [0|1] ""  X
 SG_ BMS_energyLatchedAveSoc m3 : 18|10@1+ (0.1,0) [0|102.3] "%"  X
 SG_ BMS_brickBleed66 m1 : 17|1@1+ (1,0) [0|1] ""  X
 SG_ BMS_brickBleed15 m0 : 17|1@1+ (1,0) [0|1] ""  X
 SG_ BMS_brickBleed14 m0 : 16|1@1+ (1,0) [0|1] ""  X
 SG_ BMS_energyDchAhRemaining m2 : 16|12@1+ (0.1,0) [0|409.5] "Ah"  X
 SG_ BMS_brickBleed65 m1 : 16|1@1+ (1,0) [0|1] ""  X
 SG_ BMS_brickBleed13 m0 : 15|1@1+ (1,0) [0|1] ""  X
 SG_ BMS_brickBleed64 m1 : 15|1@1+ (1,0) [0|1] ""  X
 SG_ BMS_brickBleed12 m0 : 14|1@1+ (1,0) [0|1] ""  X
 SG_ BMS_brickBleed63 m1 : 14|1@1+ (1,0) [0|1] ""  X
 SG_ BMS_dbgStackUse_1Hz m4 : 13|10@1+ (1,0) [0|1023] ""  X
 SG_ BMS_brickBleed11 m0 : 13|1@1+ (1,0) [0|1] ""  X
 SG_ BMS_brickBleed62 m1 : 13|1@1+ (1,0) [0|1] ""  X
 SG_ BMS_brickBleed61 m1 : 12|1@1+ (1,0) [0|1] ""  X
 SG_ BMS_brickBleed10 m0 : 12|1@1+ (1,0) [0|1] ""  X
 SG_ BMS_brickBleed9 m0 : 11|1@1+ (1,0) [0|1] ""  X
 SG_ BMS_brickBleed60 m1 : 11|1@1+ (1,0) [0|1] ""  X
 SG_ BMS_brickBleed8 m0 : 10|1@1+ (1,0) [0|1] ""  X
 SG_ BMS_brickBleed59 m1 : 10|1@1+ (1,0) [0|1] ""  X
 SG_ BMS_brickBleed7 m0 : 9|1@1+ (1,0) [0|1] ""  X
 SG_ BMS_brickBleed58 m1 : 9|1@1+ (1,0) [0|1] ""  X
 SG_ BMS_brickBleed57 m1 : 8|1@1+ (1,0) [0|1] ""  X
 SG_ BMS_brickBleed6 m0 : 8|1@1+ (1,0) [0|1] ""  X
 SG_ BMS_energyLatchedMinSoc m3 : 8|10@1+ (0.1,0) [0|102.3] "%"  X
 SG_ BMS_brickBleed56 m1 : 7|1@1+ (1,0) [0|1] ""  X
 SG_ BMS_brickBleed5 m0 : 7|1@1+ (1,0) [0|1] ""  X
 SG_ BMS_brickBleed55 m1 : 6|1@1+ (1,0) [0|1] ""  X
 SG_ BMS_brickBleed4 m0 : 6|1@1+ (1,0) [0|1] ""  X
 SG_ BMS_brickBleed54 m1 : 5|1@1+ (1,0) [0|1] ""  X
 SG_ BMS_brickBleed3 m0 : 5|1@1+ (1,0) [0|1] ""  X
 SG_ BMS_brickBleed53 m1 : 4|1@1+ (1,0) [0|1] ""  X
 SG_ BMS_brickBleed2 m0 : 4|1@1+ (1,0) [0|1] ""  X
 SG_ BMS_brickBleed1 m0 : 3|1@1+ (1,0) [0|1] ""  X
 SG_ BMS_energyChgAhRemaining m2 : 3|12@1+ (0.1,0) [0|409.5] "Ah"  X
 SG_ BMS_dbgStackUse_Idle m4 : 3|10@1+ (1,0) [0|1023] ""  X
 SG_ BMS_brickBleed52 m1 : 3|1@1+ (1,0) [0|1] ""  X
 SG_ BMS_1HzDebug_Id M : 0|3@1+ (1,0) [0|5] ""  X

BO_ 869 SCS_alertMatrix1: 8 VEH
 SG_ SCS_a064_vehicleCommandTimeout : 63|1@1+ (1,0) [0|1] ""  gtw
 SG_ SCS_a063_canRationality : 62|1@1+ (1,0) [0|1] ""  gtw
 SG_ SCS_a062_unused : 61|1@1+ (1,0) [0|1] ""  gtw
 SG_ SCS_a061_postOutOfService : 60|1@1+ (1,0) [0|1] ""  gtw
 SG_ SCS_a060_swHVIL : 59|1@1+ (1,0) [0|1] ""  gtw
 SG_ SCS_a059_memoryError : 58|1@1+ (1,0) [0|1] ""  gtw
 SG_ SCS_a058_adcRef : 57|1@1+ (1,0) [0|1] ""  gtw
 SG_ SCS_a057_watchdogReset : 56|1@1+ (1,0) [0|1] ""  gtw
 SG_ SCS_a056_stateTransitionDenied : 55|1@1+ (1,0) [0|1] ""  gtw
 SG_ SCS_a055_coolantLevelLow : 54|1@1+ (1,0) [0|1] ""  gtw
 SG_ SCS_a054_pumpRegulation : 53|1@1+ (1,0) [0|1] ""  gtw
 SG_ SCS_a053_unexpectedThermalBehavi : 52|1@1+ (1,0) [0|1] ""  gtw
 SG_ SCS_a052_ambientTempRationality : 51|1@1+ (1,0) [0|1] ""  gtw
 SG_ SCS_a051_cordTempRationality : 50|1@1+ (1,0) [0|1] ""  gtw
 SG_ SCS_a050_coolantTempRationality : 49|1@1+ (1,0) [0|1] ""  gtw
 SG_ SCS_a049_pcbaTempRationality : 48|1@1+ (1,0) [0|1] ""  gtw
 SG_ SCS_a048_ambientOT : 47|1@1+ (1,0) [0|1] ""  gtw
 SG_ SCS_a047_cordOT : 46|1@1+ (1,0) [0|1] ""  gtw
 SG_ SCS_a046_coolantOT : 45|1@1+ (1,0) [0|1] ""  gtw
 SG_ SCS_a045_pcbaOT : 44|1@1+ (1,0) [0|1] ""  gtw
 SG_ SCS_a044_proximityRationality : 43|1@1+ (1,0) [0|1] ""  gtw
 SG_ SCS_a043_pilotRationality : 42|1@1+ (1,0) [0|1] ""  gtw
 SG_ SCS_a042_pilotOutOfRange : 41|1@1+ (1,0) [0|1] ""  gtw
 SG_ SCS_a041_minus12VOutOfRange : 40|1@1+ (1,0) [0|1] ""  gtw
 SG_ SCS_a040_plus12VOutOfRange : 39|1@1+ (1,0) [0|1] ""  gtw
 SG_ SCS_a039_ibatRegulation : 38|1@1+ (1,0) [0|1] ""  gtw
 SG_ SCS_a038_contactorFailedOpen : 37|1@1+ (1,0) [0|1] ""  gtw
 SG_ SCS_a037_outputContactorWelded : 36|1@1+ (1,0) [0|1] ""  gtw
 SG_ SCS_a036_internalContactorWelded : 35|1@1+ (1,0) [0|1] ""  gtw
 SG_ SCS_a035_unexpectedVbusBehavior : 34|1@1+ (1,0) [0|1] ""  gtw
 SG_ SCS_a034_IBatRationality : 33|1@1+ (1,0) [0|1] ""  gtw
 SG_ SCS_a033_VBusRationality : 32|1@1+ (1,0) [0|1] ""  gtw
 SG_ SCS_a032_VBatRationality : 31|1@1+ (1,0) [0|1] ""  gtw
 SG_ SCS_a031_IbatOC : 30|1@1+ (1,0) [0|1] ""  gtw
 SG_ SCS_a030_VbusOV : 29|1@1+ (1,0) [0|1] ""  gtw
 SG_ SCS_a029_VbatOV : 28|1@1+ (1,0) [0|1] ""  gtw
 SG_ SCS_a028_isolationRationality : 27|1@1+ (1,0) [0|1] ""  gtw
 SG_ SCS_a027_externalIsolationLow : 26|1@1+ (1,0) [0|1] ""  gtw
 SG_ SCS_a026_internalIsolationLow : 25|1@1+ (1,0) [0|1] ""  gtw
 SG_ SCS_a025_internalIsolationFault : 24|1@1+ (1,0) [0|1] ""  gtw
 SG_ SCS_a024_emergencyShutdown : 23|1@1+ (1,0) [0|1] ""  gtw
 SG_ SCS_a021_unusedHW21 : 20|1@1+ (1,0) [0|1] ""  gtw
 SG_ SCS_a020_unusedHW20 : 19|1@1+ (1,0) [0|1] ""  gtw
 SG_ SCS_a019_unusedHW19 : 18|1@1+ (1,0) [0|1] ""  gtw
 SG_ SCS_a018_unusedHW18 : 17|1@1+ (1,0) [0|1] ""  gtw
 SG_ SCS_a017_unusedHW17 : 16|1@1+ (1,0) [0|1] ""  gtw
 SG_ SCS_a016_unusedHW16 : 15|1@1+ (1,0) [0|1] ""  gtw
 SG_ SCS_a015_unusedHW15 : 14|1@1+ (1,0) [0|1] ""  gtw
 SG_ SCS_a014_coolantTempHiFoldBk : 13|1@1+ (1,0) [0|1] ""  gtw
 SG_ SCS_a013_cordTempHiFoldBk : 12|1@1+ (1,0) [0|1] ""  gtw
 SG_ SCS_a012_hwIllegalCntrCmdV2 : 11|1@1+ (1,0) [0|1] ""  gtw
 SG_ SCS_a011_hwIllegalCntrCmdInt : 10|1@1+ (1,0) [0|1] ""  gtw
 SG_ SCS_a010_hwIllegalCntrCmdV1 : 9|1@1+ (1,0) [0|1] ""  gtw
 SG_ SCS_a009_hwOpen_V2 : 8|1@1+ (1,0) [0|1] ""  gtw
 SG_ SCS_a008_hwOpen_V1 : 7|1@1+ (1,0) [0|1] ""  gtw
 SG_ SCS_a007_hwWeld_V2 : 6|1@1+ (1,0) [0|1] ""  gtw
 SG_ SCS_a006_hwWeld_V1 : 5|1@1+ (1,0) [0|1] ""  gtw
 SG_ SCS_a005_hwHVIL : 4|1@1+ (1,0) [0|1] ""  gtw
 SG_ SCS_a004_hwVbusOV : 3|1@1+ (1,0) [0|1] ""  gtw
 SG_ SCS_a003_hwCordOT : 2|1@1+ (1,0) [0|1] ""  gtw
 SG_ SCS_a002_hwIbatOC : 1|1@1+ (1,0) [0|1] ""  gtw
 SG_ SCS_a001_hwDSPfault : 0|1@1+ (1,0) [0|1] ""  gtw

BO_ 1571 VCLEFT_udsResponse: 8 VEH
 SG_ VCLEFT_udsResponseData_L : 39|32@0+ (1,0) [0|4294967295] ""  gtw
 SG_ VCLEFT_udsResponseData_H : 7|32@0+ (1,0) [0|4294967295] ""  gtw

BO_ 605 CP_status: 8 VEH
 SG_ CP_coldWeatherMode : 63|1@1+ (1,0) [0|1] ""  gtw
 SG_ CP_numAlertsSet : 56|7@1+ (1,0) [0|127] ""  X
 SG_ CP_vehicleUnlockRequest : 55|1@1+ (1,0) [0|1] ""  gtw
 SG_ CP_chargeDoorOpenUI : 54|1@1+ (1,0) [0|1] ""  gtw
 SG_ CP_inductiveSensorState : 51|3@1+ (1,0) [0|6] ""  gtw
 SG_ CP_inductiveDoorState : 48|3@1+ (1,0) [0|7] ""  gtw
 SG_ CP_faultLineSensed : 46|1@1+ (1,0) [0|1] ""  gtw
 SG_ CP_doorOpenRequested : 45|1@1+ (1,0) [0|1] ""  gtw
 SG_ CP_UHF_handleFound : 44|1@1+ (1,0) [0|1] ""  gtw
 SG_ CP_UHF_controlState : 40|4@1+ (1,0) [0|10] ""  gtw
 SG_ CP_swcanRelayClosed : 37|1@1+ (1,0) [0|1] ""  gtw
 SG_ CP_ledColor : 33|4@1+ (1,0) [0|10] ""  gtw
 SG_ CP_doorButtonPressed : 32|1@1+ (1,0) [0|1] ""  gtw
 SG_ CP_apsVoltage : 24|8@1+ (0.071568627,0) [0|18.249] "V"  X
 SG_ CP_latch2ControlState : 19|3@1+ (1,0) [0|5] ""  X
 SG_ CP_latchControlState : 16|3@1+ (1,0) [0|5] ""  gtw
 SG_ CP_doorControlState : 11|3@1+ (1,0) [0|6] ""  gtw
 SG_ CP_chargeDoorOpen : 10|1@1+ (1,0) [0|1] ""  dbg
 SG_ CP_latch2State : 8|2@1+ (1,0) [0|3] ""  X
 SG_ CP_latchState : 5|2@1+ (1,0) [0|3] ""  gtw
 SG_ CP_chargeCableSecured : 4|1@1+ (1,0) [0|1] ""  gtw
 SG_ CP_chargeCablePresent : 3|1@1+ (1,0) [0|1] ""  di
 SG_ CP_insertEnableLine : 2|1@1+ (1,0) [0|1] ""  gtw
 SG_ CP_type : 0|2@1+ (1,0) [0|3] ""  X

BO_ 1494 DIS_thermalTargets: 3 VEH
 SG_ DIS_inletTargetFlow : 14|7@1+ (1,0) [0|100] "DegC"  X
 SG_ DIS_inletActiveTargetT : 7|7@1+ (1,-40) [-40|80] "DegC"  X
 SG_ DIS_inletPassiveTargetT : 0|7@1+ (1,-40) [-40|80] "DegC"  X

BO_ 2034 BMS_debugInfo_10Hz: 8 VEH
 SG_ BMS_verResourceRequest m29 : 62|2@1+ (1,0) [0|3] ""  X
 SG_ BMS_posIsolationSensorState m2 : 60|1@1+ (1,0) [0|1] ""  dbg
 SG_ BMS_bmsResourceRequest m29 : 60|2@1+ (1,0) [0|3] ""  X
 SG_ BMS_negIsolationSensorState m2 : 59|1@1+ (1,0) [0|1] ""  dbg
 SG_ BMS_hvpResourceRequest m29 : 58|2@1+ (1,0) [0|3] ""  X
 SG_ BMS_positiveRIsoState m2 : 56|3@1+ (1,0) [0|4] ""  X
 SG_ BMS_cpResourceRequest m29 : 56|2@1+ (1,0) [0|3] ""  X
 SG_ BMS_cacUpdateError m18 : 54|9@1+ (0.2,0) [0|102.2] "Ah"  dbg
 SG_ BMS_vehBusResourceRequest m29 : 54|2@1+ (1,0) [0|3] ""  X
 SG_ BMS_refPointCacError2 m17 : 53|9@1+ (0.2,0) [0|102.2] "Ah"  dbg
 SG_ BMS_hvsBusResourceRequest m29 : 52|2@1+ (1,0) [0|3] ""  X
 SG_ BMS_cacUpdateEndPoint m18 : 52|2@1+ (1,0) [0|3] ""  dbg
 SG_ BMS_negativeRIsoState m2 : 51|3@1+ (1,0) [0|4] ""  X
 SG_ BMS_hviBusResourceRequest m29 : 50|2@1+ (1,0) [0|3] ""  X
 SG_ BMS_cacUpdateStartPoint m18 : 50|2@1+ (1,0) [0|3] ""  dbg
 SG_ BMS_isolationMode m2 : 48|3@1+ (1,0) [0|5] ""  X
 SG_ BMS_cacUpdateCounter m18 : 47|3@1+ (1,0) [0|7] ""  dbg
 SG_ BMS_sleepRequest m29 : 47|3@1+ (1,0) [0|6] ""  X
 SG_ BMS_thmMdlOuterDriverTemp5 m6 : 46|10@1+ (0.1,-30) [-30|70] "C"  X
 SG_ BMS_thmMdlOuterPassengerTemp10 m11 : 46|10@1+ (0.1,-30) [-30|70] "C"  X
 SG_ BMS_thmMdlOuterDriverTemp10 m7 : 46|10@1+ (0.1,-30) [-30|70] "C"  X
 SG_ BMS_thmMdlOuterPassengerTemp5 m10 : 46|10@1+ (0.1,-30) [-30|70] "C"  X
 SG_ BMS_thmMdlInnerPassengerTemp10 m9 : 46|10@1+ (0.1,-30) [-30|70] "C"  X
 SG_ BMS_thmMdlInnerDriverTemp5 m4 : 46|10@1+ (0.1,-30) [-30|70] "C"  X
 SG_ BMS_thmMdlDBG5 m12 : 46|10@1+ (0.1,-30) [-30|70] "C"  X
 SG_ BMS_thmMdlInnerDriverTemp10 m5 : 46|10@1+ (0.1,-30) [-30|70] "C"  X
 SG_ BMS_thmMdlInnerPassengerTemp5 m8 : 46|10@1+ (0.1,-30) [-30|70] "C"  X
 SG_ BMS_thmMdlDBG10 m13 : 46|10@1+ (0.1,-30) [-30|70] "C"  X
 SG_ BMS_hystRatioError m16 : 46|10@1+ (0.1,0) [0|100] "%"  dbg
 SG_ BMS_refPointCacError1 m17 : 44|9@1+ (0.2,0) [0|102.2] "Ah"  dbg
 SG_ BMS_sleepState m29 : 44|3@1+ (1,0) [0|6] ""  dbg
 SG_ BMS_verResourceState m29 : 41|3@1+ (1,0) [0|5] ""  X
 SG_ BMS_dbgMaxCurrentDischarge m26 : 40|14@1+ (0.1,0) [0|1638.2] "A"  X
 SG_ BMS_modelTError m14 : 40|8@1+ (0.01,0) [0|2.5] "DegC"  X
 SG_ BMS_dbgResistanceR1 m27 : 40|16@1+ (0.001,0) [0|65] "Ohm"  X
 SG_ BMS_restTime1 m20 : 40|15@1+ (0.1,0) [0|3000] "min"  X
 SG_ BMS_packNegativeV m15 : 40|16@1- (0.02,0) [-655.36|655.34] "V"  X
 SG_ BMS_dbgCpLatchEnableV m24 : 40|16@1+ (0.001,0) [0|65.535] "V"  X
 SG_ BMS_dbgCpFaultInputV m22 : 40|16@1+ (0.001,0) [0|65.535] "V"  dbg
 SG_ BMS_dbg1v5ReferenceHvp m21 : 40|16@1+ (0.001,0) [0|65.535] "V"  X
 SG_ BMS_dbgCapacitanceC2 m28 : 40|16@1+ (0.1,0) [0|6553] "Farad"  X
 SG_ BMS_dbgDcLinkCtrSenseCurrent m23 : 40|16@1+ (0.01,0) [0|655.35] "A"  X
 SG_ BMS_isResting m3 : 39|1@1+ (1,0) [0|1] ""  dbg
 SG_ BMS_bmsResourceState m29 : 38|3@1+ (1,0) [0|5] ""  X
 SG_ BMS_cacInitialPtSocByOcv m18 : 37|10@1+ (0.1,0) [0|100] "%"  dbg
 SG_ BMS_thmMdlOuterPassengerTemp9 m11 : 36|10@1+ (0.1,-30) [-30|70] "C"  X
 SG_ BMS_thmMdlInnerPassengerTemp9 m9 : 36|10@1+ (0.1,-30) [-30|70] "C"  X
 SG_ BMS_thmMdlOuterDriverTemp4 m6 : 36|10@1+ (0.1,-30) [-30|70] "C"  X
 SG_ BMS_thmMdlOuterDriverTemp9 m7 : 36|10@1+ (0.1,-30) [-30|70] "C"  X
 SG_ BMS_thmMdlInnerDriverTemp9 m5 : 36|10@1+ (0.1,-30) [-30|70] "C"  X
 SG_ BMS_thmMdlInnerDriverTemp4 m4 : 36|10@1+ (0.1,-30) [-30|70] "C"  X
 SG_ BMS_thmMdlOuterPassengerTemp4 m10 : 36|10@1+ (0.1,-30) [-30|70] "C"  X
 SG_ BMS_thmMdlInnerPassengerTemp4 m8 : 36|10@1+ (0.1,-30) [-30|70] "C"  X
 SG_ BMS_thmMdlDBG4 m12 : 36|10@1+ (0.1,-30) [-30|70] "C"  X
 SG_ BMS_thmMdlDBG9 m13 : 36|10@1+ (0.1,-30) [-30|70] "C"  X
 SG_ BMS_isoResistanceExtNegative m2 : 36|10@1+ (10,0) [0|10230] "kOhm"  dbg
 SG_ BMS_hystRatio m16 : 36|10@1+ (0.1,0) [0|100] "%"  dbg
 SG_ BMS_pcsResourceState m29 : 35|3@1+ (1,0) [0|5] ""  X
 SG_ BMS_refPointDeltaAhError m17 : 35|9@1- (0.05,0) [-12.8|12.75] "Ah"  dbg
 SG_ BMS_minBrickOcvIndex m3 : 32|7@1+ (1,0) [0|127] ""  X
 SG_ BMS_ahDischarge m1 : 32|24@1+ (0.1,0) [0|1677721.5] "Ah"  dbg
 SG_ BMS_hvpResourceState m29 : 32|3@1+ (1,0) [0|5] ""  X
 SG_ BMS_cpResourceState m29 : 27|3@1+ (1,0) [0|5] ""  X
 SG_ BMS_cacEstimateBrick1 m18 : 27|10@1+ (0.5,75) [75|586.5] "Ah"  dbg
 SG_ BMS_thmMdlDBG8 m13 : 26|10@1+ (0.1,-30) [-30|70] "C"  X
 SG_ BMS_thmMdlInnerDriverTemp8 m5 : 26|10@1+ (0.1,-30) [-30|70] "C"  X
 SG_ BMS_thmMdlOuterPassengerTemp3 m10 : 26|10@1+ (0.1,-30) [-30|70] "C"  X
 SG_ BMS_thmMdlInnerDriverTemp3 m4 : 26|10@1+ (0.1,-30) [-30|70] "C"  X
 SG_ BMS_thmMdlOuterPassengerTemp8 m11 : 26|10@1+ (0.1,-30) [-30|70] "C"  X
 SG_ BMS_isoResistanceExtPositive m2 : 26|10@1+ (10,0) [0|10230] "kOhm"  dbg
 SG_ BMS_thmMdlOuterDriverTemp3 m6 : 26|10@1+ (0.1,-30) [-30|70] "C"  X
 SG_ BMS_thmMdlOuterDriverTemp8 m7 : 26|10@1+ (0.1,-30) [-30|70] "C"  X
 SG_ BMS_thmMdlDBG13 m14 : 26|10@1+ (0.1,-30) [-30|70] "C"  X
 SG_ BMS_thmMdlDBG3 m12 : 26|10@1+ (0.1,-30) [-30|70] "C"  X
 SG_ BMS_socByOcvEst m16 : 26|10@1+ (0.1,0) [0|100] "%"  X
 SG_ BMS_thmMdlInnerPassengerTemp8 m9 : 26|10@1+ (0.1,-30) [-30|70] "C"  X
 SG_ BMS_thmMdlInnerPassengerTemp3 m8 : 26|10@1+ (0.1,-30) [-30|70] "C"  X
 SG_ BMS_vehBusResourceState m29 : 24|3@1+ (1,0) [0|5] ""  X
 SG_ BMS_dbgFloodPortV2 m25 : 24|16@1+ (0.001,0) [0|65.535] "V"  X
 SG_ BMS_dbgDcLinkNegativeV m23 : 24|16@1- (0.02,0) [-655.36|655.34] "V"  X
 SG_ BMS_dbgPolarizationVoltageV2 m27 : 24|16@1- (0.0001,-3) [-3.27|3.27] "V"  X
 SG_ BMS_refPointDeltaAh m17 : 24|11@1- (0.5,0) [-512|511.5] "Ah"  dbg
 SG_ BMS_dbgCpNegativeV m22 : 24|16@1- (0.02,0) [-655.36|655.34] "V"  X
 SG_ BMS_dbgCapacitanceC1 m28 : 24|16@1+ (0.1,0) [0|6553] "Farad"  X
 SG_ BMS_dbgMinLoadedVoltageDischarge m26 : 24|16@1+ (0.0001,0) [0|5] "V"  X
 SG_ BMS_stdCacError m19 : 24|8@1+ (0.2,0) [0|51] "Ah"  dbg
 SG_ BMS_dbgInternalHvilSenseV m24 : 24|16@1+ (0.001,0) [0|65.535] "V"  X
 SG_ BMS_dbg3v0ReferenceHvp m21 : 24|16@1+ (0.001,0) [0|65.535] "V"  X
 SG_ BMS_stopSecondsElapsed m20 : 24|16@1+ (1,0) [0|65535] ""  X
 SG_ BMS_packPositiveV m15 : 24|16@1- (0.02,0) [-655.36|655.34] "V"  X
 SG_ BMS_minBrickOcvMin m3 : 20|12@1+ (0.002,0) [0|5] "V"  X
 SG_ BMS_hvsBusResourceState m29 : 20|3@1+ (1,0) [0|5] ""  X
 SG_ BMS_cacNetAhError m18 : 19|8@1+ (0.1,0) [0|25.5] "Ah"  dbg
 SG_ BMS_dbgPcsIsActiveOnHvs m0 : 17|1@1+ (1,0) [0|1] ""  X
 SG_ BMS_thmMdlDBG7 m13 : 16|10@1+ (0.1,-30) [-30|70] "C"  X
 SG_ BMS_thmMdlInnerDriverTemp2 m4 : 16|10@1+ (0.1,-30) [-30|70] "C"  X
 SG_ BMS_thmMdlInnerPassengerTemp7 m9 : 16|10@1+ (0.1,-30) [-30|70] "C"  X
 SG_ BMS_thmMdlDBG12 m14 : 16|10@1+ (0.1,-30) [-30|70] "C"  X
 SG_ BMS_thmMdlOuterPassengerTemp2 m10 : 16|10@1+ (0.1,-30) [-30|70] "C"  X
 SG_ BMS_socByOcvMin m16 : 16|10@1+ (0.1,0) [0|100] "%"  dbg
 SG_ BMS_dbgPcsReportedOn m0 : 16|1@1+ (1,0) [0|1] ""  X
 SG_ BMS_thmMdlOuterDriverTemp2 m6 : 16|10@1+ (0.1,-30) [-30|70] "C"  X
 SG_ BMS_thmMdlOuterDriverTemp7 m7 : 16|10@1+ (0.1,-30) [-30|70] "C"  X
 SG_ BMS_thmMdlInnerPassengerTemp2 m8 : 16|10@1+ (0.1,-30) [-30|70] "C"  X
 SG_ BMS_isoResistanceIntNegative m2 : 16|10@1+ (10,0) [0|10230] "kOhm"  dbg
 SG_ BMS_thmMdlOuterPassengerTemp7 m11 : 16|10@1+ (0.1,-30) [-30|70] "C"  X
 SG_ BMS_thmMdlDBG2 m12 : 16|10@1+ (0.1,-30) [-30|70] "C"  X
 SG_ BMS_thmMdlInnerDriverTemp7 m5 : 16|10@1+ (0.1,-30) [-30|70] "C"  X
 SG_ BMS_refPointDeltaSoc m17 : 12|10@1+ (0.1,0) [0|100] "%"  dbg
 SG_ BMS_candidate2CacPointValid m17 : 11|1@1+ (1,0) [0|1] ""  dbg
 SG_ BMS_candidate1CacPointValid m17 : 10|1@1+ (1,0) [0|1] ""  dbg
 SG_ BMS_initialCacPointValid m17 : 9|1@1+ (1,0) [0|1] ""  dbg
 SG_ BMS_dbgVerSenseV m24 : 8|16@1+ (0.001,0) [0|65.535] "V"  X
 SG_ BMS_cacNetAhCounter m18 : 8|11@1- (1,0) [-1024|1023] "Ah"  dbg
 SG_ BMS_ahCharge m1 : 8|24@1+ (0.1,0) [0|1677721.5] "Ah"  dbg
 SG_ BMS_stopSoloWakeTransitionCount m29 : 8|12@1+ (1,0) [0|4095] ""  X
 SG_ BMS_sumBrickVoltages m15 : 8|15@1+ (0.02,0) [0|655.34] "V"  X
 SG_ BMS_avgCacError m19 : 8|9@1+ (0.2,0) [0|102.2] "Ah"  dbg
 SG_ BMS_dbgMaxLoadedVoltageDischarge m26 : 8|16@1+ (0.0001,0) [0|5] "V"  X
 SG_ BMS_dbgResistanceR2 m28 : 8|16@1+ (0.001,0) [0|65] "Ohm"  X
 SG_ BMS_dbgPolarizationVoltageV1 m27 : 8|16@1- (0.0001,-3) [-3.27|3.27] "V"  X
 SG_ BMS_minBrickOcvMax m3 : 8|12@1+ (0.002,0) [0|5] "V"  X
 SG_ BMS_dbgDcLinkPositiveV m23 : 8|16@1- (0.02,0) [-655.36|655.34] "V"  X
 SG_ BMS_dbg3v0ReferenceBms m21 : 8|16@1+ (0.001,0) [0|65.535] "V"  X
 SG_ BMS_brickRestingForCac m17 : 8|1@1+ (1,0) [0|1] ""  dbg
 SG_ BMS_dbgFloodPortV1 m25 : 8|16@1+ (0.001,0) [0|65.535] "V"  X
 SG_ BMS_dbgCpPositiveV m22 : 8|16@1- (0.02,0) [-655.36|655.34] "V"  X
 SG_ BMS_cacActivePoint m17 : 6|2@1+ (1,0) [0|3] ""  dbg
 SG_ BMS_thmMdlInnerPassengerTemp6 m9 : 5|10@1+ (0.1,-30) [-30|70] "C"  X
 SG_ BMS_thmMdlOuterPassengerTemp6 m11 : 5|10@1+ (0.1,-30) [-30|70] "C"  X
 SG_ BMS_thmMdlDBG11 m14 : 5|10@1+ (0.1,-30) [-30|70] "C"  X
 SG_ BMS_thmMdlDBG6 m13 : 5|10@1+ (0.1,-30) [-30|70] "C"  X
 SG_ BMS_thmMdlDBG1 m12 : 5|10@1+ (0.1,-30) [-30|70] "C"  X
 SG_ BMS_thmMdlOuterPassengerTemp1 m10 : 5|10@1+ (0.1,-30) [-30|70] "C"  X
 SG_ BMS_socByOcvMax m16 : 5|10@1+ (0.1,0) [0|100] "%"  dbg
 SG_ BMS_thmMdlInnerPassengerTemp1 m8 : 5|10@1+ (0.1,-30) [-30|70] "C"  X
 SG_ BMS_isoResistancelntPositive m2 : 5|10@1+ (10,0) [0|10230] "kOhm"  dbg
 SG_ BMS_thmMdlInnerDriverTemp6 m5 : 5|10@1+ (0.1,-30) [-30|70] "C"  X
 SG_ BMS_hviBusResourceState m29 : 5|3@1+ (1,0) [0|5] ""  X
 SG_ BMS_thmMdlOuterDriverTemp1 m6 : 5|10@1+ (0.1,-30) [-30|70] "C"  X
 SG_ BMS_thmMdlInnerDriverTemp1 m4 : 5|10@1+ (0.1,-30) [-30|70] "C"  X
 SG_ BMS_faultRetryCount m0 : 5|3@1+ (1,0) [0|7] ""  dbg
 SG_ BMS_thmMdlOuterDriverTemp6 m7 : 5|10@1+ (0.1,-30) [-30|70] "C"  X
 SG_ BMS_allBricksRestingForCac m17 : 5|1@1+ (1,0) [0|1] ""  dbg
 SG_ BMS_vshTestNeededTimer m20 : 5|18@1+ (1,0) [0|262143] "sec"  X
 SG_ BMS_10HzDebug_Id M : 0|5@1+ (1,0) [0|29] ""  X

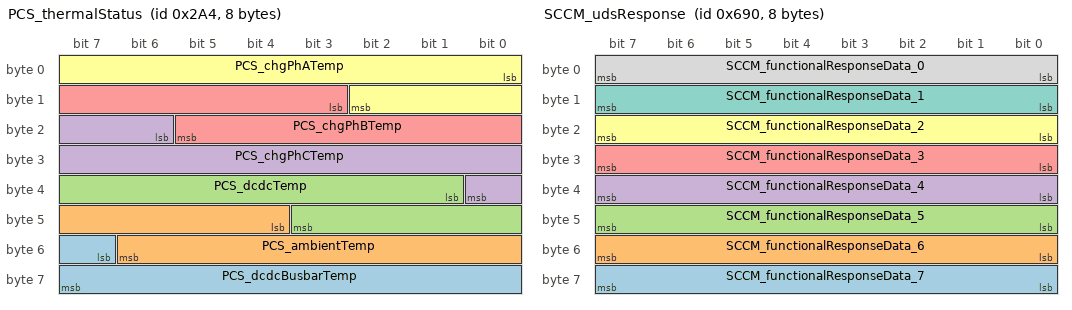
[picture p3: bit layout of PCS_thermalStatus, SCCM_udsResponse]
BO_ 676 PCS_thermalStatus: 8 VEH
 SG_ PCS_dcdcBusbarTemp : 55|9@1+ (0.29354207436399216,0) [0|150] "C"  gtw
 SG_ PCS_ambientTemp : 44|11@1- (0.1,40) [-62.4|142.3] "C"  dbg
 SG_ PCS_dcdcTemp : 33|11@1- (0.1,40) [-62.4|142.3] "C"  dbg
 SG_ PCS_chgPhCTemp : 22|11@1- (0.1,40) [-62.4|142.3] "C"  dbg
 SG_ PCS_chgPhBTemp : 11|11@1- (0.1,40) [-62.4|142.3] "C"  dbg
 SG_ PCS_chgPhATemp : 0|11@1- (0.1,40) [-62.4|142.3] "C"  dbg

BO_ 857 VCSEC_BLEDeviceStatus: 8 VEH
 SG_ VCSEC_BLEDevice1BatteryLevel m1 : 50|13@1+ (1,0) [0|8.192] "mV"  gtw
 SG_ VCSEC_BLEDevice2BatteryLevel m2 : 50|13@1+ (1,0) [0|8.192] "mV"  gtw
 SG_ VCSEC_BLEDevice3BatteryLevel m3 : 50|13@1+ (1,0) [0|8.192] "mV"  gtw
 SG_ VCSEC_BLEDevice0BatteryLevel m0 : 50|13@1+ (1,0) [0|8.192] "mV"  dbg
 SG_ VCSEC_BLEDevice3Temperature m3 : 42|8@1- (1,0) [-127|128] "C"  gtw
 SG_ VCSEC_BLEDevice0Temperature m0 : 42|8@1- (1,0) [-127|128] "C"  gtw
 SG_ VCSEC_BLEDevice1Temperature m1 : 42|8@1- (1,0) [-127|128] "C"  gtw
 SG_ VCSEC_BLEDevice2Temperature m2 : 42|8@1- (1,0) [-127|128] "C"  gtw
 SG_ VCSEC_BLEDevice0WLEntry m0 : 36|5@1+ (1,0) [0|31] ""  gtw
 SG_ VCSEC_BLEDevice3WLEntry m3 : 36|5@1+ (1,0) [0|31] ""  gtw
 SG_ VCSEC_BLEDevice2WLEntry m2 : 36|5@1+ (1,0) [0|31] ""  gtw
 SG_ VCSEC_BLEDevice1WLEntry m1 : 36|5@1+ (1,0) [0|31] ""  gtw
 SG_ VCSEC_BLEDevice3Version m3 : 20|16@1+ (1,0) [0|65535] ""  gtw
 SG_ VCSEC_BLEDevice0Version m0 : 20|16@1+ (1,0) [0|65535] ""  gtw
 SG_ VCSEC_BLEDevice1Version m1 : 20|16@1+ (1,0) [0|65535] ""  gtw
 SG_ VCSEC_BLEDevice2Version m2 : 20|16@1+ (1,0) [0|65535] ""  gtw
 SG_ VCSEC_BLEDevicePacketCounter : 2|16@1+ (1,0) [0|65535] ""  gtw
 SG_ VCSEC_BLEDeviceStatusIndex M : 0|2@1+ (1,0) [0|3] ""  X

BO_ 1680 SCCM_udsResponse: 8 VEH
 SG_ SCCM_functionalResponseData_7 : 63|8@0+ (1,0) [0|255] ""  gtw
 SG_ SCCM_functionalResponseData_6 : 55|8@0+ (1,0) [0|255] ""  gtw
 SG_ SCCM_functionalResponseData_5 : 47|8@0+ (1,0) [0|255] ""  gtw
 SG_ SCCM_functionalResponseData_4 : 39|8@0+ (1,0) [0|255] ""  gtw
 SG_ SCCM_functionalResponseData_3 : 31|8@0+ (1,0) [0|255] ""  gtw
 SG_ SCCM_functionalResponseData_2 : 23|8@0+ (1,0) [0|255] ""  gtw
 SG_ SCCM_functionalResponseData_1 : 15|8@0+ (1,0) [0|255] ""  gtw
 SG_ SCCM_functionalResponseData_0 : 7|8@0+ (1,0) [0|255] ""  gtw

BO_ 1875 XCP_vcrightRequest: 8 VEH
 SG_ XCP_vcrightRequestData : 7|64@0+ (1,0) [0|18446744073709551615] ""  vcright

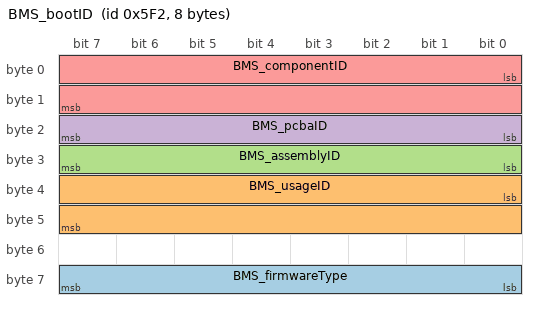
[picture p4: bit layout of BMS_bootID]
BO_ 1522 BMS_bootID: 8 VEH
 SG_ BMS_firmwareType : 56|8@1+ (1,0) [0|255] ""  gtwu
 SG_ BMS_usageID : 32|16@1+ (1,0) [0|65535] ""  gtwu
 SG_ BMS_assemblyID : 24|8@1+ (1,0) [0|255] ""  gtwu
 SG_ BMS_pcbaID : 16|8@1+ (1,0) [0|255] ""  gtwu
 SG_ BMS_componentID : 0|16@1+ (1,0) [0|65535] ""  gtwu

BO_ 1538 UDS_bmsRequest: 8 VEH
 SG_ UDS_bmsRequestData : 7|64@0+ (1,0) [0|18446744073709551615] ""  bms

BO_ 259 VCRIGHT_doorStatus: 8 VEH
 SG_ VCRIGHT_mirrorDipped : 63|1@1+ (1,0) [0|1] ""  X
 SG_ VCRIGHT_mirrorRecallState : 60|3@1+ (1,0) [0|5] ""  gtw
 SG_ VCRIGHT_trunkLatchStatus : 56|4@1+ (1,0) [0|8] ""  di
 SG_ VCRIGHT_mirrorFoldState : 52|3@1+ (1,0) [0|4] ""  gtw
 SG_ VCRIGHT_mirrorState : 49|3@1+ (1,0) [0|4] ""  gtw
 SG_ VCRIGHT_mirrorTiltYPosition : 41|8@1+ (0.02,0) [0|5] "V"  gtw
 SG_ VCRIGHT_mirrorTiltXPosition : 33|8@1+ (0.02,0) [0|5] "V"  gtw
 SG_ VCRIGHT_rearIntSwitchPressed : 32|1@1+ (1,0) [0|1] ""  aps
 SG_ VCRIGHT_frontIntSwitchPressed : 31|1@1+ (1,0) [0|1] ""  aps
 SG_ VCRIGHT_frontHandlePulledPersist : 30|1@1+ (1,0) [0|1] ""  gtw
 SG_ VCRIGHT_reservedForBackCompat : 28|2@1+ (1,0) [0|3] ""  X
 SG_ VCRIGHT_rearHandlePWM : 21|7@1+ (1,0) [0|100] "%"  X
 SG_ VCRIGHT_frontHandlePWM : 14|7@1+ (1,0) [0|100] "%"  X
 SG_ VCRIGHT_rearRelActuatorSwitch : 13|1@1+ (1,0) [0|1] ""  gtw
 SG_ VCRIGHT_frontRelActuatorSwitch : 12|1@1+ (1,0) [0|1] ""  gtw
 SG_ VCRIGHT_rearHandlePulled : 11|1@1+ (1,0) [0|1] ""  aps
 SG_ VCRIGHT_frontHandlePulled : 10|1@1+ (1,0) [0|1] ""  aps
 SG_ VCRIGHT_rearLatchSwitch : 9|1@1+ (1,0) [0|1] ""  gtw
 SG_ VCRIGHT_frontLatchSwitch : 8|1@1+ (1,0) [0|1] ""  gtw
 SG_ VCRIGHT_rearLatchStatus : 4|4@1+ (1,0) [0|8] ""  aps
 SG_ VCRIGHT_frontLatchStatus : 0|4@1+ (1,0) [0|8] ""  aps

BO_ 1322 FC_alertLog: 8 VEH
 SG_ FC_a146_CAflybackTargetV m146 : 48|16@1+ (0.01283327338,0) [0|841.02857] "V"  gtw
 SG_ FC_a159_CAwdtTaskList2 m159 : 32|16@1+ (1,0) [0|65535] ""  gtw
 SG_ FC_a146_CAflybackV m146 : 32|16@1+ (0.01283327338,0) [0|841.02857] "V"  gtw
 SG_ FC_a130_CAflybackSwOvType m130 : 16|1@1+ (1,0) [0|1] ""  gtw
 SG_ FC_a159_CAwdtTaskList1 m159 : 16|16@1+ (1,0) [0|65535] ""  gtw
 SG_ FC_a146_CAflybackOnTime m146 : 16|16@1+ (0.0007629511,0) [0|50] "uS"  gtw
 SG_ FC_alertType : 15|1@1+ (1,0) [0|1] ""  gtw
 SG_ FC_alertID M : 0|15@1+ (1,0) [0|321] ""  gtw

BA_DEF_ SG_  "SystemSignalLongSymbol" STRING ;
BA_DEF_DEF_  "SystemSignalLongSymbol" "";
BA_ "SystemSignalLongSymbol" SG_ 1328 VCSEC_a117_VEH_intrusionSensorSt "VCSEC_a117_VEH_intrusionSensorStatus";
BA_ "SystemSignalLongSymbol" SG_ 1328 VCSEC_a140_cardRmvdB4SndingChaln "VCSEC_a140_cardRmvdB4SndingChalng";
BA_ "SystemSignalLongSymbol" SG_ 1328 VCSEC_a140_cardRmvdB4AuthComplet "VCSEC_a140_cardRmvdB4AuthComplete";
BA_ "SystemSignalLongSymbol" SG_ 1360 VCRIGHT_a166_PINCH_TABLE_REJECTE "VCRIGHT_a166_PINCH_TABLE_REJECTED";
BA_ "SystemSignalLongSymbol" SG_ 1360 VCRIGHT_a165_lowerEndStopPositio "VCRIGHT_a165_lowerEndStopPosition";
BA_ "SystemSignalLongSymbol" SG_ 1360 VCRIGHT_a262_RightCurrentHVSenso "VCRIGHT_a262_RightCurrentHVSensor";
BA_ "SystemSignalLongSymbol" SG_ 1360 VCRIGHT_a262_RightThermalShutIGB "VCRIGHT_a262_RightThermalShutIGBT";
BA_ "SystemSignalLongSymbol" SG_ 1360 VCRIGHT_a117_VEH_intrusionSensor "VCRIGHT_a117_VEH_intrusionSensorStatus";
BA_ "SystemSignalLongSymbol" SG_ 1360 VCRIGHT_a113_VEH_powertrainContr "VCRIGHT_a113_VEH_powertrainControl";
BA_ "SystemSignalLongSymbol" SG_ 1360 VCRIGHT_a271_temperatureSensorSN "VCRIGHT_a271_temperatureSensorSNA";
BA_ "SystemSignalLongSymbol" SG_ 1360 VCRIGHT_a010_UnderVoltageDetecte "VCRIGHT_a010_UnderVoltageDetected";
VAL_ 768 BMS_buildType 1 "INFO_PLATFORM_BUILD" 3 "INFO_TRACEABLE_CI_BUILD" 4 "INFO_MFG_BUILD" 2 "INFO_LOCAL_BUILD" 0 "INFO_UNKNOWN_BUILD" ;
VAL_ 768 BMS_infoIndex 25 "INFO_PACKAGE_PN_1_7" 30 "INFO_PACKAGE_SN_8_14" 27 "INFO_PACKAGE_PN_15_20" 0 "INFO_DEPRECATED_0" 29 "INFO_PACKAGE_SN_1_7" 10 "INFO_BUILD_HWID_COMPONENTID" 14 "INFO_BOOTLOADER_SVN" 31 "INFO_SUBCOMPONENT_GITHASH" 19 "INFO_VERSION_DEPRECATED" 7 "INFO_DEPRECATED_7" 255 "INFO_END" 9 "INFO_DEPRECATED_9" 6 "INFO_DEPRECATED_6" 20 "INFO_UDS_PROTOCOL_BOOTCRC" 3 "INFO_DEPRECATED_3" 22 "INFO_VARIANTCRC" 17 "INFO_APP_GITHASH" 8 "INFO_DEPRECATED_8" 26 "INFO_PACKAGE_PN_8_14" 5 "INFO_DEPRECATED_5" 16 "INFO_SUBCOMPONENT" 13 "INFO_APP_CRC" 2 "INFO_DEPRECATED_2" 4 "INFO_DEPRECATED_4" 15 "INFO_BOOTLOADER_CRC" 1 "INFO_DEPRECATED_1" 11 "INFO_PCBAID_ASSYID_USAGEID" 18 "INFO_BOOTLOADER_GITHASH" ;
VAL_ 1251 VCRIGHT_frontSeatTrackState 1 "SEAT_STATE_MOVING_UP" 2 "SEAT_STATE_MOVING_DOWN" 3 "SEAT_STATE_RECALLING" 0 "SEAT_STATE_STOPPED" 5 "SEAT_STATE_UNDEFINED" 4 "SEAT_STATE_CALIBRATING" ;
VAL_ 1251 VCRIGHT_frontSeatLiftState 1 "SEAT_STATE_MOVING_UP" 2 "SEAT_STATE_MOVING_DOWN" 3 "SEAT_STATE_RECALLING" 0 "SEAT_STATE_STOPPED" 5 "SEAT_STATE_UNDEFINED" 4 "SEAT_STATE_CALIBRATING" ;
VAL_ 1251 VCRIGHT_frontSeatTiltState 1 "SEAT_STATE_MOVING_UP" 2 "SEAT_STATE_MOVING_DOWN" 3 "SEAT_STATE_RECALLING" 0 "SEAT_STATE_STOPPED" 5 "SEAT_STATE_UNDEFINED" 4 "SEAT_STATE_CALIBRATING" ;
VAL_ 1251 VCRIGHT_frontSeatBackState 1 "SEAT_STATE_MOVING_UP" 2 "SEAT_STATE_MOVING_DOWN" 3 "SEAT_STATE_RECALLING" 0 "SEAT_STATE_STOPPED" 5 "SEAT_STATE_UNDEFINED" 4 "SEAT_STATE_CALIBRATING" ;
VAL_ 1251 VCRIGHT_lumbarBState 1 "SEAT_STATE_MOVING_UP" 2 "SEAT_STATE_MOVING_DOWN" 3 "SEAT_STATE_RECALLING" 0 "SEAT_STATE_STOPPED" 5 "SEAT_STATE_UNDEFINED" 4 "SEAT_STATE_CALIBRATING" ;
VAL_ 1251 VCRIGHT_lumbarAState 1 "SEAT_STATE_MOVING_UP" 2 "SEAT_STATE_MOVING_DOWN" 3 "SEAT_STATE_RECALLING" 0 "SEAT_STATE_STOPPED" 5 "SEAT_STATE_UNDEFINED" 4 "SEAT_STATE_CALIBRATING" ;
VAL_ 1251 VCRIGHT_seatStatusIndex 5 "SEAT_STATUS_INDEX_POSITION" 1 "SEAT_STATUS_INDEX_BACK" 3 "SEAT_STATUS_INDEX_TILT" 4 "SEAT_STATUS_INDEX_LUMBAR" 0 "SEAT_STATUS_INDEX_TRACK" 2 "SEAT_STATUS_INDEX_LIFT" ;
VAL_ 1328 VCSEC_a181_fault 2 "VCSEC_SIGNED_MESSAGE_FAULT_LOCAL_ENTITY_RESULT" 5 "VCSEC_SIGNED_MESSAGE_FAULT_ECDSA_INPUT" 8 "VCSEC_SIGNED_MESSAGE_FAULT_INVALID_TOKEN" 9 "VCSEC_SIGNED_MESSAGE_FAULT_IV_SMALLER_THAN_EXPECTED" 0 "VCSEC_SIGNED_MESSAGE_FAULT_NONE" 6 "VCSEC_SIGNED_MESSAGE_FAULT_AES_DECRYPT_AUTH" 7 "VCSEC_SIGNED_MESSAGE_FAULT_TOKEN_AND_COUNTER_INVALID" 10 "VCSEC_SIGNED_MESSAGE_FAULT_NOT_ON_WHITELIST" 3 "VCSEC_SIGNED_MESSAGE_FAULT_LOCAL_ENTITY_START" 4 "VCSEC_SIGNED_MESSAGE_FAULT_ECDSA_SIGNATURE" 1 "VCSEC_SIGNED_MESSAGE_FAULT_UNKNOWN" ;
VAL_ 1328 VCSEC_a134_certificateFault 0 "VCSEC_CERTIFICATEFAULTTYPE_COMMON_NAME_NOT_FOUND" 2 "VCSEC_CERTIFICATEFAULTTYPE_CERTIFICATE_NOT_LOADED" 1 "VCSEC_CERTIFICATEFAULTTYPE_CERTIFICATE_NOT_PARSED" ;
VAL_ 1328 VCSEC_a133_alarmTriggerReason 5 "ALARM_TRIGGER_REASON_REAR_TRUNK" 4 "ALARM_TRIGGER_REASON_FRONT_TRUNK" 3 "ALARM_TRIGGER_REASON_REAR_PASSENGER_DOOR" 8 "ALARM_TRIGGER_REASON_NOT_TRIGGERED" 7 "ALARM_TRIGGER_REASON_TILT_SENSOR" 2 "ALARM_TRIGGER_REASON_REAR_DRIVER_DOOR" 1 "ALARM_TRIGGER_REASON_FRONT_PASSENGER_DOOR" 6 "ALARM_TRIGGER_REASON_ULTRASONIC" 0 "ALARM_TRIGGER_REASON_FRONT_DRIVER_DOOR" ;
VAL_ 1328 VCSEC_a174_resetSource 9 "BLEENDPOINT_RESET_SOURCE_WARM_RESET_EMULATED_PIN_RESET" 0 "BLEENDPOINT_RESET_SOURCE_POWER_ON_RESET" 5 "BLEENDPOINT_RESET_SOURCE_CLOCK_LOSS_DETECTED" 1 "BLEENDPOINT_RESET_SOURCE_RESET_PIN" 4 "BLEENDPOINT_RESET_SOURCE_BROWNOUT_ON_VDDR" 2 "BLEENDPOINT_RESET_SOURCE_BROWNOUT_ON_VDDS" 10 "BLEENDPOINT_RESET_SOURCE_WARM_RESET_UNKNOWN" 7 "BLEENDPOINT_RESET_SOURCE_WARM_RESET_WATCHDOG_RESET" 8 "BLEENDPOINT_RESET_SOURCE_WARM_RESET_CPU_LOCKUP" 3 "BLEENDPOINT_RESET_SOURCE_BROWNOUT_ON_VDD" 6 "BLEENDPOINT_RESET_SOURCE_SW_RESET_VIA_SYSRESET" ;
VAL_ 1328 VCSEC_a172_resetSource 9 "BLEENDPOINT_RESET_SOURCE_WARM_RESET_EMULATED_PIN_RESET" 0 "BLEENDPOINT_RESET_SOURCE_POWER_ON_RESET" 5 "BLEENDPOINT_RESET_SOURCE_CLOCK_LOSS_DETECTED" 1 "BLEENDPOINT_RESET_SOURCE_RESET_PIN" 4 "BLEENDPOINT_RESET_SOURCE_BROWNOUT_ON_VDDR" 2 "BLEENDPOINT_RESET_SOURCE_BROWNOUT_ON_VDDS" 10 "BLEENDPOINT_RESET_SOURCE_WARM_RESET_UNKNOWN" 7 "BLEENDPOINT_RESET_SOURCE_WARM_RESET_WATCHDOG_RESET" 8 "BLEENDPOINT_RESET_SOURCE_WARM_RESET_CPU_LOCKUP" 3 "BLEENDPOINT_RESET_SOURCE_BROWNOUT_ON_VDD" 6 "BLEENDPOINT_RESET_SOURCE_SW_RESET_VIA_SYSRESET" ;
VAL_ 1328 VCSEC_a175_resetSource 9 "BLEENDPOINT_RESET_SOURCE_WARM_RESET_EMULATED_PIN_RESET" 0 "BLEENDPOINT_RESET_SOURCE_POWER_ON_RESET" 5 "BLEENDPOINT_RESET_SOURCE_CLOCK_LOSS_DETECTED" 1 "BLEENDPOINT_RESET_SOURCE_RESET_PIN" 4 "BLEENDPOINT_RESET_SOURCE_BROWNOUT_ON_VDDR" 2 "BLEENDPOINT_RESET_SOURCE_BROWNOUT_ON_VDDS" 10 "BLEENDPOINT_RESET_SOURCE_WARM_RESET_UNKNOWN" 7 "BLEENDPOINT_RESET_SOURCE_WARM_RESET_WATCHDOG_RESET" 8 "BLEENDPOINT_RESET_SOURCE_WARM_RESET_CPU_LOCKUP" 3 "BLEENDPOINT_RESET_SOURCE_BROWNOUT_ON_VDD" 6 "BLEENDPOINT_RESET_SOURCE_SW_RESET_VIA_SYSRESET" ;
VAL_ 1328 VCSEC_a173_resetSource 9 "BLEENDPOINT_RESET_SOURCE_WARM_RESET_EMULATED_PIN_RESET" 0 "BLEENDPOINT_RESET_SOURCE_POWER_ON_RESET" 5 "BLEENDPOINT_RESET_SOURCE_CLOCK_LOSS_DETECTED" 1 "BLEENDPOINT_RESET_SOURCE_RESET_PIN" 4 "BLEENDPOINT_RESET_SOURCE_BROWNOUT_ON_VDDR" 2 "BLEENDPOINT_RESET_SOURCE_BROWNOUT_ON_VDDS" 10 "BLEENDPOINT_RESET_SOURCE_WARM_RESET_UNKNOWN" 7 "BLEENDPOINT_RESET_SOURCE_WARM_RESET_WATCHDOG_RESET" 8 "BLEENDPOINT_RESET_SOURCE_WARM_RESET_CPU_LOCKUP" 3 "BLEENDPOINT_RESET_SOURCE_BROWNOUT_ON_VDD" 6 "BLEENDPOINT_RESET_SOURCE_SW_RESET_VIA_SYSRESET" ;
VAL_ 1328 VCSEC_alertType 0 "ALERT_CLEARED" 1 "ALERT_SET" ;
VAL_ 1328 VCSEC_alertID 165 "VCSEC_a165_ephemeralKeyGenerated" 182 "VCSEC_a182_cryptoHighStackUsage" 63 "VCSEC_a063_SwitchFault" 43 "VCSEC_a043_Task1msError" 3 "VCSEC_a003_SWAssertion" 109 "VCSEC_a109_RCM_MIA" 191 "VCSEC_a191_macIDWlistingFailedC" 110 "VCSEC_a110_GTW_MIA" 118 "VCSEC_a118_VCFRONT_MIA" 206 "VCSEC_a206_BLELeftAssertFailure" 61 "VCSEC_a061_XCPConnected" 103 "VCSEC_a103_CP_MIA" 201 "VCSEC_a201_leftEndpointLostComm" 202 "VCSEC_a202_rightEndpointLostComm" 167 "VCSEC_a167_BLECenterSoftReset" 112 "VCSEC_a112_EPBL_MIA" 117 "VCSEC_a117_VCLEFT_MIA" 45 "VCSEC_a045_Task100msError" 183 "VCSEC_a183_centerEndpointRFMia" 198 "VCSEC_a198_BPillarNFCReaderMIA" 2 "VCSEC_a002_PowerLossReset" 42 "VCSEC_a042_HighStackUsage" 41 "VCSEC_a041_HighCPULoad" 193 "VCSEC_a193_macIDWlistingFailedRi" 168 "VCSEC_a168_BLELeftSoftReset" 147 "VCSEC_a147_protobufRXTimeout" 64 "VCSEC_a064_busSleepReqTimeout" 141 "VCSEC_a141_tooFewKeysOnWhitelist" 172 "VCSEC_a172_BLEUnexpectedResetC" 207 "VCSEC_a207_BLERightAssertFailure" 145 "VCSEC_a145_bleGattAlertRe" 161 "VCSEC_a161_hciFaultR" 31 "VCSEC_a031_UDSActive" 143 "VCSEC_a143_bleGattAlertL" 104 "VCSEC_a104_DAS_MIA" 209 "VCSEC_a209_BLECenterAssertFailure" 116 "VCSEC_a116_VCRIGHT_MIA" 154 "VCSEC_a154_srvcCmdTimeoutL" 60 "VCSEC_a060_engineeringBuild" 159 "VCSEC_a159_hciFaultL" 186 "VCSEC_a186_rearEndpointRFMia" 184 "VCSEC_a184_driverEndpointRFMia" 199 "VCSEC_a199_CenterNFCReaderMIA" 97 "VCSEC_a097_CMP_MIA" 98 "VCSEC_a098_DI_THERMAL_MIA" 150 "VCSEC_a150_attrsWentMissingR" 162 "VCSEC_a162_hciFaultRe" 44 "VCSEC_a044_Task10msError" 170 "VCSEC_a170_BLERearSoftReset" 135 "VCSEC_a135_centerEndpointMIA" 101 "VCSEC_a101_PM_MIA" 120 "VCSEC_a120_DI_DRIVE_MIA" 59 "VCSEC_a059_inputResistanceHigh" 187 "VCSEC_a187_badConnectionDropped" 158 "VCSEC_a158_hciFaultC" 142 "VCSEC_a142_bleGattAlertC" 105 "VCSEC_a105_TAS_MIA" 210 "VCSEC_a210_keyDeviceBatteryLow" 62 "VCSEC_a062_XCPWasConnected" 180 "VCSEC_a180_wlistRemovedPermission" 119 "VCSEC_a119_SCCM_MIA" 113 "VCSEC_a113_UI_MIA" 195 "VCSEC_a195_keyMissingInDrive" 204 "VCSEC_a204_SharedSecretsWritten" 106 "VCSEC_a106_PCS_MIA" 13 "VCSEC_a013_AlertManagerFault" 108 "VCSEC_a108_DIS_MIA" 178 "VCSEC_a178_whitelistRemovedKey" 30 "VCSEC_a030_ECULogUploadRequest" 155 "VCSEC_a155_srvcCmdTimeoutR" 111 "VCSEC_a111_EPBR_MIA" 203 "VCSEC_a203_rearEndpointLostComm" 140 "VCSEC_a140_nfcAuthentication" 196 "VCSEC_a196_protobufTXTimeout" 189 "VCSEC_a189_protoExpLengthTooLarge" 151 "VCSEC_a151_attrsWentMissingRe" 102 "VCSEC_a102_PTC_MIA" 169 "VCSEC_a169_BLERightSoftReset" 137 "VCSEC_a137_rightEndpointMIA" 181 "VCSEC_a181_signedMessageFault" 177 "VCSEC_a177_whitelistAddedKey" 133 "VCSEC_a133_alarmTriggered" 100 "VCSEC_a100_CANbus_MIA" 205 "VCSEC_a205_MTUUpdateNotConfirmed" 134 "VCSEC_a134_badCertificate" 148 "VCSEC_a148_keyWhitelistFull" 149 "VCSEC_a149_attrsWentMissingL" 164 "VCSEC_a164_attrsWentMissingC" 185 "VCSEC_a185_passengerEndpointRFMia" 136 "VCSEC_a136_leftEndpointMIA" 179 "VCSEC_a179_wlistAddedPermission" 1 "VCSEC_a001_WatchdogReset" 197 "VCSEC_a197_indicationFault" 153 "VCSEC_a153_srvcCmdTimeoutC" 21 "VCSEC_a021_TaskSchedulerError" 173 "VCSEC_a173_BLEUnexpectedResetL" 188 "VCSEC_a188_protobufDecodeError" 200 "VCSEC_a200_centerEndpointLostComm" 192 "VCSEC_a192_macIDWlistingFailedL" 99 "VCSEC_a099_PARK_MIA" 174 "VCSEC_a174_BLEUnexpectedResetRi" 166 "VCSEC_a166_BLECenterPowerCycled" 15 "VCSEC_a015_NVMMAlert" 10 "VCSEC_a010_ExtSupplyVoltError" 115 "VCSEC_a115_VCSEC_MIA" 22 "VCSEC_a022_TaskInitError" 194 "VCSEC_a194_macIDWlistingFailedRe" 208 "VCSEC_a208_BLERearAssertFailure" 0 "VCSEC_ALERT_DO_NOT_USE_ZERO" 175 "VCSEC_a175_BLEUnexpectedResetRe" 114 "VCSEC_a114_ESP_MIA" 190 "VCSEC_a190_protoTooManyBytes" 156 "VCSEC_a156_srvcCmdTimeoutRe" 46 "VCSEC_a046_Task1000msError" 107 "VCSEC_a107_BMS_MIA" 144 "VCSEC_a144_bleGattAlertR" 138 "VCSEC_a138_rearEndpointMIA" 12 "VCSEC_a012_CPUReset" ;
VAL_ 306 BMS_chgTimeToFull 4095 "SNA" ;
VAL_ 306 BMS_currentUnfiltered -16384 "SNA" ;
VAL_ 306 BMS_packCurrent -16384 "SNA" ;
VAL_ 586 HVP_cpFaultLine 0 "FAULT_LINE_CLEARED" 1 "FAULT_LINE_SET" ;
VAL_ 505 VCSEC_chargePortRequest 1 "REQUEST_OPEN" 2 "REQUEST_CLOSE" 0 "REQUEST_NONE" 3 "REQUEST_SNA" ;
VAL_ 984 UI_elevation 65535 "SNA" ;
VAL_ 723 UI_solarElevationAngle 127 "SNA" ;
VAL_ 723 UI_isSunUp 3 "SUN_SNA" 1 "SUN_UP" 0 "SUN_DOWN" ;
VAL_ 723 UI_solarAzimuthAngleCarRef 255 "SNA" ;
VAL_ 723 UI_solarAzimuthAngle -32768 "SNA" ;
VAL_ 2004 PMS_debugSelector 105 "Mux105" 14 "Mux16" 103 "Mux103" 20 "Mux20" 104 "Mux104" 11 "Mux11" 21 "Mux21" 102 "Mux102" 10 "Mux10" 13 "Mux13" 22 "Mux22" 15 "Mux19" 101 "Mux101" 12 "Mux12" 23 "Mux23" 100 "Mux100" ;
VAL_ 1360 VCRIGHT_a266_seatMotorState 1 "SEAT_STATE_MOVING_UP" 2 "SEAT_STATE_MOVING_DOWN" 3 "SEAT_STATE_RECALLING" 0 "SEAT_STATE_STOPPED" 5 "SEAT_STATE_UNDEFINED" 4 "SEAT_STATE_CALIBRATING" ;
VAL_ 1360 VCRIGHT_a238_lumbarBState 1 "SEAT_STATE_MOVING_UP" 2 "SEAT_STATE_MOVING_DOWN" 3 "SEAT_STATE_RECALLING" 0 "SEAT_STATE_STOPPED" 5 "SEAT_STATE_UNDEFINED" 4 "SEAT_STATE_CALIBRATING" ;
VAL_ 1360 VCRIGHT_a265_seatMotorState 1 "SEAT_STATE_MOVING_UP" 2 "SEAT_STATE_MOVING_DOWN" 3 "SEAT_STATE_RECALLING" 0 "SEAT_STATE_STOPPED" 5 "SEAT_STATE_UNDEFINED" 4 "SEAT_STATE_CALIBRATING" ;
VAL_ 1360 VCRIGHT_a237_lumbarBState 1 "SEAT_STATE_MOVING_UP" 2 "SEAT_STATE_MOVING_DOWN" 3 "SEAT_STATE_RECALLING" 0 "SEAT_STATE_STOPPED" 5 "SEAT_STATE_UNDEFINED" 4 "SEAT_STATE_CALIBRATING" ;
VAL_ 1360 VCRIGHT_a263_seatMotorState 1 "SEAT_STATE_MOVING_UP" 2 "SEAT_STATE_MOVING_DOWN" 3 "SEAT_STATE_RECALLING" 0 "SEAT_STATE_STOPPED" 5 "SEAT_STATE_UNDEFINED" 4 "SEAT_STATE_CALIBRATING" ;
VAL_ 1360 VCRIGHT_a269_seatMotorState 1 "SEAT_STATE_MOVING_UP" 2 "SEAT_STATE_MOVING_DOWN" 3 "SEAT_STATE_RECALLING" 0 "SEAT_STATE_STOPPED" 5 "SEAT_STATE_UNDEFINED" 4 "SEAT_STATE_CALIBRATING" ;
VAL_ 1360 VCRIGHT_a270_seatMotorState 1 "SEAT_STATE_MOVING_UP" 2 "SEAT_STATE_MOVING_DOWN" 3 "SEAT_STATE_RECALLING" 0 "SEAT_STATE_STOPPED" 5 "SEAT_STATE_UNDEFINED" 4 "SEAT_STATE_CALIBRATING" ;
VAL_ 1360 VCRIGHT_a236_lumbarBState 1 "SEAT_STATE_MOVING_UP" 2 "SEAT_STATE_MOVING_DOWN" 3 "SEAT_STATE_RECALLING" 0 "SEAT_STATE_STOPPED" 5 "SEAT_STATE_UNDEFINED" 4 "SEAT_STATE_CALIBRATING" ;
VAL_ 1360 VCRIGHT_a264_seatMotorState 1 "SEAT_STATE_MOVING_UP" 2 "SEAT_STATE_MOVING_DOWN" 3 "SEAT_STATE_RECALLING" 0 "SEAT_STATE_STOPPED" 5 "SEAT_STATE_UNDEFINED" 4 "SEAT_STATE_CALIBRATING" ;
VAL_ 1360 VCRIGHT_a267_seatMotorState 1 "SEAT_STATE_MOVING_UP" 2 "SEAT_STATE_MOVING_DOWN" 3 "SEAT_STATE_RECALLING" 0 "SEAT_STATE_STOPPED" 5 "SEAT_STATE_UNDEFINED" 4 "SEAT_STATE_CALIBRATING" ;
VAL_ 1360 VCRIGHT_a268_seatMotorState 1 "SEAT_STATE_MOVING_UP" 2 "SEAT_STATE_MOVING_DOWN" 3 "SEAT_STATE_RECALLING" 0 "SEAT_STATE_STOPPED" 5 "SEAT_STATE_UNDEFINED" 4 "SEAT_STATE_CALIBRATING" ;
VAL_ 1360 VCRIGHT_a220_seatSwitchForward 2 "SWITCH_ON" 0 "SWITCH_SNA" 3 "SWITCH_FAULT" 1 "SWITCH_OFF" ;
VAL_ 1360 VCRIGHT_a223_seatSwitchForward 2 "SWITCH_ON" 0 "SWITCH_SNA" 3 "SWITCH_FAULT" 1 "SWITCH_OFF" ;
VAL_ 1360 VCRIGHT_a230_seatSwitchForward 2 "SWITCH_ON" 0 "SWITCH_SNA" 3 "SWITCH_FAULT" 1 "SWITCH_OFF" ;
VAL_ 1360 VCRIGHT_a229_seatSwitchForward 2 "SWITCH_ON" 0 "SWITCH_SNA" 3 "SWITCH_FAULT" 1 "SWITCH_OFF" ;
VAL_ 1360 VCRIGHT_a222_seatSwitchForward 2 "SWITCH_ON" 0 "SWITCH_SNA" 3 "SWITCH_FAULT" 1 "SWITCH_OFF" ;
VAL_ 1360 VCRIGHT_a231_seatSwitchForward 2 "SWITCH_ON" 0 "SWITCH_SNA" 3 "SWITCH_FAULT" 1 "SWITCH_OFF" ;
VAL_ 1360 VCRIGHT_a228_seatSwitchForward 2 "SWITCH_ON" 0 "SWITCH_SNA" 3 "SWITCH_FAULT" 1 "SWITCH_OFF" ;
VAL_ 1360 VCRIGHT_a221_seatSwitchForward 2 "SWITCH_ON" 0 "SWITCH_SNA" 3 "SWITCH_FAULT" 1 "SWITCH_OFF" ;
VAL_ 1360 VCRIGHT_a237_lumbarAState 1 "SEAT_STATE_MOVING_UP" 2 "SEAT_STATE_MOVING_DOWN" 3 "SEAT_STATE_RECALLING" 0 "SEAT_STATE_STOPPED" 5 "SEAT_STATE_UNDEFINED" 4 "SEAT_STATE_CALIBRATING" ;
VAL_ 1360 VCRIGHT_a238_lumbarAState 1 "SEAT_STATE_MOVING_UP" 2 "SEAT_STATE_MOVING_DOWN" 3 "SEAT_STATE_RECALLING" 0 "SEAT_STATE_STOPPED" 5 "SEAT_STATE_UNDEFINED" 4 "SEAT_STATE_CALIBRATING" ;
VAL_ 1360 VCRIGHT_a236_lumbarAState 1 "SEAT_STATE_MOVING_UP" 2 "SEAT_STATE_MOVING_DOWN" 3 "SEAT_STATE_RECALLING" 0 "SEAT_STATE_STOPPED" 5 "SEAT_STATE_UNDEFINED" 4 "SEAT_STATE_CALIBRATING" ;
VAL_ 1360 VCRIGHT_a220_seatSwitchBack 2 "SWITCH_ON" 0 "SWITCH_SNA" 3 "SWITCH_FAULT" 1 "SWITCH_OFF" ;
VAL_ 1360 VCRIGHT_a221_seatSwitchBack 2 "SWITCH_ON" 0 "SWITCH_SNA" 3 "SWITCH_FAULT" 1 "SWITCH_OFF" ;
VAL_ 1360 VCRIGHT_a222_seatSwitchBack 2 "SWITCH_ON" 0 "SWITCH_SNA" 3 "SWITCH_FAULT" 1 "SWITCH_OFF" ;
VAL_ 1360 VCRIGHT_a231_seatSwitchBack 2 "SWITCH_ON" 0 "SWITCH_SNA" 3 "SWITCH_FAULT" 1 "SWITCH_OFF" ;
VAL_ 1360 VCRIGHT_a228_seatSwitchBack 2 "SWITCH_ON" 0 "SWITCH_SNA" 3 "SWITCH_FAULT" 1 "SWITCH_OFF" ;
VAL_ 1360 VCRIGHT_a180_latchStatus 8 "LATCH_FAULT" 2 "LATCH_CLOSED" 1 "LATCH_OPENED" 3 "LATCH_CLOSING" 7 "LATCH_DEFAULT" 4 "LATCH_OPENING" 5 "LATCH_AJAR" 6 "LATCH_TIMEOUT" 0 "LATCH_SNA" ;
VAL_ 1360 VCRIGHT_a223_seatSwitchBack 2 "SWITCH_ON" 0 "SWITCH_SNA" 3 "SWITCH_FAULT" 1 "SWITCH_OFF" ;
VAL_ 1360 VCRIGHT_a181_latchStatus 8 "LATCH_FAULT" 2 "LATCH_CLOSED" 1 "LATCH_OPENED" 3 "LATCH_CLOSING" 7 "LATCH_DEFAULT" 4 "LATCH_OPENING" 5 "LATCH_AJAR" 6 "LATCH_TIMEOUT" 0 "LATCH_SNA" ;
VAL_ 1360 VCRIGHT_a229_seatSwitchBack 2 "SWITCH_ON" 0 "SWITCH_SNA" 3 "SWITCH_FAULT" 1 "SWITCH_OFF" ;
VAL_ 1360 VCRIGHT_a230_seatSwitchBack 2 "SWITCH_ON" 0 "SWITCH_SNA" 3 "SWITCH_FAULT" 1 "SWITCH_OFF" ;
VAL_ 1360 VCRIGHT_a251_seatSwitchForward 2 "SWITCH_ON" 0 "SWITCH_SNA" 3 "SWITCH_FAULT" 1 "SWITCH_OFF" ;
VAL_ 1360 VCRIGHT_a234_seatSwitchForward 2 "SWITCH_ON" 0 "SWITCH_SNA" 3 "SWITCH_FAULT" 1 "SWITCH_OFF" ;
VAL_ 1360 VCRIGHT_a252_seatSwitchForward 2 "SWITCH_ON" 0 "SWITCH_SNA" 3 "SWITCH_FAULT" 1 "SWITCH_OFF" ;
VAL_ 1360 VCRIGHT_a232_seatSwitchForward 2 "SWITCH_ON" 0 "SWITCH_SNA" 3 "SWITCH_FAULT" 1 "SWITCH_OFF" ;
VAL_ 1360 VCRIGHT_a254_seatSwitchForward 2 "SWITCH_ON" 0 "SWITCH_SNA" 3 "SWITCH_FAULT" 1 "SWITCH_OFF" ;
VAL_ 1360 VCRIGHT_a235_seatSwitchForward 2 "SWITCH_ON" 0 "SWITCH_SNA" 3 "SWITCH_FAULT" 1 "SWITCH_OFF" ;
VAL_ 1360 VCRIGHT_a253_seatSwitchForward 2 "SWITCH_ON" 0 "SWITCH_SNA" 3 "SWITCH_FAULT" 1 "SWITCH_OFF" ;
VAL_ 1360 VCRIGHT_a233_seatSwitchForward 2 "SWITCH_ON" 0 "SWITCH_SNA" 3 "SWITCH_FAULT" 1 "SWITCH_OFF" ;
VAL_ 1360 VCRIGHT_a222_seatMotorState 1 "SEAT_STATE_MOVING_UP" 2 "SEAT_STATE_MOVING_DOWN" 3 "SEAT_STATE_RECALLING" 0 "SEAT_STATE_STOPPED" 5 "SEAT_STATE_UNDEFINED" 4 "SEAT_STATE_CALIBRATING" ;
VAL_ 1360 VCRIGHT_a231_seatMotorState 1 "SEAT_STATE_MOVING_UP" 2 "SEAT_STATE_MOVING_DOWN" 3 "SEAT_STATE_RECALLING" 0 "SEAT_STATE_STOPPED" 5 "SEAT_STATE_UNDEFINED" 4 "SEAT_STATE_CALIBRATING" ;
VAL_ 1360 VCRIGHT_a228_seatMotorState 1 "SEAT_STATE_MOVING_UP" 2 "SEAT_STATE_MOVING_DOWN" 3 "SEAT_STATE_RECALLING" 0 "SEAT_STATE_STOPPED" 5 "SEAT_STATE_UNDEFINED" 4 "SEAT_STATE_CALIBRATING" ;
VAL_ 1360 VCRIGHT_a221_seatMotorState 1 "SEAT_STATE_MOVING_UP" 2 "SEAT_STATE_MOVING_DOWN" 3 "SEAT_STATE_RECALLING" 0 "SEAT_STATE_STOPPED" 5 "SEAT_STATE_UNDEFINED" 4 "SEAT_STATE_CALIBRATING" ;
VAL_ 1360 VCRIGHT_a220_seatMotorState 1 "SEAT_STATE_MOVING_UP" 2 "SEAT_STATE_MOVING_DOWN" 3 "SEAT_STATE_RECALLING" 0 "SEAT_STATE_STOPPED" 5 "SEAT_STATE_UNDEFINED" 4 "SEAT_STATE_CALIBRATING" ;
VAL_ 1360 VCRIGHT_a223_seatMotorState 1 "SEAT_STATE_MOVING_UP" 2 "SEAT_STATE_MOVING_DOWN" 3 "SEAT_STATE_RECALLING" 0 "SEAT_STATE_STOPPED" 5 "SEAT_STATE_UNDEFINED" 4 "SEAT_STATE_CALIBRATING" ;
VAL_ 1360 VCRIGHT_a229_seatMotorState 1 "SEAT_STATE_MOVING_UP" 2 "SEAT_STATE_MOVING_DOWN" 3 "SEAT_STATE_RECALLING" 0 "SEAT_STATE_STOPPED" 5 "SEAT_STATE_UNDEFINED" 4 "SEAT_STATE_CALIBRATING" ;
VAL_ 1360 VCRIGHT_a230_seatMotorState 1 "SEAT_STATE_MOVING_UP" 2 "SEAT_STATE_MOVING_DOWN" 3 "SEAT_STATE_RECALLING" 0 "SEAT_STATE_STOPPED" 5 "SEAT_STATE_UNDEFINED" 4 "SEAT_STATE_CALIBRATING" ;
VAL_ 1360 VCRIGHT_a252_seatSwitchBack 2 "SWITCH_ON" 0 "SWITCH_SNA" 3 "SWITCH_FAULT" 1 "SWITCH_OFF" ;
VAL_ 1360 VCRIGHT_a234_seatSwitchBack 2 "SWITCH_ON" 0 "SWITCH_SNA" 3 "SWITCH_FAULT" 1 "SWITCH_OFF" ;
VAL_ 1360 VCRIGHT_a251_seatSwitchBack 2 "SWITCH_ON" 0 "SWITCH_SNA" 3 "SWITCH_FAULT" 1 "SWITCH_OFF" ;
VAL_ 1360 VCRIGHT_a254_seatSwitchBack 2 "SWITCH_ON" 0 "SWITCH_SNA" 3 "SWITCH_FAULT" 1 "SWITCH_OFF" ;
VAL_ 1360 VCRIGHT_a232_seatSwitchBack 2 "SWITCH_ON" 0 "SWITCH_SNA" 3 "SWITCH_FAULT" 1 "SWITCH_OFF" ;
VAL_ 1360 VCRIGHT_a253_seatSwitchBack 2 "SWITCH_ON" 0 "SWITCH_SNA" 3 "SWITCH_FAULT" 1 "SWITCH_OFF" ;
VAL_ 1360 VCRIGHT_a235_seatSwitchBack 2 "SWITCH_ON" 0 "SWITCH_SNA" 3 "SWITCH_FAULT" 1 "SWITCH_OFF" ;
VAL_ 1360 VCRIGHT_a233_seatSwitchBack 2 "SWITCH_ON" 0 "SWITCH_SNA" 3 "SWITCH_FAULT" 1 "SWITCH_OFF" ;
VAL_ 1360 VCRIGHT_a207_unitStatusEPBM 14 "EPB_STATUS_SUMMON" 1 "EPB_STATUS_OPEN" 9 "EPB_STATUS_DYNAMIC_APPLYING" 21 "EPB_STATUS_COUNT" 12 "EPB_STATUS_PARK_PENDING" 13 "EPB_STATUS_WINCHMODE_PENDING" 6 "EPB_STATUS_WINCHMODE" 3 "EPB_STATUS_PARK" 0 "EPB_STATUS_UNKNOWN" 4 "EPB_STATUS_START" 18 "EPB_STATUS_RELEASING_FOR_EXTERNAL_PARK" 19 "EPB_STATUS_EXTERNAL_PARKING" 17 "EPB_STATUS_EXTERNAL_DYNAMIC" 10 "EPB_STATUS_RELEASING" 15 "EPB_STATUS_SUMMON_RELEASING" 11 "EPB_STATUS_SERVICE_RELEASING" 7 "EPB_STATUS_WINCHMODE_RELEASING" 16 "EPB_STATUS_SUMMON_PARKING" 8 "EPB_STATUS_PARKING" 2 "EPB_STATUS_DYNAMIC" 5 "EPB_STATUS_SERVICE" 20 "EPB_STATUS_DYNAMIC_PARKING" ;
VAL_ 1360 VCRIGHT_a254_seatMotorState 1 "SEAT_STATE_MOVING_UP" 2 "SEAT_STATE_MOVING_DOWN" 3 "SEAT_STATE_RECALLING" 0 "SEAT_STATE_STOPPED" 5 "SEAT_STATE_UNDEFINED" 4 "SEAT_STATE_CALIBRATING" ;
VAL_ 1360 VCRIGHT_a232_seatMotorState 1 "SEAT_STATE_MOVING_UP" 2 "SEAT_STATE_MOVING_DOWN" 3 "SEAT_STATE_RECALLING" 0 "SEAT_STATE_STOPPED" 5 "SEAT_STATE_UNDEFINED" 4 "SEAT_STATE_CALIBRATING" ;
VAL_ 1360 VCRIGHT_a251_seatMotorState 1 "SEAT_STATE_MOVING_UP" 2 "SEAT_STATE_MOVING_DOWN" 3 "SEAT_STATE_RECALLING" 0 "SEAT_STATE_STOPPED" 5 "SEAT_STATE_UNDEFINED" 4 "SEAT_STATE_CALIBRATING" ;
VAL_ 1360 VCRIGHT_a233_seatMotorState 1 "SEAT_STATE_MOVING_UP" 2 "SEAT_STATE_MOVING_DOWN" 3 "SEAT_STATE_RECALLING" 0 "SEAT_STATE_STOPPED" 5 "SEAT_STATE_UNDEFINED" 4 "SEAT_STATE_CALIBRATING" ;
VAL_ 1360 VCRIGHT_a208_unitStatusEPBM 14 "EPB_STATUS_SUMMON" 1 "EPB_STATUS_OPEN" 9 "EPB_STATUS_DYNAMIC_APPLYING" 21 "EPB_STATUS_COUNT" 12 "EPB_STATUS_PARK_PENDING" 13 "EPB_STATUS_WINCHMODE_PENDING" 6 "EPB_STATUS_WINCHMODE" 3 "EPB_STATUS_PARK" 0 "EPB_STATUS_UNKNOWN" 4 "EPB_STATUS_START" 18 "EPB_STATUS_RELEASING_FOR_EXTERNAL_PARK" 19 "EPB_STATUS_EXTERNAL_PARKING" 17 "EPB_STATUS_EXTERNAL_DYNAMIC" 10 "EPB_STATUS_RELEASING" 15 "EPB_STATUS_SUMMON_RELEASING" 11 "EPB_STATUS_SERVICE_RELEASING" 7 "EPB_STATUS_WINCHMODE_RELEASING" 16 "EPB_STATUS_SUMMON_PARKING" 8 "EPB_STATUS_PARKING" 2 "EPB_STATUS_DYNAMIC" 5 "EPB_STATUS_SERVICE" 20 "EPB_STATUS_DYNAMIC_PARKING" ;
VAL_ 1360 VCRIGHT_a234_seatMotorState 1 "SEAT_STATE_MOVING_UP" 2 "SEAT_STATE_MOVING_DOWN" 3 "SEAT_STATE_RECALLING" 0 "SEAT_STATE_STOPPED" 5 "SEAT_STATE_UNDEFINED" 4 "SEAT_STATE_CALIBRATING" ;
VAL_ 1360 VCRIGHT_a252_seatMotorState 1 "SEAT_STATE_MOVING_UP" 2 "SEAT_STATE_MOVING_DOWN" 3 "SEAT_STATE_RECALLING" 0 "SEAT_STATE_STOPPED" 5 "SEAT_STATE_UNDEFINED" 4 "SEAT_STATE_CALIBRATING" ;
VAL_ 1360 VCRIGHT_a206_unitStatusEPBM 14 "EPB_STATUS_SUMMON" 1 "EPB_STATUS_OPEN" 9 "EPB_STATUS_DYNAMIC_APPLYING" 21 "EPB_STATUS_COUNT" 12 "EPB_STATUS_PARK_PENDING" 13 "EPB_STATUS_WINCHMODE_PENDING" 6 "EPB_STATUS_WINCHMODE" 3 "EPB_STATUS_PARK" 0 "EPB_STATUS_UNKNOWN" 4 "EPB_STATUS_START" 18 "EPB_STATUS_RELEASING_FOR_EXTERNAL_PARK" 19 "EPB_STATUS_EXTERNAL_PARKING" 17 "EPB_STATUS_EXTERNAL_DYNAMIC" 10 "EPB_STATUS_RELEASING" 15 "EPB_STATUS_SUMMON_RELEASING" 11 "EPB_STATUS_SERVICE_RELEASING" 7 "EPB_STATUS_WINCHMODE_RELEASING" 16 "EPB_STATUS_SUMMON_PARKING" 8 "EPB_STATUS_PARKING" 2 "EPB_STATUS_DYNAMIC" 5 "EPB_STATUS_SERVICE" 20 "EPB_STATUS_DYNAMIC_PARKING" ;
VAL_ 1360 VCRIGHT_a253_seatMotorState 1 "SEAT_STATE_MOVING_UP" 2 "SEAT_STATE_MOVING_DOWN" 3 "SEAT_STATE_RECALLING" 0 "SEAT_STATE_STOPPED" 5 "SEAT_STATE_UNDEFINED" 4 "SEAT_STATE_CALIBRATING" ;
VAL_ 1360 VCRIGHT_a209_unitStatusEPBM 14 "EPB_STATUS_SUMMON" 1 "EPB_STATUS_OPEN" 9 "EPB_STATUS_DYNAMIC_APPLYING" 21 "EPB_STATUS_COUNT" 12 "EPB_STATUS_PARK_PENDING" 13 "EPB_STATUS_WINCHMODE_PENDING" 6 "EPB_STATUS_WINCHMODE" 3 "EPB_STATUS_PARK" 0 "EPB_STATUS_UNKNOWN" 4 "EPB_STATUS_START" 18 "EPB_STATUS_RELEASING_FOR_EXTERNAL_PARK" 19 "EPB_STATUS_EXTERNAL_PARKING" 17 "EPB_STATUS_EXTERNAL_DYNAMIC" 10 "EPB_STATUS_RELEASING" 15 "EPB_STATUS_SUMMON_RELEASING" 11 "EPB_STATUS_SERVICE_RELEASING" 7 "EPB_STATUS_WINCHMODE_RELEASING" 16 "EPB_STATUS_SUMMON_PARKING" 8 "EPB_STATUS_PARKING" 2 "EPB_STATUS_DYNAMIC" 5 "EPB_STATUS_SERVICE" 20 "EPB_STATUS_DYNAMIC_PARKING" ;
VAL_ 1360 VCRIGHT_a235_seatMotorState 1 "SEAT_STATE_MOVING_UP" 2 "SEAT_STATE_MOVING_DOWN" 3 "SEAT_STATE_RECALLING" 0 "SEAT_STATE_STOPPED" 5 "SEAT_STATE_UNDEFINED" 4 "SEAT_STATE_CALIBRATING" ;
VAL_ 1360 VCRIGHT_a210_unitStatusEPBM 14 "EPB_STATUS_SUMMON" 1 "EPB_STATUS_OPEN" 9 "EPB_STATUS_DYNAMIC_APPLYING" 21 "EPB_STATUS_COUNT" 12 "EPB_STATUS_PARK_PENDING" 13 "EPB_STATUS_WINCHMODE_PENDING" 6 "EPB_STATUS_WINCHMODE" 3 "EPB_STATUS_PARK" 0 "EPB_STATUS_UNKNOWN" 4 "EPB_STATUS_START" 18 "EPB_STATUS_RELEASING_FOR_EXTERNAL_PARK" 19 "EPB_STATUS_EXTERNAL_PARKING" 17 "EPB_STATUS_EXTERNAL_DYNAMIC" 10 "EPB_STATUS_RELEASING" 15 "EPB_STATUS_SUMMON_RELEASING" 11 "EPB_STATUS_SERVICE_RELEASING" 7 "EPB_STATUS_WINCHMODE_RELEASING" 16 "EPB_STATUS_SUMMON_PARKING" 8 "EPB_STATUS_PARKING" 2 "EPB_STATUS_DYNAMIC" 5 "EPB_STATUS_SERVICE" 20 "EPB_STATUS_DYNAMIC_PARKING" ;
VAL_ 1360 VCRIGHT_a225_seatSwitchForward 2 "SWITCH_ON" 0 "SWITCH_SNA" 3 "SWITCH_FAULT" 1 "SWITCH_OFF" ;
VAL_ 1360 VCRIGHT_a224_seatSwitchForward 2 "SWITCH_ON" 0 "SWITCH_SNA" 3 "SWITCH_FAULT" 1 "SWITCH_OFF" ;
VAL_ 1360 VCRIGHT_a227_seatSwitchForward 2 "SWITCH_ON" 0 "SWITCH_SNA" 3 "SWITCH_FAULT" 1 "SWITCH_OFF" ;
VAL_ 1360 VCRIGHT_a226_seatSwitchForward 2 "SWITCH_ON" 0 "SWITCH_SNA" 3 "SWITCH_FAULT" 1 "SWITCH_OFF" ;
VAL_ 1360 VCRIGHT_a227_seatSwitchBack 2 "SWITCH_ON" 0 "SWITCH_SNA" 3 "SWITCH_FAULT" 1 "SWITCH_OFF" ;
VAL_ 1360 VCRIGHT_a206_unitStatusEPB 14 "EPB_STATUS_SUMMON" 1 "EPB_STATUS_OPEN" 9 "EPB_STATUS_DYNAMIC_APPLYING" 21 "EPB_STATUS_COUNT" 12 "EPB_STATUS_PARK_PENDING" 13 "EPB_STATUS_WINCHMODE_PENDING" 6 "EPB_STATUS_WINCHMODE" 3 "EPB_STATUS_PARK" 0 "EPB_STATUS_UNKNOWN" 4 "EPB_STATUS_START" 18 "EPB_STATUS_RELEASING_FOR_EXTERNAL_PARK" 19 "EPB_STATUS_EXTERNAL_PARKING" 17 "EPB_STATUS_EXTERNAL_DYNAMIC" 10 "EPB_STATUS_RELEASING" 15 "EPB_STATUS_SUMMON_RELEASING" 11 "EPB_STATUS_SERVICE_RELEASING" 7 "EPB_STATUS_WINCHMODE_RELEASING" 16 "EPB_STATUS_SUMMON_PARKING" 8 "EPB_STATUS_PARKING" 2 "EPB_STATUS_DYNAMIC" 5 "EPB_STATUS_SERVICE" 20 "EPB_STATUS_DYNAMIC_PARKING" ;
VAL_ 1360 VCRIGHT_a151_windowPinchReason 1 "WINDOW_PINCH_REASON_POWER" 2 "WINDOW_PINCH_REASON_POWER_DIV_SPEED" 3 "WINDOW_PINCH_REASON_POWER_CRUDE" 0 "WINDOW_PINCH_REASON_NONE" 4 "WINDOW_PINCH_REASON_UNUSED" ;
VAL_ 1360 VCRIGHT_a224_seatSwitchBack 2 "SWITCH_ON" 0 "SWITCH_SNA" 3 "SWITCH_FAULT" 1 "SWITCH_OFF" ;
VAL_ 1360 VCRIGHT_a207_unitStatusEPB 14 "EPB_STATUS_SUMMON" 1 "EPB_STATUS_OPEN" 9 "EPB_STATUS_DYNAMIC_APPLYING" 21 "EPB_STATUS_COUNT" 12 "EPB_STATUS_PARK_PENDING" 13 "EPB_STATUS_WINCHMODE_PENDING" 6 "EPB_STATUS_WINCHMODE" 3 "EPB_STATUS_PARK" 0 "EPB_STATUS_UNKNOWN" 4 "EPB_STATUS_START" 18 "EPB_STATUS_RELEASING_FOR_EXTERNAL_PARK" 19 "EPB_STATUS_EXTERNAL_PARKING" 17 "EPB_STATUS_EXTERNAL_DYNAMIC" 10 "EPB_STATUS_RELEASING" 15 "EPB_STATUS_SUMMON_RELEASING" 11 "EPB_STATUS_SERVICE_RELEASING" 7 "EPB_STATUS_WINCHMODE_RELEASING" 16 "EPB_STATUS_SUMMON_PARKING" 8 "EPB_STATUS_PARKING" 2 "EPB_STATUS_DYNAMIC" 5 "EPB_STATUS_SERVICE" 20 "EPB_STATUS_DYNAMIC_PARKING" ;
VAL_ 1360 VCRIGHT_a150_windowPinchReason 1 "WINDOW_PINCH_REASON_POWER" 2 "WINDOW_PINCH_REASON_POWER_DIV_SPEED" 3 "WINDOW_PINCH_REASON_POWER_CRUDE" 0 "WINDOW_PINCH_REASON_NONE" 4 "WINDOW_PINCH_REASON_UNUSED" ;
VAL_ 1360 VCRIGHT_a225_seatSwitchBack 2 "SWITCH_ON" 0 "SWITCH_SNA" 3 "SWITCH_FAULT" 1 "SWITCH_OFF" ;
VAL_ 1360 VCRIGHT_a208_unitStatusEPB 14 "EPB_STATUS_SUMMON" 1 "EPB_STATUS_OPEN" 9 "EPB_STATUS_DYNAMIC_APPLYING" 21 "EPB_STATUS_COUNT" 12 "EPB_STATUS_PARK_PENDING" 13 "EPB_STATUS_WINCHMODE_PENDING" 6 "EPB_STATUS_WINCHMODE" 3 "EPB_STATUS_PARK" 0 "EPB_STATUS_UNKNOWN" 4 "EPB_STATUS_START" 18 "EPB_STATUS_RELEASING_FOR_EXTERNAL_PARK" 19 "EPB_STATUS_EXTERNAL_PARKING" 17 "EPB_STATUS_EXTERNAL_DYNAMIC" 10 "EPB_STATUS_RELEASING" 15 "EPB_STATUS_SUMMON_RELEASING" 11 "EPB_STATUS_SERVICE_RELEASING" 7 "EPB_STATUS_WINCHMODE_RELEASING" 16 "EPB_STATUS_SUMMON_PARKING" 8 "EPB_STATUS_PARKING" 2 "EPB_STATUS_DYNAMIC" 5 "EPB_STATUS_SERVICE" 20 "EPB_STATUS_DYNAMIC_PARKING" ;
VAL_ 1360 VCRIGHT_a226_seatSwitchBack 2 "SWITCH_ON" 0 "SWITCH_SNA" 3 "SWITCH_FAULT" 1 "SWITCH_OFF" ;
VAL_ 1360 VCRIGHT_a210_unitStatusEPB 14 "EPB_STATUS_SUMMON" 1 "EPB_STATUS_OPEN" 9 "EPB_STATUS_DYNAMIC_APPLYING" 21 "EPB_STATUS_COUNT" 12 "EPB_STATUS_PARK_PENDING" 13 "EPB_STATUS_WINCHMODE_PENDING" 6 "EPB_STATUS_WINCHMODE" 3 "EPB_STATUS_PARK" 0 "EPB_STATUS_UNKNOWN" 4 "EPB_STATUS_START" 18 "EPB_STATUS_RELEASING_FOR_EXTERNAL_PARK" 19 "EPB_STATUS_EXTERNAL_PARKING" 17 "EPB_STATUS_EXTERNAL_DYNAMIC" 10 "EPB_STATUS_RELEASING" 15 "EPB_STATUS_SUMMON_RELEASING" 11 "EPB_STATUS_SERVICE_RELEASING" 7 "EPB_STATUS_WINCHMODE_RELEASING" 16 "EPB_STATUS_SUMMON_PARKING" 8 "EPB_STATUS_PARKING" 2 "EPB_STATUS_DYNAMIC" 5 "EPB_STATUS_SERVICE" 20 "EPB_STATUS_DYNAMIC_PARKING" ;
VAL_ 1360 VCRIGHT_a209_unitStatusEPB 14 "EPB_STATUS_SUMMON" 1 "EPB_STATUS_OPEN" 9 "EPB_STATUS_DYNAMIC_APPLYING" 21 "EPB_STATUS_COUNT" 12 "EPB_STATUS_PARK_PENDING" 13 "EPB_STATUS_WINCHMODE_PENDING" 6 "EPB_STATUS_WINCHMODE" 3 "EPB_STATUS_PARK" 0 "EPB_STATUS_UNKNOWN" 4 "EPB_STATUS_START" 18 "EPB_STATUS_RELEASING_FOR_EXTERNAL_PARK" 19 "EPB_STATUS_EXTERNAL_PARKING" 17 "EPB_STATUS_EXTERNAL_DYNAMIC" 10 "EPB_STATUS_RELEASING" 15 "EPB_STATUS_SUMMON_RELEASING" 11 "EPB_STATUS_SERVICE_RELEASING" 7 "EPB_STATUS_WINCHMODE_RELEASING" 16 "EPB_STATUS_SUMMON_PARKING" 8 "EPB_STATUS_PARKING" 2 "EPB_STATUS_DYNAMIC" 5 "EPB_STATUS_SERVICE" 20 "EPB_STATUS_DYNAMIC_PARKING" ;
VAL_ 1360 VCRIGHT_a225_seatMotorState 1 "SEAT_STATE_MOVING_UP" 2 "SEAT_STATE_MOVING_DOWN" 3 "SEAT_STATE_RECALLING" 0 "SEAT_STATE_STOPPED" 5 "SEAT_STATE_UNDEFINED" 4 "SEAT_STATE_CALIBRATING" ;
VAL_ 1360 VCRIGHT_a224_seatMotorState 1 "SEAT_STATE_MOVING_UP" 2 "SEAT_STATE_MOVING_DOWN" 3 "SEAT_STATE_RECALLING" 0 "SEAT_STATE_STOPPED" 5 "SEAT_STATE_UNDEFINED" 4 "SEAT_STATE_CALIBRATING" ;
VAL_ 1360 VCRIGHT_a227_seatMotorState 1 "SEAT_STATE_MOVING_UP" 2 "SEAT_STATE_MOVING_DOWN" 3 "SEAT_STATE_RECALLING" 0 "SEAT_STATE_STOPPED" 5 "SEAT_STATE_UNDEFINED" 4 "SEAT_STATE_CALIBRATING" ;
VAL_ 1360 VCRIGHT_a226_seatMotorState 1 "SEAT_STATE_MOVING_UP" 2 "SEAT_STATE_MOVING_DOWN" 3 "SEAT_STATE_RECALLING" 0 "SEAT_STATE_STOPPED" 5 "SEAT_STATE_UNDEFINED" 4 "SEAT_STATE_CALIBRATING" ;
VAL_ 1360 VCRIGHT_a164_stopReason 6 "WINDOW_TEST_STOP_REASON_UDS" 2 "WINDOW_TEST_STOP_REASON_THERMAL" 3 "WINDOW_TEST_STOP_REASON_TIMEOUT" 5 "WINDOW_TEST_STOP_REASON_DOOR" 4 "WINDOW_TEST_STOP_REASON_SWITCH" 0 "WINDOW_TEST_STOP_REASON_NONE" 1 "WINDOW_TEST_STOP_REASON_PINCH" ;
VAL_ 1360 VCRIGHT_a183_stopReason 5 "DOOR_STATE_TEST_STOP_REASON_FAILED_OPENING" 8 "DOOR_STATE_TEST_STOP_REASON_UDS" 7 "DOOR_STATE_TEST_STOP_REASON_TIMEOUT" 4 "DOOR_STATE_TEST_STOP_REASON_FAILED_CLOSED" 6 "DOOR_STATE_TEST_STOP_REASON_FAILED_OPENED" 2 "DOOR_STATE_TEST_STOP_REASON_EXTERIOR_HANDLE" 3 "DOOR_STATE_TEST_STOP_REASON_LOCKED" 0 "DOOR_STATE_TEST_STOP_REASON_NONE" 1 "DOOR_STATE_TEST_STOP_REASON_INTERIOR_HANDLE" ;
VAL_ 1360 VCRIGHT_a183_lastState 5 "DOOR_STATE_TEST_STATE_E_OPENED" 4 "DOOR_STATE_TEST_STATE_D_WAIT_FOR_OPENED" 6 "DOOR_STATE_TEST_STATE_F_DONE" 0 "DOOR_STATE_TEST_STATE_IDLE" 1 "DOOR_STATE_TEST_STATE_A_CLOSED" 3 "DOOR_STATE_TEST_STATE_C_OPENING" 2 "DOOR_STATE_TEST_STATE_B_WAIT_FOR_OPENING" ;
VAL_ 1360 VCRIGHT_a276_mirrorState 3 "MIRROR_STATE_FOLD_UNFOLD" 1 "MIRROR_STATE_TILT_X" 0 "MIRROR_STATE_IDLE" 2 "MIRROR_STATE_TILT_Y" 4 "MIRROR_STATE_RECALL" ;
VAL_ 1360 VCRIGHT_a164_lastState 4 "WINDOW_TEST_STATE_D_MOVE_UP_BUILD_PINCH_CALIBRATION_TABLE" 3 "WINDOW_TEST_STATE_C_MOVE_DOWN" 5 "WINDOW_TEST_STATE_E_FIND_POSITION" 2 "WINDOW_TEST_STATE_B_FIND_TOP" 0 "WINDOW_TEST_STATE_IDLE" 1 "WINDOW_TEST_STATE_A_FIND_BOTTOM" ;
VAL_ 1360 VCRIGHT_a272_actualState 3 "VEHICLE_POWER_STATE_DRIVE" 1 "VEHICLE_POWER_STATE_CONDITIONING" 2 "VEHICLE_POWER_STATE_ACCESSORY" 0 "VEHICLE_POWER_STATE_OFF" ;
VAL_ 1360 VCRIGHT_a157_windowThermalMode 0 "WINDOW_THERMAL_MODE_SNA" 2 "WINDOW_THERMAL_MODE_ALERT" 1 "WINDOW_THERMAL_MODE_NORMAL" 3 "WINDOW_THERMAL_MODE_CRITICAL" ;
VAL_ 1360 VCRIGHT_a272_expectedState 3 "VEHICLE_POWER_STATE_DRIVE" 1 "VEHICLE_POWER_STATE_CONDITIONING" 2 "VEHICLE_POWER_STATE_ACCESSORY" 0 "VEHICLE_POWER_STATE_OFF" ;
VAL_ 1360 VCRIGHT_a156_windowThermalMode 0 "WINDOW_THERMAL_MODE_SNA" 2 "WINDOW_THERMAL_MODE_ALERT" 1 "WINDOW_THERMAL_MODE_NORMAL" 3 "WINDOW_THERMAL_MODE_CRITICAL" ;
VAL_ 1360 VCRIGHT_a276_mirrorDebugType 6 "MIRROR_DEBUG_RECALL_END" 1 "MIRROR_DEBUG_TIMEOUT" 4 "MIRROR_DEBUG_RECALL_POSITION" 2 "MIRROR_DEBUG_STALL" 3 "MIRROR_DEBUG_NOMINAL_POSITION_CHANGE" 5 "MIRROR_DEBUG_RECALL_START" 0 "MIRROR_DEBUG_NONE" ;
VAL_ 1360 VCRIGHT_a155_windowThermalMode 0 "WINDOW_THERMAL_MODE_SNA" 2 "WINDOW_THERMAL_MODE_ALERT" 1 "WINDOW_THERMAL_MODE_NORMAL" 3 "WINDOW_THERMAL_MODE_CRITICAL" ;
VAL_ 1360 VCRIGHT_a185_summonFaultReason 9 "EPB_SUMMONFAULT_VEH_CAN_FAULT" 21 "EPB_SUMMONFAULT_PASSIVE_REQUEST" 26 "EPB_SUMMONFAULT_START_IN_UNAVAILABLE" 5 "EPB_SUMMONFAULT_DI_FAULT" 4 "EPB_SUMMONFAULT_EPBM_MIA" 12 "EPB_SUMMONFAULT_SPEED" 14 "EPB_SUMMONFAULT_PARK_MIA" 19 "EPB_SUMMONFAULT_EPB_FAULT" 25 "EPB_SUMMONFAULT_REMOTE_UNIT_FAULTED" 11 "EPB_SUMMONFAULT_EPBM_REQUEST" 16 "EPB_SUMMONFAULT_PM_REQUEST" 6 "EPB_SUMMONFAULT_DI_APC_FAULT" 13 "EPB_SUMMONFAULT_EXTERNAL" 23 "EPB_SUMMONFAULT_REMOTE_SUMMON_FAULTED" 24 "EPB_SUMMONFAULT_LOCAL_UNIT_FAULTED" 28 "EPB_SUMMONFAULT_REMOTE_DID_NOT_START" 1 "EPB_SUMMONFAULT_DI_MIA" 15 "EPB_SUMMONFAULT_PM_MIA" 27 "EPB_SUMMONFAULT_INVALID_REMOTE_STATE" 0 "EPB_SUMMONFAULT_NONE" 10 "EPB_SUMMONFAULT_EAC_NOT_ALLOWED" 22 "EPB_SUMMONFAULT_EPBREMOTE_MIA" 18 "EPB_SUMMONFAULT_MISMATCH" 3 "EPB_SUMMONFAULT_ESP_MIA" 2 "EPB_SUMMONFAULT_DAS_MIA" 20 "EPB_SUMMONFAULT_DI_STATE_INVALID" 8 "EPB_SUMMONFAULT_ESP_FAULT" 17 "EPB_SUMMONFAULT_OOC" 7 "EPB_SUMMONFAULT_DAS_FAULT" ;
VAL_ 1360 VCRIGHT_a154_windowThermalMode 0 "WINDOW_THERMAL_MODE_SNA" 2 "WINDOW_THERMAL_MODE_ALERT" 1 "WINDOW_THERMAL_MODE_NORMAL" 3 "WINDOW_THERMAL_MODE_CRITICAL" ;
VAL_ 1360 VCRIGHT_alertType 0 "ALERT_CLEARED" 1 "ALERT_SET" ;
VAL_ 1360 VCRIGHT_alertID 270 "VCRIGHT_a270_seatLiftHCEncStlDbg" 305 "VCRIGHT_a305_rearIntHandleShorted" 306 "VCRIGHT_a306_handleDisconnectedF" 247 "VCRIGHT_a247_seatHeatMIARearC" 105 "VCRIGHT_a105_TAS_MIA" 12 "VCRIGHT_a012_CPUReset" 148 "VCRIGHT_a148_incarMidTempSns" 134 "VCRIGHT_a134_hvacUpprModeUncalib" 286 "VCRIGHT_a286_windowSpeedInvalidF" 276 "VCRIGHT_a276_mirrorDebug" 202 "VCRIGHT_a202_epbmUnderIStatic" 292 "VCRIGHT_a292_buckleFaultedRearC" 320 "VCRIGHT_a320_windowPwrDerivFDBG" 215 "VCRIGHT_a215_currentDesyncWarning" 100 "VCRIGHT_a100_CANbus_MIA" 182 "VCRIGHT_a182_emergencyLatchRel" 141 "VCRIGHT_a141_hvacUpperModeFault" 41 "VCRIGHT_a041_HighCPULoad" 118 "VCRIGHT_a118_VCFRONT_MIA" 109 "VCRIGHT_a109_RCM_MIA" 242 "VCRIGHT_a242_seatHeatIRearL" 136 "VCRIGHT_a136_hvacIntakeFault" 240 "VCRIGHT_a240_seatHeatShortFront" 324 "VCRIGHT_a324_mirrorHeatFault" 188 "VCRIGHT_a188_latchUnableToRearmF" 110 "VCRIGHT_a110_GTW_MIA" 210 "VCRIGHT_a210_epbStateTime" 152 "VCRIGHT_a152_windowUncalFront" 111 "VCRIGHT_a111_EPBR_MIA" 245 "VCRIGHT_a245_seatHeatIRearC" 170 "VCRIGHT_a170_windowCurrentPeakR" 196 "VCRIGHT_a196_VEHCANOverterminate" 130 "VCRIGHT_a130_hvacLHBleedUncalib" 224 "VCRIGHT_a224_seatEncStallTrack" 159 "VCRIGHT_a159_windowPinchOverideR" 221 "VCRIGHT_a221_seatCurrStallBack" 260 "VCRIGHT_a260_latchDisarmDelayR" 266 "VCRIGHT_a266_seatLiftStallDebug" 21 "VCRIGHT_a021_TaskSchedulerError" 230 "VCRIGHT_a230_seatEncOverTilt" 161 "VCRIGHT_a161_windowUndercurrentR" 192 "VCRIGHT_a192_gloveboxLatchRel" 142 "VCRIGHT_a142_hvacLowerModeFault" 238 "VCRIGHT_a238_lumbarValveMIA" 236 "VCRIGHT_a236_lumbarOverPresA" 151 "VCRIGHT_a151_windowPinchRear" 209 "VCRIGHT_a209_epbStateMisTime" 131 "VCRIGHT_a131_hvacRHBleedUncalib" 104 "VCRIGHT_a104_DAS_MIA" 116 "VCRIGHT_a116_VCRIGHT_MIA" 191 "VCRIGHT_a191_gloveboxPower" 157 "VCRIGHT_a157_windowNoInputRear" 172 "VCRIGHT_a172_SPI_MIA" 31 "VCRIGHT_a031_UDSActive" 129 "VCRIGHT_a129_hvacIntakeUncalib" 184 "VCRIGHT_a184_trunkFailedOpening" 304 "VCRIGHT_a304_frontIntHandleShorted" 263 "VCRIGHT_a263_seatTrackStallDebug" 200 "VCRIGHT_a200_motorPhantomEncoder" 233 "VCRIGHT_a233_seatCurrUnderBack" 138 "VCRIGHT_a138_hvacRHBleedFault" 220 "VCRIGHT_a220_seatCurrStallTrack" 187 "VCRIGHT_a187_latchReleaseFailedR" 168 "VCRIGHT_a168_windowDebugPinchR" 243 "VCRIGHT_a243_seatHeatShortRearL" 166 "VCRIGHT_a166_windowDebug" 144 "VCRIGHT_a144_evaporatorTempSns" 282 "VCRIGHT_a282_latchUnexpectedArmF" 120 "VCRIGHT_a120_DI_DRIVE_MIA" 101 "VCRIGHT_a101_PM_MIA" 115 "VCRIGHT_a115_VCSEC_MIA" 145 "VCRIGHT_a145_ductLeftTempSns" 264 "VCRIGHT_a264_seatBackStallDebug" 22 "VCRIGHT_a022_TaskInitError" 255 "VCRIGHT_a255_PTCOverTemp" 229 "VCRIGHT_a229_seatEncOverBack" 259 "VCRIGHT_a259_latchDisarmDelayF" 194 "VCRIGHT_a194_cntctrPwrEFuseFault" 146 "VCRIGHT_a146_ductRightTempSns" 223 "VCRIGHT_a223_seatCurrStallLift" 167 "VCRIGHT_a167_windowDebugPinchF" 195 "VCRIGHT_a195_hvcEFuseFault" 98 "VCRIGHT_a098_DI_THERMAL_MIA" 283 "VCRIGHT_a283_latchUnexpectedArmR" 231 "VCRIGHT_a231_seatEncOverLift" 269 "VCRIGHT_a269_seatTiltHCEncStlDbg" 262 "VCRIGHT_a262_PTCFaulted" 257 "VCRIGHT_a257_THSMIA" 280 "VCRIGHT_a280_latchDidNotDisarmF" 169 "VCRIGHT_a169_windowCurrentPeakF" 15 "VCRIGHT_a015_NVMMAlert" 153 "VCRIGHT_a153_windowUncalRear" 248 "VCRIGHT_a248_seatHeatIRearR" 216 "VCRIGHT_a216_SPI_MIA_debugData1" 63 "VCRIGHT_a063_SwitchFault" 3 "VCRIGHT_a003_SWAssertion" 139 "VCRIGHT_a139_hvacLHVaneFault" 162 "VCRIGHT_a162_windowEncoderStallF" 207 "VCRIGHT_a207_epbmEnableWrong" 150 "VCRIGHT_a150_windowPinchFront" 149 "VCRIGHT_a149_incarDeepTempSns" 164 "VCRIGHT_a164_windowFactoryTest" 119 "VCRIGHT_a119_SCCM_MIA" 214 "VCRIGHT_a214_epbmOverIDynNew" 234 "VCRIGHT_a234_seatCurrUnderTilt" 211 "VCRIGHT_a211_epbmUnderIStaticNew" 147 "VCRIGHT_a147_incarProbeTempSns" 322 "VCRIGHT_a322_windowPwrDerivRDBG" 113 "VCRIGHT_a113_UI_MIA" 199 "VCRIGHT_a199_PRVCANUndertrminate" 212 "VCRIGHT_a212_epbmOverIStaticNew" 46 "VCRIGHT_a046_Task1000msError" 163 "VCRIGHT_a163_windowEncoderStallR" 321 "VCRIGHT_a321_windowPwrDeriv2FDBG" 272 "VCRIGHT_a272_vhclPwrStateMsmtch" 185 "VCRIGHT_a185_summonAborted" 217 "VCRIGHT_a217_SPI_MIA_debugData2" 252 "VCRIGHT_a252_seatUncalBack" 241 "VCRIGHT_a241_seatHeatMIAFront" 135 "VCRIGHT_a135_hvacLowrModeUncalib" 107 "VCRIGHT_a107_BMS_MIA" 256 "VCRIGHT_a256_PTCCurrentDrawNoReq" 265 "VCRIGHT_a265_seatTiltStallDebug" 114 "VCRIGHT_a114_ESP_MIA" 249 "VCRIGHT_a249_seatHeatShortRearR" 143 "VCRIGHT_a143_mirrorManuallyFolded" 181 "VCRIGHT_a181_rearDoorLatchRehome" 156 "VCRIGHT_a156_windowNoInputFront" 193 "VCRIGHT_a193_amplifierEFuseFault" 190 "VCRIGHT_a190_eFuseMgmtVbatFused" 258 "VCRIGHT_a258_PTCStuckInBoot" 277 "VCRIGHT_a277_BLERightUnderVoltage" 239 "VCRIGHT_a239_seatHeatIFront" 293 "VCRIGHT_a293_buckleFaultedRearR" 42 "VCRIGHT_a042_HighStackUsage" 112 "VCRIGHT_a112_EPBL_MIA" 117 "VCRIGHT_a117_VCLEFT_MIA" 189 "VCRIGHT_a189_latchUnableToRearmR" 225 "VCRIGHT_a225_seatEncStallBack" 237 "VCRIGHT_a237_lumbarOverPresB" 103 "VCRIGHT_a103_CP_MIA" 61 "VCRIGHT_a061_XCPConnected" 45 "VCRIGHT_a045_Task100msError" 2 "VCRIGHT_a002_PowerLossReset" 290 "VCRIGHT_a290_occupancyFaultedFront" 226 "VCRIGHT_a226_seatEncStallTilt" 323 "VCRIGHT_a323_windowPwrDeriv2RDBG" 208 "VCRIGHT_a208_epbFaulted" 30 "VCRIGHT_a030_ECULogUploadRequest" 102 "VCRIGHT_a102_PTC_MIA" 235 "VCRIGHT_a235_seatCurrUnderLift" 154 "VCRIGHT_a154_windowThermalFront" 267 "VCRIGHT_a267_seatTrackHCEncStlDbg" 165 "VCRIGHT_a165_windowFactoryTest2" 291 "VCRIGHT_a291_buckleFaultedFront" 246 "VCRIGHT_a246_seatHeatShortRearC" 204 "VCRIGHT_a204_epbmUnderIDyn" 183 "VCRIGHT_a183_doorStateFactoryTest" 60 "VCRIGHT_a060_engineeringBuild" 205 "VCRIGHT_a205_epbmOverIDyn" 1 "VCRIGHT_a001_WatchdogReset" 186 "VCRIGHT_a186_latchReleaseFailedF" 232 "VCRIGHT_a232_seatCurrUnderTrack" 275 "VCRIGHT_a275_rightTurnLightFault" 158 "VCRIGHT_a158_windowPinchOverideF" 180 "VCRIGHT_a180_frontDoorLatchRehome" 310 "VCRIGHT_a310_mirrorFoldStall" 197 "VCRIGHT_a197_VEHCANUndertrminate" 222 "VCRIGHT_a222_seatCurrStallTilt" 244 "VCRIGHT_a244_seatHeatMIARearL" 218 "VCRIGHT_a218_motorDriverFault" 213 "VCRIGHT_a213_epbmUnderIDynNew" 203 "VCRIGHT_a203_epbmOverIStatic" 273 "VCRIGHT_a273_handleStuckActiveF" 160 "VCRIGHT_a160_windowUndercurrentF" 278 "VCRIGHT_a278_hvacPtcHeatingUnavailable" 64 "VCRIGHT_a064_busSleepReqTimeout" 198 "VCRIGHT_a198_PRVCANOverterminate" 250 "VCRIGHT_a250_seatHeatMIARearR" 0 "VCRIGHT_ALERT_DO_NOT_USE_ZERO" 271 "VCRIGHT_a271_THSSensorFault" 219 "VCRIGHT_a219_motorCurrentDropout" 274 "VCRIGHT_a274_handleStuckActiveR" 59 "VCRIGHT_a059_inputResistanceHigh" 281 "VCRIGHT_a281_latchDidNotDisarmR" 253 "VCRIGHT_a253_seatUncalTilt" 251 "VCRIGHT_a251_seatUncalTrack" 10 "VCRIGHT_a010_ExtSupplyVoltError" 99 "VCRIGHT_a099_PARK_MIA" 174 "VCRIGHT_a174_BLERightPowerCycled" 228 "VCRIGHT_a228_seatEncOverTrack" 254 "VCRIGHT_a254_seatUncalLift" 155 "VCRIGHT_a155_windowThermalRear" 44 "VCRIGHT_a044_Task10msError" 132 "VCRIGHT_a132_hvacLHVaneUncalib" 97 "VCRIGHT_a097_CMP_MIA" 140 "VCRIGHT_a140_hvacRHVaneFault" 268 "VCRIGHT_a268_seatBackHCEncStlDbg" 137 "VCRIGHT_a137_hvacLHBleedFault" 227 "VCRIGHT_a227_seatEncStallLift" 106 "VCRIGHT_a106_PCS_MIA" 43 "VCRIGHT_a043_Task1msError" 133 "VCRIGHT_a133_hvacRHVaneUncalib" 13 "VCRIGHT_a013_AlertManagerFault" 201 "VCRIGHT_a201_motorDutyEncDisabl" 287 "VCRIGHT_a287_windowSpeedInvalidR" 307 "VCRIGHT_a307_handleDisconnectedR" 62 "VCRIGHT_a062_XCPWasConnected" 206 "VCRIGHT_a206_epbWrongDirection" 108 "VCRIGHT_a108_DIS_MIA" ;
VAL_ 2002 BMS_1HzDebug_Id 3 "BMS_1HZ_DBG_ENERGY_PACK_INPUTS_2" 5 "BMS_1HZ_DBG_END" 1 "BMS_1HZ_DBG_BALANCE2" 4 "BMS_1HZ_STACK_USAGE" 0 "BMS_1HZ_DBG_BALANCE1" 2 "BMS_1HZ_DBG_ENERGY_PACK_INPUTS_1" ;
VAL_ 605 CP_coldWeatherMode 1 "CP_COLD_WEATHER_LATCH_MITIGATION" 0 "CP_COLD_WEATHER_NONE" ;
VAL_ 605 CP_inductiveSensorState 6 "CP_INDUCTIVE_SENSOR_RESET" 0 "CP_INDUCTIVE_SENSOR_INIT" 5 "CP_INDUCTIVE_SENSOR_FAULT" 3 "CP_INDUCTIVE_SENSOR_PAUSE" 4 "CP_INDUCTIVE_SENSOR_WAIT_FOR_INIT" 1 "CP_INDUCTIVE_SENSOR_POLL" 2 "CP_INDUCTIVE_SENSOR_SHUTDOWN" ;
VAL_ 605 CP_inductiveDoorState 1 "CP_INDUCTIVE_DOOR_INIT_FROM_CHARGE" 2 "CP_INDUCTIVE_DOOR_INIT_FROM_DRIVE" 3 "CP_INDUCTIVE_DOOR_PRESENT" 5 "CP_INDUCTIVE_DOOR_OFF_DRIVE" 4 "CP_INDUCTIVE_DOOR_NOT_PRESENT" 7 "CP_INDUCTIVE_DOOR_FAULT" 0 "CP_INDUCTIVE_DOOR_INIT" 6 "CP_INDUCTIVE_DOOR_OFF_CHARGE" ;
VAL_ 605 CP_faultLineSensed 0 "FAULT_LINE_CLEARED" 1 "FAULT_LINE_SET" ;
VAL_ 605 CP_UHF_controlState 4 "CP_UHF_PREPARE_RX" 2 "CP_UHF_IDLE" 9 "CP_UHF_SLEEP" 3 "CP_UHF_CALIBRATE" 0 "CP_UHF_INIT" 1 "CP_UHF_CONFIG" 5 "CP_UHF_RX" 6 "CP_UHF_CHECK_RX" 10 "CP_UHF_FAULT" 8 "CP_UHF_HANDLE_FOUND" 7 "CP_UHF_READ_RXFIFO" ;
VAL_ 605 CP_ledColor 7 "CP_LEDS_AMBER" 0 "CP_LEDS_OFF" 8 "CP_LEDS_RAVE" 6 "CP_LEDS_FLASHING_AMBER" 3 "CP_LEDS_BLUE" 1 "CP_LEDS_RED" 5 "CP_LEDS_FLASHING_GREEN" 10 "CP_LEDS_FLASHING_BLUE" 9 "CP_LEDS_DEBUG" 4 "CP_LEDS_WHITE" 2 "CP_LEDS_GREEN" ;
VAL_ 605 CP_latch2ControlState 5 "CP_latchEngaging" 2 "CP_latchDisengageRequested" 3 "CP_latchDisengaging" 0 "CP_latchInit" 1 "CP_latchIdle" 4 "CP_latchDisengaged" ;
VAL_ 605 CP_latchControlState 5 "CP_latchEngaging" 2 "CP_latchDisengageRequested" 3 "CP_latchDisengaging" 0 "CP_latchInit" 1 "CP_latchIdle" 4 "CP_latchDisengaged" ;
VAL_ 605 CP_doorControlState 1 "CP_doorIdle" 0 "CP_doorInit" 4 "CP_doorSenseOpen" 2 "CP_doorOpenRequested" 3 "CP_doorOpening" 6 "CP_doorSenseClosed" 5 "CP_doorClosing" ;
VAL_ 605 CP_latch2State 1 "CP_LATCH_DISENGAGED" 2 "CP_LATCH_ENGAGED" 0 "CP_LATCH_SNA" 3 "CP_LATCH_BLOCKING" ;
VAL_ 605 CP_latchState 1 "CP_LATCH_DISENGAGED" 2 "CP_LATCH_ENGAGED" 0 "CP_LATCH_SNA" 3 "CP_LATCH_BLOCKING" ;
VAL_ 605 CP_chargeCablePresent 0 "CABLE_NOT_PRESENT" 1 "CABLE_PRESENT" ;
VAL_ 605 CP_type 1 "CP_TYPE_EURO_IEC" 0 "CP_TYPE_US_TESLA" 3 "CP_TYPE_IEC_CCS" 2 "CP_TYPE_GB" ;
VAL_ 2034 BMS_verResourceRequest 2 "WAKE_UP" 0 "NONE" 3 "SHUT_DOWN" 1 "KEEP_ON" ;
VAL_ 2034 BMS_posIsolationSensorState 1 "SENSOR_ENABLED" 0 "SENSOR_DISABLED" ;
VAL_ 2034 BMS_bmsResourceRequest 2 "WAKE_UP" 0 "NONE" 3 "SHUT_DOWN" 1 "KEEP_ON" ;
VAL_ 2034 BMS_negIsolationSensorState 1 "SENSOR_ENABLED" 0 "SENSOR_DISABLED" ;
VAL_ 2034 BMS_hvpResourceRequest 2 "WAKE_UP" 0 "NONE" 3 "SHUT_DOWN" 1 "KEEP_ON" ;
VAL_ 2034 BMS_positiveRIsoState 0 "ISO_INITIALIZE_ISO_TEST" 3 "ISO_SAMPLE_POST_ISO_VOLTAGES" 4 "ISO_TEST_COMPLETE" 2 "ISO_ACTIVATE_ISOLATION_RESISTOR" 1 "ISO_SAMPLE_PRE_ISO_VOLTAGES" ;
VAL_ 2034 BMS_cpResourceRequest 2 "WAKE_UP" 0 "NONE" 3 "SHUT_DOWN" 1 "KEEP_ON" ;
VAL_ 2034 BMS_vehBusResourceRequest 2 "WAKE_UP" 0 "NONE" 3 "SHUT_DOWN" 1 "KEEP_ON" ;
VAL_ 2034 BMS_hvsBusResourceRequest 2 "WAKE_UP" 0 "NONE" 3 "SHUT_DOWN" 1 "KEEP_ON" ;
VAL_ 2034 BMS_cacUpdateEndPoint 3 "BMS_CAC_INVALID_POINT" 1 "BMS_CAC_CANDIDATE_POINT_1" 0 "BMS_CAC_INITIAL_POINT" 2 "BMS_CAC_CANDIDATE_POINT_2" ;
VAL_ 2034 BMS_negativeRIsoState 0 "ISO_INITIALIZE_ISO_TEST" 3 "ISO_SAMPLE_POST_ISO_VOLTAGES" 4 "ISO_TEST_COMPLETE" 2 "ISO_ACTIVATE_ISOLATION_RESISTOR" 1 "ISO_SAMPLE_PRE_ISO_VOLTAGES" ;
VAL_ 2034 BMS_hviBusResourceRequest 2 "WAKE_UP" 0 "NONE" 3 "SHUT_DOWN" 1 "KEEP_ON" ;
VAL_ 2034 BMS_cacUpdateStartPoint 3 "BMS_CAC_INVALID_POINT" 1 "BMS_CAC_CANDIDATE_POINT_1" 0 "BMS_CAC_INITIAL_POINT" 2 "BMS_CAC_CANDIDATE_POINT_2" ;
VAL_ 2034 BMS_isolationMode 3 "ISO_VEHICLE_ISOLATION_MODE" 5 "ISO_FEIM_POSITIVE_MODE" 2 "ISO_POSITIVE_ISOLATION_MODE" 4 "ISO_FEIM_NEGATIVE_MODE" 0 "ISO_MODE_RESET" 1 "ISO_NEGATIVE_ISOLATION_MODE" ;
VAL_ 2034 BMS_sleepRequest 5 "HVS_POWERING_UP" 0 "INIT" 4 "HVS_POWERING_DOWN" 6 "ALL_ON" 2 "STOPPING" 1 "STOP" 3 "SOLO_WAKE" ;
VAL_ 2034 BMS_sleepState 5 "HVS_POWERING_UP" 0 "INIT" 4 "HVS_POWERING_DOWN" 6 "ALL_ON" 2 "STOPPING" 1 "STOP" 3 "SOLO_WAKE" ;
VAL_ 2034 BMS_verResourceState 1 "POWERING_DOWN" 2 "POWERING_UP" 4 "MIA" 3 "SILENT" 0 "OFF" 5 "ON" ;
VAL_ 2034 BMS_bmsResourceState 1 "POWERING_DOWN" 2 "POWERING_UP" 4 "MIA" 3 "SILENT" 0 "OFF" 5 "ON" ;
VAL_ 2034 BMS_pcsResourceState 1 "POWERING_DOWN" 2 "POWERING_UP" 4 "MIA" 3 "SILENT" 0 "OFF" 5 "ON" ;
VAL_ 2034 BMS_hvpResourceState 1 "POWERING_DOWN" 2 "POWERING_UP" 4 "MIA" 3 "SILENT" 0 "OFF" 5 "ON" ;
VAL_ 2034 BMS_cpResourceState 1 "POWERING_DOWN" 2 "POWERING_UP" 4 "MIA" 3 "SILENT" 0 "OFF" 5 "ON" ;
VAL_ 2034 BMS_vehBusResourceState 1 "POWERING_DOWN" 2 "POWERING_UP" 4 "MIA" 3 "SILENT" 0 "OFF" 5 "ON" ;
VAL_ 2034 BMS_hvsBusResourceState 1 "POWERING_DOWN" 2 "POWERING_UP" 4 "MIA" 3 "SILENT" 0 "OFF" 5 "ON" ;
VAL_ 2034 BMS_cacActivePoint 3 "BMS_CAC_INVALID_POINT" 1 "BMS_CAC_CANDIDATE_POINT_1" 0 "BMS_CAC_INITIAL_POINT" 2 "BMS_CAC_CANDIDATE_POINT_2" ;
VAL_ 2034 BMS_hviBusResourceState 1 "POWERING_DOWN" 2 "POWERING_UP" 4 "MIA" 3 "SILENT" 0 "OFF" 5 "ON" ;
VAL_ 2034 BMS_10HzDebug_Id 19 "BMS_10HZ_DBG_CAC_3" 23 "BMS_10HZ_DBG_ADC_DCLINK" 16 "BMS_10HZ_DBG_HYST" 10 "BMS_10HZ_DBG_THM_MODEL_DATA_7" 26 "BMS_10HZ_DBG_POWER_PREDICTION_1" 20 "BMS_10HZ_DBG_WAKE_TIMERS" 18 "BMS_10HZ_DBG_CAC_2" 22 "BMS_10HZ_DBG_ADC_CP" 17 "BMS_10HZ_DBG_CAC_1" 29 "BMS_10HZ_DBG_SLEEP_WAKE" 4 "BMS_10HZ_DBG_THM_MODEL_DATA_1" 7 "BMS_10HZ_DBG_THM_MODEL_DATA_4" 24 "BMS_10HZ_DBG_ADC_MISC" 21 "BMS_10HZ_DBG_ADC_VREF" 5 "BMS_10HZ_DBG_THM_MODEL_DATA_2" 8 "BMS_10HZ_DBG_THM_MODEL_DATA_5" 2 "BMS_10HZ_DBG_ISOLATION" 28 "BMS_10HZ_DBG_POWER_PREDICTION_3" 11 "BMS_10HZ_DBG_THM_MODEL_DATA_8" 14 "BMS_10HZ_DBG_THM_MODEL_DATA_11" 6 "BMS_10HZ_DBG_THM_MODEL_DATA_3" 15 "BMS_10HZ_DBG_PACK_VOLTAGES" 25 "BMS_10HZ_DBG_ADC_FLOOD" 0 "BMS_10HZ_DBG_STATE" 9 "BMS_10HZ_DBG_THM_MODEL_DATA_6" 12 "BMS_10HZ_DBG_THM_MODEL_DATA_9" 1 "BMS_10HZ_DBG_AHR_COUNTER" 13 "BMS_10HZ_DBG_THM_MODEL_DATA_10" 3 "BMS_10HZ_DBG_SOC_RESTING" 27 "BMS_10HZ_DBG_POWER_PREDICTION_2" ;
VAL_ 676 PCS_dcdcBusbarTemp 511 "SNA" ;
VAL_ 676 PCS_ambientTemp -1023 "SNA" ;
VAL_ 676 PCS_dcdcTemp -1023 "SNA" ;
VAL_ 676 PCS_chgPhCTemp -1023 "SNA" ;
VAL_ 676 PCS_chgPhBTemp -1023 "SNA" ;
VAL_ 676 PCS_chgPhATemp -1023 "SNA" ;
VAL_ 857 VCSEC_BLEDeviceStatusIndex 1 "BLE_DEVICE_1" 0 "BLE_DEVICE_0" 3 "BLE_DEVICE_3" 2 "BLE_DEVICE_2" ;
VAL_ 259 VCRIGHT_mirrorRecallState 5 "MIRROR_RECALL_STATE_RECALLING_STOPPED" 2 "MIRROR_RECALL_STATE_RECALLING_AXIS_2" 0 "MIRROR_RECALL_STATE_INIT" 3 "MIRROR_RECALL_STATE_RECALLING_COMPLETE" 4 "MIRROR_RECALL_STATE_RECALLING_FAILED" 1 "MIRROR_RECALL_STATE_RECALLING_AXIS_1" ;
VAL_ 259 VCRIGHT_trunkLatchStatus 8 "LATCH_FAULT" 2 "LATCH_CLOSED" 1 "LATCH_OPENED" 3 "LATCH_CLOSING" 7 "LATCH_DEFAULT" 4 "LATCH_OPENING" 5 "LATCH_AJAR" 6 "LATCH_TIMEOUT" 0 "LATCH_SNA" ;
VAL_ 259 VCRIGHT_mirrorFoldState 4 "MIRROR_FOLD_STATE_UNFOLDING" 1 "MIRROR_FOLD_STATE_FOLDED" 3 "MIRROR_FOLD_STATE_FOLDING" 0 "MIRROR_FOLD_STATE_UNKNOWN" 2 "MIRROR_FOLD_STATE_UNFOLDED" ;
VAL_ 259 VCRIGHT_mirrorState 3 "MIRROR_STATE_FOLD_UNFOLD" 1 "MIRROR_STATE_TILT_X" 0 "MIRROR_STATE_IDLE" 2 "MIRROR_STATE_TILT_Y" 4 "MIRROR_STATE_RECALL" ;
VAL_ 259 VCRIGHT_rearLatchStatus 8 "LATCH_FAULT" 2 "LATCH_CLOSED" 1 "LATCH_OPENED" 3 "LATCH_CLOSING" 7 "LATCH_DEFAULT" 4 "LATCH_OPENING" 5 "LATCH_AJAR" 6 "LATCH_TIMEOUT" 0 "LATCH_SNA" ;
VAL_ 259 VCRIGHT_frontLatchStatus 8 "LATCH_FAULT" 2 "LATCH_CLOSED" 1 "LATCH_OPENED" 3 "LATCH_CLOSING" 7 "LATCH_DEFAULT" 4 "LATCH_OPENING" 5 "LATCH_AJAR" 6 "LATCH_TIMEOUT" 0 "LATCH_SNA" ;
VAL_ 1322 FC_alertType 0 "ALERT_CLEARED" 1 "ALERT_SET" ;
VAL_ 1322 FC_alertID 291 "FC_a291_GB_vehDataTimeout" 131 "FC_a131_CA_flyback_HW_OV" 155 "FC_a155_CA_evseToPcbDeltaLo" 284 "FC_a284_GB_pcbTempHiFoldBk" 180 "FC_a180_CA_chargingProblem" 177 "FC_a177_CA_bmsCtrCloseTimeout" 171 "FC_a171_CA_vehConLockTimeout" 288 "FC_a288_GB_isoVoltageLow" 294 "FC_a294_GB_evseDataTimeout" 185 "FC_a185_CA_vehReadyDeasserted" 257 "FC_a257_GB_bmsMia" 268 "FC_a268_GB_pcb_OT" 278 "FC_a278_GB_unused" 282 "FC_a282_GB_negTempHiFoldBk" 152 "FC_a152_CA_vehToPcbDeltaHi" 181 "FC_a181_CA_vRegBrownout" 158 "FC_a158_CA_evseOverCurrent" 308 "FC_a308_GB_evseConLockTimeout" 173 "FC_a173_CA_evseDataTimeout" 169 "FC_a169_CA_pilotAcceptTimeout" 310 "FC_a310_GB_vehicleIdTimeout" 183 "FC_a183_CA_evseBatIncompat" 297 "FC_a297_GB_chargingBusTimeout" 304 "FC_a304_GB_evseIncompatible" 303 "FC_a303_GB_negRecogTimeout" 287 "FC_a287_GB_vehConnUnlocked" 174 "FC_a174_CA_vehReadyTimeout" 273 "FC_a273_GB_negToPosDeltaLo" 129 "FC_a129_CA_flyback_HW_OC" 187 "FC_a187_CA_evseConLockTimeout" 279 "FC_a279_GB_evseOverCurrent" 133 "FC_a133_CA_evseMia" 184 "FC_a184_CA_evseBatMalfunc" 168 "FC_a168_CA_proxTimeout" 182 "FC_a182_CA_evseChrMalfunc" 272 "FC_a272_GB_negToPosDeltaHi" 142 "FC_a142_CA_evseConn_OT" 295 "FC_a295_GB_vehReadyTimeout" 289 "FC_a289_GB_proxTimeout" 266 "FC_a266_GB_negPin_OT" 305 "FC_a305_GB_posRecogTimeout" 148 "FC_a148_CA_evseConn_UT" 283 "FC_a283_GB_posTempHiFoldBk" 296 "FC_a296_GB_evseIsoTestTimeout" 292 "FC_a292_GB_vehConLockTimeout" 312 "FC_a312_GB_evseLimitsTimeout" 134 "FC_a134_CA_vehTxBufOvf" 130 "FC_a130_CA_flyback_SW_OV" 141 "FC_a141_CA_vehConn_OT" 138 "FC_a138_CA_hwProxTrip" 160 "FC_a160_CA_ss2Deasserted" 271 "FC_a271_GB_unused" 277 "FC_a277_GB_posToPcbDeltaLo" 135 "FC_a135_CA_vehRxBufOvf" 163 "FC_a163_CA_pcbTempHiFoldBk" 298 "FC_a298_GB_bmsCtrCloseTimeout" 299 "FC_a299_GB_evseReadyTimeout" 156 "FC_a156_CA_flybackRunTimeout" 302 "FC_a302_GB_vRegBrownout" 275 "FC_a275_GB_posToPcbDeltaHi" 140 "FC_a140_CA_bmsIncompatible" 306 "FC_a306_GB_vehReadyDeasserted" 259 "FC_a259_GB_vehTxBufOvf" 262 "FC_a262_GB_evseRxBufOvf" 150 "FC_a150_CA_vehToEvseDeltaHi" 162 "FC_a162_CA_evseTempHiFoldBk" 159 "FC_a159_CA_wdtExpired" 263 "FC_a263_GB_hwProxTrip" 321 "FC_a321_FCAlertPlaceholder" 261 "FC_a261_GB_evseTxBufOvf" 269 "FC_a269_GB_unused" 1 "FC_a001_scPostOutOfService" 193 "FC_a193_FCAlertPlaceholder" 175 "FC_a175_CA_evseIsoTestTimeout" 170 "FC_a170_CA_vehDataTimeout" 270 "FC_a270_GB_unused" 151 "FC_a151_CA_vehToEvseDeltaLo" 149 "FC_a149_CA_pcb_UT" 186 "FC_a186_CA_fcContOpenTimeout" 136 "FC_a136_CA_evseTxBufOvf" 265 "FC_a265_GB_bmsIncompatible" 286 "FC_a286_GB_evseConnUnlocked" 167 "FC_a167_CA_isoVoltageLow" 143 "FC_a143_CA_pcb_OT" 147 "FC_a147_CA_vehConn_UT" 267 "FC_a267_GB_posPin_OT" 264 "FC_a264_GB_ss2NotLow" 137 "FC_a137_CA_evseRxBufOvf" 281 "FC_a281_GB_ss2Deasserted" 285 "FC_a285_GB_proxDisconnected" 260 "FC_a260_GB_vehRxBufOvf" 276 "FC_a276_GB_negToPcbDeltaLo" 153 "FC_a153_CA_evseToPcbDeltaHi" 290 "FC_a290_GB_pilotAcceptTimeout" 301 "FC_a301_GB_chargingProblem" 132 "FC_a132_CA_bmsMia" 2 "FC_a002_scPowerShared" 172 "FC_a172_CA_ss2LowTimeout" 309 "FC_a309_GB_unused" 280 "FC_a280_GB_unused" 179 "FC_a179_CA_startupProblem" 274 "FC_a274_GB_negToPcbDeltaHi" 293 "FC_a293_GB_ss2LowTimeout" 154 "FC_a154_CA_vehToPcbDeltaLo" 300 "FC_a300_GB_startupProblem" 0 "FC_ALERT_DO_NOT_USE_ZERO" 165 "FC_a165_CA_evseConnUnlocked" 145 "FC_a145_CA_flybackDataStale" 164 "FC_a164_CA_proxDisconnected" 65 "FC_a065_userData" 166 "FC_a166_CA_vehConnUnlocked" 144 "FC_a144_CA_flybackUnstable" 307 "FC_a307_GB_fcContOpenTimeout" 157 "FC_a157_CA_unused" 176 "FC_a176_CA_chargingBusTimeout" 178 "FC_a178_CA_evseStartTimeout" 139 "FC_a139_CA_ss2NotLow" 311 "FC_a311_GB_battParamsTimeout" 161 "FC_a161_CA_vehTempHiFoldBk" 146 "FC_a146_CA_flybackBusLoadHi" 258 "FC_a258_GB_evseMia" ;
